VERSION "2021.24.4"

NS_ :

BS_:

BU_: VEH CH Receiver X

BO_ 964 PCS_info: 8 VEH
 SG_ PCS_infoIndex M: 0|8@1+ (1,0) [0|0] "" X
 SG_ PCS_buildType m10: 8|8@1+ (1,0) [0|0] "" X
 SG_ PCS_buildConfigId m10: 16|16@1+ (1,0) [0|0] "" X
 SG_ PCS_hardwareId m10: 32|16@1+ (1,0) [0|0] "" X
 SG_ PCS_componentId m10: 48|16@1+ (1,0) [0|0] "" X
 SG_ PCS_pcbaId m11: 16|8@1+ (1,0) [0|0] "" X
 SG_ PCS_assemblyId m11: 24|8@1+ (1,0) [0|0] "" X
 SG_ PCS_usageId m11: 32|16@1+ (1,0) [0|0] "" X
 SG_ PCS_subUsageId m11: 48|16@1+ (1,0) [0|0] "" X
 SG_ PCS_platformType m13: 8|8@1+ (1,0) [0|0] "" X
 SG_ PCS_appCrc m13: 32|32@1+ (1,0) [0|0] "" X
 SG_ PCS_cpu2AppCrc m16: 32|32@1+ (1,0) [0|0] "" X
 SG_ PCS_appGitHash m17: 10|54@1+ (4,0) [0|0] "" X
 SG_ PCS_bootGitHash m18: 10|54@1+ (4,0) [0|0] "" X
 SG_ PCS_bootUdsProtoVersion m20: 8|8@1+ (1,0) [0|0] "" X
 SG_ PCS_bootCrc m20: 32|32@1+ (1,0) [0|0] "" X
 SG_ PCS_partNumChar01 m25: 8|8@1+ (1,0) [0|0] "" X
 SG_ PCS_partNumChar02 m25: 16|8@1+ (1,0) [0|0] "" X
 SG_ PCS_partNumChar03 m25: 24|8@1+ (1,0) [0|0] "" X
 SG_ PCS_partNumChar04 m25: 32|8@1+ (1,0) [0|0] "" X
 SG_ PCS_partNumChar05 m25: 40|8@1+ (1,0) [0|0] "" X
 SG_ PCS_partNumChar06 m25: 48|8@1+ (1,0) [0|0] "" X
 SG_ PCS_partNumChar07 m25: 56|8@1+ (1,0) [0|0] "" X
 SG_ PCS_partNumChar08 m26: 8|8@1+ (1,0) [0|0] "" X
 SG_ PCS_partNumChar09 m26: 16|8@1+ (1,0) [0|0] "" X
 SG_ PCS_partNumChar10 m26: 24|8@1+ (1,0) [0|0] "" X
 SG_ PCS_partNumChar11 m26: 32|8@1+ (1,0) [0|0] "" X
 SG_ PCS_partNumChar12 m26: 40|8@1+ (1,0) [0|0] "" X
 SG_ PCS_partNumChar13 m26: 48|8@1+ (1,0) [0|0] "" X
 SG_ PCS_partNumChar14 m26: 56|8@1+ (1,0) [0|0] "" X
 SG_ PCS_partNumChar15 m27: 8|8@1+ (1,0) [0|0] "" X
 SG_ PCS_partNumChar16 m27: 16|8@1+ (1,0) [0|0] "" X
 SG_ PCS_partNumChar17 m27: 24|8@1+ (1,0) [0|0] "" X
 SG_ PCS_partNumChar18 m27: 32|8@1+ (1,0) [0|0] "" X
 SG_ PCS_partNumChar19 m27: 40|8@1+ (1,0) [0|0] "" X
 SG_ PCS_partNumChar20 m27: 48|8@1+ (1,0) [0|0] "" X
 SG_ PCS_serialNumChar01 m29: 8|8@1+ (1,0) [0|0] "" X
 SG_ PCS_serialNumChar02 m29: 16|8@1+ (1,0) [0|0] "" X
 SG_ PCS_serialNumChar03 m29: 24|8@1+ (1,0) [0|0] "" X
 SG_ PCS_serialNumChar04 m29: 32|8@1+ (1,0) [0|0] "" X
 SG_ PCS_serialNumChar05 m29: 40|8@1+ (1,0) [0|0] "" X
 SG_ PCS_serialNumChar06 m29: 48|8@1+ (1,0) [0|0] "" X
 SG_ PCS_serialNumChar07 m29: 56|8@1+ (1,0) [0|0] "" X
 SG_ PCS_serialNumChar08 m30: 8|8@1+ (1,0) [0|0] "" X
 SG_ PCS_serialNumChar09 m30: 16|8@1+ (1,0) [0|0] "" X
 SG_ PCS_serialNumChar10 m30: 24|8@1+ (1,0) [0|0] "" X
 SG_ PCS_serialNumChar11 m30: 32|8@1+ (1,0) [0|0] "" X
 SG_ PCS_serialNumChar12 m30: 40|8@1+ (1,0) [0|0] "" X
 SG_ PCS_serialNumChar13 m30: 48|8@1+ (1,0) [0|0] "" X
 SG_ PCS_serialNumChar14 m30: 56|8@1+ (1,0) [0|0] "" X

BO_ 708 PCS_logging: 8 VEH
 SG_ PCS_logMessageSelect M: 0|5@1+ (1,0) [0|0] "" X
 SG_ PCS_chgPhAInputIrms m0: 5|9@1+ (0.1,0) [0|0] "A" X
 SG_ PCS_chgPhAIntBusV m0: 14|9@1+ (1,0) [0|0] "V" X
 SG_ PCS_chgPhAIntBusVTarget m0: 23|9@1+ (1,0) [0|0] "V" X
 SG_ PCS_chgPhAOutputI m0: 32|8@1+ (0.1,0) [0|0] "A" X
 SG_ PCS_chgPhBInputIrms m1: 5|9@1+ (0.1,0) [0|0] "A" X
 SG_ PCS_chgPhBIntBusV m1: 14|9@1+ (1,0) [0|0] "V" X
 SG_ PCS_chgPhBIntBusVTarget m1: 23|9@1+ (1,0) [0|0] "V" X
 SG_ PCS_chgPhBOutputI m1: 32|8@1+ (0.1,0) [0|0] "A" X
 SG_ PCS_chgPhCInputIrms m2: 5|9@1+ (0.1,0) [0|0] "A" X
 SG_ PCS_chgPhCIntBusV m2: 14|9@1+ (1,0) [0|0] "V" X
 SG_ PCS_chgPhCIntBusVTarget m2: 23|9@1+ (1,0) [0|0] "V" X
 SG_ PCS_chgPhCOutputI m2: 32|8@1+ (0.1,0) [0|0] "A" X
 SG_ PCS_chgInputL1NVrms m3: 5|12@1+ (0.2,0) [0|0] "V" X
 SG_ PCS_chgInputL2NVrms m3: 17|12@1+ (0.2,0) [0|0] "V" X
 SG_ PCS_chgInputL3NVrms m3: 29|12@1+ (0.2,0) [0|0] "V" X
 SG_ PCS_chgInputL1L2Vrms m3: 41|12@1+ (0.2,0) [0|0] "V" X
 SG_ PCS_chgInputNGVrms m3: 53|9@1+ (1,0) [0|0] "V" X
 SG_ PCS_chgInputFrequencyL1N m4: 8|12@1+ (0.01,40) [0|0] "Hz" X
 SG_ PCS_chgInputFrequencyL2N m4: 20|12@1+ (0.01,40) [0|0] "Hz" X
 SG_ PCS_chgInputFrequencyL3N m4: 32|12@1+ (0.01,40) [0|0] "Hz" X
 SG_ PCS_chgInternalPhaseConfig m4: 44|3@1+ (1,0) [0|0] "" X
 SG_ PCS_chgOutputV m4: 48|12@1+ (0.146484,0) [0|0] "V" X
 SG_ PCS_chgPhAState m5: 5|4@1+ (1,0) [0|0] "" X
 SG_ PCS_chgPhBState m5: 9|4@1+ (1,0) [0|0] "" X
 SG_ PCS_chgPhCState m5: 13|4@1+ (1,0) [0|0] "" X
 SG_ PCS_chgPhALastShutdownReason m5: 17|5@1+ (1,0) [0|0] "" X
 SG_ PCS_chgPhBLastShutdownReason m5: 22|5@1+ (1,0) [0|0] "" X
 SG_ PCS_chgPhCLastShutdownReason m5: 27|5@1+ (1,0) [0|0] "" X
 SG_ PCS_chgPhARetryCount m5: 32|3@1+ (1,0) [0|0] "" X
 SG_ PCS_chgPhBRetryCount m5: 35|3@1+ (1,0) [0|0] "" X
 SG_ PCS_chgPhCRetryCount m5: 38|3@1+ (1,0) [0|0] "" X
 SG_ PCS_chgRetryCount m5: 41|3@1+ (1,0) [0|0] "" X
 SG_ PCS_chgPhManCurrentToDist m5: 44|10@1+ (0.1,0) [0|0] "A" X
 SG_ PCS_chgL1NPllLocked m5: 54|1@1+ (1,0) [0|0] "" X
 SG_ PCS_chgL2NPllLocked m5: 55|1@1+ (1,0) [0|0] "" X
 SG_ PCS_chgL3NPllLocked m5: 56|1@1+ (1,0) [0|0] "" X
 SG_ PCS_chgL1L2PllLocked m5: 57|1@1+ (1,0) [0|0] "" X
 SG_ PCS_chgNgPllLocked m5: 58|1@1+ (1,0) [0|0] "" X
 SG_ PCS_chgPhManOptimalPhsToUse m5: 59|2@1+ (1,0) [0|0] "" X
 SG_ PCS_chg5VL1Enable m5: 61|1@1+ (1,0) [0|0] "" X
 SG_ PCS_dcdcMaxLvOutputCurrent m6: 28|12@1+ (0.1,0) [0|0] "A" X
 SG_ PCS_dcdcCurrentLimit m6: 40|12@1+ (0.1,0) [0|0] "A" X
 SG_ PCS_dcdcLvOutputCurrentTempLimit m6: 52|12@1+ (0.1,0) [0|0] "A" X
 SG_ PCS_dcdcUnifiedCommand m7: 5|10@1+ (0.001,0) [0|0] "1" X
 SG_ PCS_dcdcCLAControllerOutput m7: 16|10@1+ (0.001,0) [0|0] "1" X
 SG_ PCS_dcdcTankVoltage m7: 26|11@1- (1,0) [0|0] "V" X
 SG_ PCS_dcdcTankVoltageTarget m7: 37|10@1+ (1,0) [0|0] "V" X
 SG_ PCS_dcdcClaCurrentFreq m7: 48|12@1+ (0.0976563,0) [0|0] "kHz" X
 SG_ PCS_dcdcTCommMeasured m8: 8|16@1- (0.00195313,0) [0|0] "us" X
 SG_ PCS_dcdcShortTimeUs m8: 24|16@1+ (0.000488281,0) [0|0] "us" X
 SG_ PCS_dcdcHalfPeriodUs m8: 40|16@1+ (0.000488281,0) [0|0] "us" X
 SG_ PCS_cpu2BootState m9: 5|2@1+ (1,0) [0|0] "" X
 SG_ PCS_acChargeSelfTestState m9: 7|1@1+ (1,0) [0|0] "" X
 SG_ PCS_1V5Min10s m9: 8|11@1+ (0.001,0) [0|0] "V" X
 SG_ PCS_1V5Max10s m9: 19|11@1+ (0.001,0) [0|0] "V" X
 SG_ PCS_1V2Min10s m9: 32|11@1+ (0.001,0) [0|0] "V" X
 SG_ PCS_1V2Max10s m9: 43|11@1+ (0.001,0) [0|0] "V" X
 SG_ PCS_numAlertsSet m9: 56|7@1+ (1,0) [0|0] "" X
 SG_ PCS_chgPhAIntBusVMin10s m10: 5|9@1+ (1,0) [0|0] "V" X
 SG_ PCS_chgPhAIntBusVMax10s m10: 14|9@1+ (1,0) [0|0] "V" X
 SG_ PCS_chgPhAPchgVoltDeltaMax10s m10: 23|8@1+ (0.5,0) [0|0] "V" X
 SG_ PCS_chgPhALifetimekWh m10: 31|24@1+ (0.01,0) [0|0] "kWh" X
 SG_ PCS_chgPhATransientRetryCount m10: 55|9@1+ (0.1,0) [0|0] "-" X
 SG_ PCS_chgPhBIntBusVMin10s m11: 5|9@1+ (1,0) [0|0] "V" X
 SG_ PCS_chgPhBIntBusVMax10s m11: 14|9@1+ (1,0) [0|0] "V" X
 SG_ PCS_chgPhBPchgVoltDeltaMax10s m11: 23|8@1+ (0.5,0) [0|0] "V" X
 SG_ PCS_chgPhBLifetimekWh m11: 31|24@1+ (0.01,0) [0|0] "kWh" X
 SG_ PCS_chgPhBTransientRetryCount m11: 55|9@1+ (0.1,0) [0|0] "-" X
 SG_ PCS_chgPhCIntBusVMin10s m12: 5|9@1+ (1,0) [0|0] "V" X
 SG_ PCS_chgPhCIntBusVMax10s m12: 14|9@1+ (1,0) [0|0] "V" X
 SG_ PCS_chgPhCPchgVoltDeltaMax10s m12: 23|8@1+ (0.5,0) [0|0] "V" X
 SG_ PCS_chgPhCLifetimekWh m12: 31|24@1+ (0.01,0) [0|0] "kWh" X
 SG_ PCS_chgPhCTransientRetryCount m12: 55|9@1+ (0.1,0) [0|0] "-" X
 SG_ PCS_chgInputL1NVPeak10s m13: 5|9@1+ (1,0) [0|0] "V" X
 SG_ PCS_chgInputL2NVPeak10s m13: 14|9@1+ (1,0) [0|0] "V" X
 SG_ PCS_chgInputL3NVPeak10s m13: 23|9@1+ (1,0) [0|0] "V" X
 SG_ PCS_chgInputFreqWobblePHAPeak m13: 32|8@1+ (0.01,0) [0|0] "Hz" X
 SG_ PCS_chgInputFreqWobblePHBPeak m13: 40|8@1+ (0.01,0) [0|0] "Hz" X
 SG_ PCS_chgInputFreqWobblePHCPeak m13: 48|8@1+ (0.01,0) [0|0] "Hz" X
 SG_ PCS_dLogPhAChannel1Content m14: 5|2@1+ (1,0) [0|0] "" X
 SG_ PCS_dLogPhBChannel1Content m14: 8|2@1+ (1,0) [0|0] "" X
 SG_ PCS_dLogPhCChannel1Content m14: 10|2@1+ (1,0) [0|0] "" X
 SG_ PCS_dLogPhAChannel1Data m14: 16|16@1- (0.02,0) [0|0] "-" X
 SG_ PCS_dLogPhBChannel1Data m14: 32|16@1- (0.02,0) [0|0] "-" X
 SG_ PCS_dLogPhCChannel1Data m14: 48|16@1- (0.02,0) [0|0] "-" X
 SG_ PCS_dLogPhAChannel2Content m15: 5|2@1+ (1,0) [0|0] "" X
 SG_ PCS_dLogPhBChannel2Content m15: 8|2@1+ (1,0) [0|0] "" X
 SG_ PCS_dLogPhCChannel2Content m15: 10|2@1+ (1,0) [0|0] "" X
 SG_ PCS_dLogPhAChannel2Data m15: 16|16@1- (0.02,0) [0|0] "-" X
 SG_ PCS_dLogPhBChannel2Data m15: 32|16@1- (0.02,0) [0|0] "-" X
 SG_ PCS_dLogPhCChannel2Data m15: 48|16@1- (0.02,0) [0|0] "-" X
 SG_ PCS_dLogPhAChannel3Content m16: 5|2@1+ (1,0) [0|0] "" X
 SG_ PCS_dLogPhBChannel3Content m16: 8|2@1+ (1,0) [0|0] "" X
 SG_ PCS_dLogPhCChannel3Content m16: 10|2@1+ (1,0) [0|0] "" X
 SG_ PCS_dLogPhAChannel3Data m16: 16|16@1- (0.02,0) [0|0] "-" X
 SG_ PCS_dLogPhBChannel3Data m16: 32|16@1- (0.02,0) [0|0] "-" X
 SG_ PCS_dLogPhCChannel3Data m16: 48|16@1- (0.02,0) [0|0] "-" X
 SG_ PCS_dLogPhAChannel4Content m17: 5|2@1+ (1,0) [0|0] "" X
 SG_ PCS_dLogPhBChannel4Content m17: 8|2@1+ (1,0) [0|0] "" X
 SG_ PCS_dLogPhCChannel4Content m17: 10|2@1+ (1,0) [0|0] "" X
 SG_ PCS_dLogPhAChannel4Data m17: 16|16@1- (0.02,0) [0|0] "-" X
 SG_ PCS_dLogPhBChannel4Data m17: 32|16@1- (0.02,0) [0|0] "-" X
 SG_ PCS_dLogPhCChannel4Data m17: 48|16@1- (0.02,0) [0|0] "-" X
 SG_ PCS_dcdcIntervalMaxFrequency m18: 8|12@1+ (1,0) [0|0] "kHz" X
 SG_ PCS_dcdcIntervalMaxHvBusVolt m18: 24|13@1+ (0.1,0) [0|0] "V" X
 SG_ PCS_dcdcIntervalMaxLvBusVolt m18: 37|9@1+ (0.1,0) [0|0] "V" X
 SG_ PCS_dcdcIntervalMaxLvOutputCurr m18: 48|12@1+ (1,0) [0|0] "A" X
 SG_ PCS_dcdcIntervalMinFrequency m19: 8|12@1+ (1,0) [0|0] "kHz" X
 SG_ PCS_dcdcIntervalMinHvBusVolt m19: 24|13@1+ (0.1,0) [0|0] "V" X
 SG_ PCS_dcdcIntervalMinLvBusVolt m19: 37|9@1+ (0.1,0) [0|0] "V" X
 SG_ PCS_dcdcIntervalMinLvOutputCurr m19: 48|12@1+ (1,0) [0|0] "A" X
 SG_ PCS_chgPhANoFlowBucket m20: 5|9@1+ (0.01,0) [0|0] "-" X
 SG_ PCS_chgPhBNoFlowBucket m20: 14|9@1+ (0.01,0) [0|0] "-" X
 SG_ PCS_chgPhCNoFlowBucket m20: 23|9@1+ (0.01,0) [0|0] "-" X
 SG_ PCS_chgInputL1NVdc m21: 5|10@1- (1,0) [0|0] "V" X
 SG_ PCS_chgInputL2NVdc m21: 16|10@1- (1,0) [0|0] "V" X
 SG_ PCS_chgInputL3NVdc m21: 26|10@1- (1,0) [0|0] "V" X
 SG_ PCS_chgInputL1L2Vdc m21: 36|10@1- (1,0) [0|0] "V" X
 SG_ PCS_chgInputNGVdc m21: 46|10@1- (1,0) [0|0] "V" X
 SG_ PCS_dcdc12vSupportLifetimekWh m22: 8|24@1+ (0.01,0) [0|0] "kWh" X

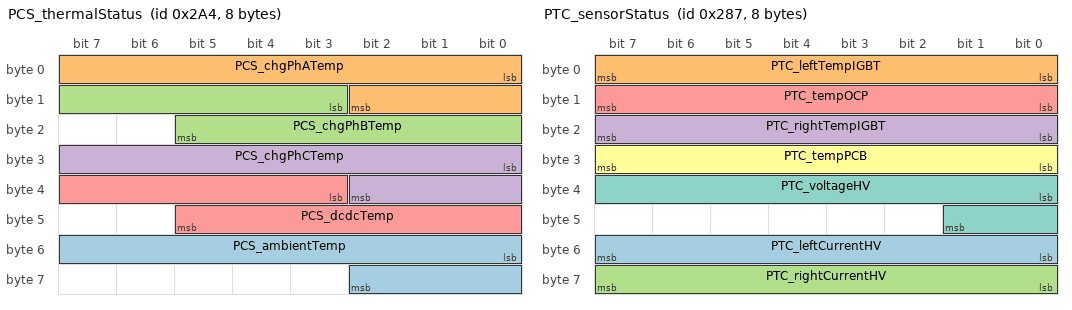
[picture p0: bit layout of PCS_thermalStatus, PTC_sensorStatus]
BO_ 676 PCS_thermalStatus: 8 VEH
 SG_ PCS_ambientTemp: 48|11@1- (0.1,40) [0|0] "C" X
 SG_ PCS_chgPhATemp: 0|11@1- (0.1,40) [0|0] "C" X
 SG_ PCS_chgPhBTemp: 11|11@1- (0.1,40) [0|0] "C" X
 SG_ PCS_chgPhCTemp: 24|11@1- (0.1,40) [0|0] "C" X
 SG_ PCS_dcdcTemp: 35|11@1- (0.1,40) [0|0] "C" X

BO_ 900 PMS_alertMatrix1: 8 VEH
 SG_ PMS_w001_absoluteTorque: 0|1@1+ (1,0) [0|0] "" X
 SG_ PMS_w002_accumulatedTorque: 1|1@1+ (1,0) [0|0] "" X
 SG_ PMS_w003_torqueReversal: 2|1@1+ (1,0) [0|0] "" X
 SG_ PMS_w004_regenTorque: 3|1@1+ (1,0) [0|0] "" X
 SG_ PMS_w005_torqueInNeutral: 4|1@1+ (1,0) [0|0] "" X
 SG_ PMS_w006_inconsistentDIGear: 5|1@1+ (1,0) [0|0] "" X
 SG_ PMS_w007_watchdogReset: 6|1@1+ (1,0) [0|0] "" X
 SG_ PMS_w008_memoryError: 7|1@1+ (1,0) [0|0] "" X
 SG_ PMS_w009_espMIA: 8|1@1+ (1,0) [0|0] "" X
 SG_ PMS_w010_diMIA: 9|1@1+ (1,0) [0|0] "" X
 SG_ PMS_w011_phaseCurrentIrrational: 10|1@1+ (1,0) [0|0] "" X
 SG_ PMS_w012_canDataBusA: 11|1@1+ (1,0) [0|0] "" X
 SG_ PMS_w013_canHardwareBusA: 12|1@1+ (1,0) [0|0] "" X
 SG_ PMS_w018_encoderIrrational: 17|1@1+ (1,0) [0|0] "" X
 SG_ PMS_w019_statorTempIrrational: 18|1@1+ (1,0) [0|0] "" X
 SG_ PMS_w026_diHeartBeatMIA: 25|1@1+ (1,0) [0|0] "" X
 SG_ PMS_w027_torqueOutOfMap: 26|1@1+ (1,0) [0|0] "" X
 SG_ PMS_w028_torqueCmdError: 27|1@1+ (1,0) [0|0] "" X
 SG_ PMS_w031_highStackUsage: 30|1@1+ (1,0) [0|0] "" X
 SG_ PMS_w032_registerConfigError: 31|1@1+ (1,0) [0|0] "" X
 SG_ PMS_w033_selfTest: 32|1@1+ (1,0) [0|0] "" X
 SG_ PMS_w034_trqCrossCheck: 33|1@1+ (1,0) [0|0] "" X
 SG_ PMS_w038_inconsistentTorqueSign: 37|1@1+ (1,0) [0|0] "" X
 SG_ PMS_w039_disMIA: 38|1@1+ (1,0) [0|0] "" X
 SG_ PMS_w040_pmMIA: 39|1@1+ (1,0) [0|0] "" X
 SG_ PMS_w042_gtwMIA: 41|1@1+ (1,0) [0|0] "" X
 SG_ PMS_w043_inconsistentConfig: 42|1@1+ (1,0) [0|0] "" X
 SG_ PMS_w045_motorMovementDetected: 44|1@1+ (1,0) [0|0] "" X
 SG_ PMS_w053_vcfrontMIA: 52|1@1+ (1,0) [0|0] "" X
 SG_ PMS_w054_uiMIA: 53|1@1+ (1,0) [0|0] "" X
 SG_ PMS_w055_resolver: 54|1@1+ (1,0) [0|0] "" X
 SG_ PMS_w056_canHardwareBusB: 55|1@1+ (1,0) [0|0] "" X
 SG_ PMS_w057_canDataBusB: 56|1@1+ (1,0) [0|0] "" X
 SG_ PMS_w061_DIPMVersionMismatch: 60|1@1+ (1,0) [0|0] "" X
 SG_ PMS_w063_debugAlert: 62|1@1+ (1,0) [0|0] "" X
 SG_ PMS_w064_torqueIntervention: 63|1@1+ (1,0) [0|0] "" X

BO_ 1748 PMS_info: 8 VEH
 SG_ PMS_infoIndex M: 0|8@1+ (1,0) [0|0] "" X
 SG_ PMS_buildType m10: 8|8@1+ (1,0) [0|0] "" X
 SG_ PMS_buildConfigurationId m10: 16|16@1+ (1,0) [0|0] "" X
 SG_ PMS_hardwareId m10: 32|8@1+ (1,0) [0|0] "" X
 SG_ PMS_componentId m10: 48|16@1+ (1,0) [0|0] "" X
 SG_ PMS_pcbaId m11: 16|8@1+ (1,0) [0|0] "" X
 SG_ PMS_assemblyId m11: 24|8@1+ (1,0) [0|0] "" X
 SG_ PMS_usageId m11: 32|16@1+ (1,0) [0|0] "" X
 SG_ PMS_subUsageId m11: 48|16@1+ (1,0) [0|0] "" X
 SG_ PMS_applicationCrc m13: 32|32@1+ (1,0) [0|0] "" X
 SG_ PMS_bootloaderSvnRevision m14: 8|24@1+ (1,0) [0|0] "" X
 SG_ PMS_bootloaderSvnUrlHash m14: 32|32@1+ (1,0) [0|0] "" X
 SG_ PMS_appGitHash m17: 10|54@1+ (4,0) [0|0] "" X
 SG_ PMS_bootGitHash m18: 10|54@1+ (4,0) [0|0] "" X
 SG_ PMS_platformTyp m19: 8|8@1+ (1,0) [0|0] "" X
 SG_ PMS_udsProtocolVersion m20: 8|8@1+ (1,0) [0|0] "" X
 SG_ PMS_bootloaderCrc m20: 32|32@1+ (1,0) [0|0] "" X

BO_ 772 PM_alertMatrix1: 8 VEH
 SG_ PM_a001_absoluteTorque: 0|1@1+ (1,0) [0|0] "" X
 SG_ PM_a002_accumulatedTorque: 1|1@1+ (1,0) [0|0] "" X
 SG_ PM_a003_torqueReversal: 2|1@1+ (1,0) [0|0] "" X
 SG_ PM_a004_regenTorque: 3|1@1+ (1,0) [0|0] "" X
 SG_ PM_a005_torqueInNeutral: 4|1@1+ (1,0) [0|0] "" X
 SG_ PM_a006_inconsistentDIGear: 5|1@1+ (1,0) [0|0] "" X
 SG_ PM_a007_watchdogReset: 6|1@1+ (1,0) [0|0] "" X
 SG_ PM_a008_memoryError: 7|1@1+ (1,0) [0|0] "" X
 SG_ PM_a009_espMIA: 8|1@1+ (1,0) [0|0] "" X
 SG_ PM_a010_diMIA: 9|1@1+ (1,0) [0|0] "" X
 SG_ PM_a011_phaseCurrentIrrational: 10|1@1+ (1,0) [0|0] "" X
 SG_ PM_a012_canDataBusA: 11|1@1+ (1,0) [0|0] "" X
 SG_ PM_a013_canHardwareBusA: 12|1@1+ (1,0) [0|0] "" X
 SG_ PM_a014_accelPedalError: 13|1@1+ (1,0) [0|0] "" X
 SG_ PM_a015_shifterMIA: 14|1@1+ (1,0) [0|0] "" X
 SG_ PM_a016_cruiseMIA: 15|1@1+ (1,0) [0|0] "" X
 SG_ PM_a017_brakeMIA: 16|1@1+ (1,0) [0|0] "" X
 SG_ PM_a018_encoderIrrational: 17|1@1+ (1,0) [0|0] "" X
 SG_ PM_a019_statorTempIrrational: 18|1@1+ (1,0) [0|0] "" X
 SG_ PM_a023_crsCmdOffStateOn: 22|1@1+ (1,0) [0|0] "" X
 SG_ PM_a024_brakeIrrational: 23|1@1+ (1,0) [0|0] "" X
 SG_ PM_a026_diHeartBeatMIA: 25|1@1+ (1,0) [0|0] "" X
 SG_ PM_a027_torqueOutOfMap: 26|1@1+ (1,0) [0|0] "" X
 SG_ PM_a028_torqueCmdError: 27|1@1+ (1,0) [0|0] "" X
 SG_ PM_a030_inconsistentAebState: 29|1@1+ (1,0) [0|0] "" X
 SG_ PM_a031_highStackUsage: 30|1@1+ (1,0) [0|0] "" X
 SG_ PM_a032_registerConfigError: 31|1@1+ (1,0) [0|0] "" X
 SG_ PM_a033_selfTest: 32|1@1+ (1,0) [0|0] "" X
 SG_ PM_a034_trqCrossCheck: 33|1@1+ (1,0) [0|0] "" X
 SG_ PM_a038_inconsistentTorqueSign: 37|1@1+ (1,0) [0|0] "" X
 SG_ PM_a039_disMIA: 38|1@1+ (1,0) [0|0] "" X
 SG_ PM_a040_pmMIA: 39|1@1+ (1,0) [0|0] "" X
 SG_ PM_a041_dasMIA: 40|1@1+ (1,0) [0|0] "" X
 SG_ PM_a042_gtwMIA: 41|1@1+ (1,0) [0|0] "" X
 SG_ PM_a043_inconsistentConfig: 42|1@1+ (1,0) [0|0] "" X
 SG_ PM_a044_ebrIntervention: 43|1@1+ (1,0) [0|0] "" X
 SG_ PM_a045_motorMovementDetected: 44|1@1+ (1,0) [0|0] "" X
 SG_ PM_a046_inconsVehicleHoldState: 45|1@1+ (1,0) [0|0] "" X
 SG_ PM_a047_inconsAutoparkState: 46|1@1+ (1,0) [0|0] "" X
 SG_ PM_a048_stabilityControlInhibit: 47|1@1+ (1,0) [0|0] "" X
 SG_ PM_a049_stbCtrlInWrongDir: 48|1@1+ (1,0) [0|0] "" X
 SG_ PM_a050_excessiveStbCtrlTrq: 49|1@1+ (1,0) [0|0] "" X
 SG_ PM_a051_unintDecelStbCtrl: 50|1@1+ (1,0) [0|0] "" X
 SG_ PM_a052_stbCtrlDrvrDecelCflct: 51|1@1+ (1,0) [0|0] "" X
 SG_ PM_a053_vcfrontMIA: 52|1@1+ (1,0) [0|0] "" X
 SG_ PM_a054_uiMIA: 53|1@1+ (1,0) [0|0] "" X
 SG_ PM_a055_resolver: 54|1@1+ (1,0) [0|0] "" X
 SG_ PM_a056_canHardwareBusB: 55|1@1+ (1,0) [0|0] "" X
 SG_ PM_a057_canDataBusB: 56|1@1+ (1,0) [0|0] "" X
 SG_ PM_a058_cmpMIA: 57|1@1+ (1,0) [0|0] "" X
 SG_ PM_a059_ptcMIA: 58|1@1+ (1,0) [0|0] "" X
 SG_ PM_a061_DIPMVersionMismatch: 60|1@1+ (1,0) [0|0] "" X
 SG_ PM_a063_debugAlert: 62|1@1+ (1,0) [0|0] "" X
 SG_ PM_a064_torqueIntervention: 63|1@1+ (1,0) [0|0] "" X

BO_ 790 PM_info: 8 VEH
 SG_ PM_infoIndex M: 0|8@1+ (1,0) [0|0] "" X
 SG_ PM_buildType m10: 8|8@1+ (1,0) [0|0] "" X
 SG_ PM_buildConfigurationId m10: 16|16@1+ (1,0) [0|0] "" X
 SG_ PM_hardwareId m10: 32|8@1+ (1,0) [0|0] "" X
 SG_ PM_componentId m10: 48|16@1+ (1,0) [0|0] "" X
 SG_ PM_pcbaId m11: 16|8@1+ (1,0) [0|0] "" X
 SG_ PM_assemblyId m11: 24|8@1+ (1,0) [0|0] "" X
 SG_ PM_usageId m11: 32|16@1+ (1,0) [0|0] "" X
 SG_ PM_subUsageId m11: 48|16@1+ (1,0) [0|0] "" X
 SG_ PM_applicationCrc m13: 32|32@1+ (1,0) [0|0] "" X
 SG_ PM_bootloaderSvnRevision m14: 8|24@1+ (1,0) [0|0] "" X
 SG_ PM_bootloaderSvnUrlHash m14: 32|32@1+ (1,0) [0|0] "" X
 SG_ PM_appGitHash m17: 10|54@1+ (4,0) [0|0] "" X
 SG_ PM_bootGitHash m18: 10|54@1+ (4,0) [0|0] "" X
 SG_ PM_platformTyp m19: 8|8@1+ (1,0) [0|0] "" X
 SG_ PM_udsProtocolVersion m20: 8|8@1+ (1,0) [0|0] "" X
 SG_ PM_bootloaderCrc m20: 32|32@1+ (1,0) [0|0] "" X

BO_ 837 PTC_info: 8 VEH
 SG_ PTC_infoIndex M: 0|8@1+ (1,0) [0|0] "" X
 SG_ PTC_infoBuildType m10: 8|3@1+ (1,0) [0|0] "" X
 SG_ PTC_infoBuildConfigId m10: 16|16@1+ (1,0) [0|0] "" X
 SG_ PTC_infoHardwareId m10: 32|16@1+ (1,0) [0|0] "" X
 SG_ PTC_infoComponentId m10: 48|16@1+ (1,0) [0|0] "" X
 SG_ PTC_infoPcbaId m11: 16|8@1+ (1,0) [0|0] "" X
 SG_ PTC_infoAssemblyId m11: 24|8@1+ (1,0) [0|0] "" X
 SG_ PTC_infoUsageId m11: 32|16@1+ (1,0) [0|0] "" X
 SG_ PTC_infoSubUsageId m11: 48|16@1+ (1,0) [0|0] "" X
 SG_ PTC_infoBootUdsProtoVersion m20: 8|8@1+ (1,0) [0|0] "" X
 SG_ PTC_infoBootCrc m20: 32|32@1+ (1,0) [0|0] "" X
 SG_ PTC_infoPlatformType m13: 8|8@1+ (1,0) [0|0] "" X
 SG_ PTC_infoAppCrc m13: 32|32@1+ (1,0) [0|0] "" X

BO_ 647 PTC_sensorStatus: 8 VEH
 SG_ PTC_leftCurrentHV: 48|8@1+ (0.2,0) [0|0] "A" X
 SG_ PTC_leftTempIGBT: 0|8@1+ (1,-40) [0|0] "degC" X
 SG_ PTC_rightCurrentHV: 56|8@1+ (0.2,0) [0|0] "A" X
 SG_ PTC_rightTempIGBT: 16|8@1+ (1,-40) [0|0] "degC" X
 SG_ PTC_tempOCP: 8|8@1+ (1,-40) [0|0] "degC" X
 SG_ PTC_tempPCB: 24|8@1+ (1,-40) [0|0] "degC" X
 SG_ PTC_voltageHV: 32|10@1+ (0.5,0) [0|0] "V" X

BO_ 1282 RADC_alertMatrix0: 8 CH
 SG_ RADC_a001_can1BusOff: 1|1@1+ (1,0) [0|0] "" X
 SG_ RADC_a002_ecuAdcError: 2|1@1+ (1,0) [0|0] "" X
 SG_ RADC_a003_ecuBistDisabled: 3|1@1+ (1,0) [0|0] "" X
 SG_ RADC_a004_ecuCrcHwError: 4|1@1+ (1,0) [0|0] "" X
 SG_ RADC_a005_ecuEcuMError: 5|1@1+ (1,0) [0|0] "" X
 SG_ RADC_a006_ecuFimError: 6|1@1+ (1,0) [0|0] "" X
 SG_ RADC_a007_ecuGptCheckError: 7|1@1+ (1,0) [0|0] "" X
 SG_ RADC_a008_ecuHwSwInterlock: 8|1@1+ (1,0) [0|0] "" X
 SG_ RADC_a009_plantModeActive: 9|1@1+ (1,0) [0|0] "" X
 SG_ RADC_a010_ecuIoHwAbError: 10|1@1+ (1,0) [0|0] "" X
 SG_ RADC_a011_ecuMcemError: 11|1@1+ (1,0) [0|0] "" X
 SG_ RADC_a012_ecuSpiError: 12|1@1+ (1,0) [0|0] "" X
 SG_ RADC_a013_ecuWdgError: 13|1@1+ (1,0) [0|0] "" X
 SG_ RADC_a014_fctSelfTestNotDone: 14|1@1+ (1,0) [0|0] "" X
 SG_ RADC_a015_fctSenInterference: 15|1@1+ (1,0) [0|0] "" X
 SG_ RADC_a016_adcOverVolt: 16|1@1+ (1,0) [0|0] "" X
 SG_ RADC_a017_adcUnderVolt: 17|1@1+ (1,0) [0|0] "" X
 SG_ RADC_a018_internalHardwareFault: 18|1@1+ (1,0) [0|0] "" X
 SG_ RADC_a019_internalSoftwareFault: 19|1@1+ (1,0) [0|0] "" X
 SG_ RADC_a020_overTemp: 20|1@1+ (1,0) [0|0] "" X
 SG_ RADC_a021_overTempCrit: 21|1@1+ (1,0) [0|0] "" X
 SG_ RADC_a022_tempImplausible: 22|1@1+ (1,0) [0|0] "" X
 SG_ RADC_a023_underTemp: 23|1@1+ (1,0) [0|0] "" X
 SG_ RADC_a024_underTempCrit: 24|1@1+ (1,0) [0|0] "" X
 SG_ RADC_a025_overVoltage: 25|1@1+ (1,0) [0|0] "" X
 SG_ RADC_a026_underVoltage: 26|1@1+ (1,0) [0|0] "" X
 SG_ RADC_a027_nvmFailure: 27|1@1+ (1,0) [0|0] "" X
 SG_ RADC_a028_rfChipError: 28|1@1+ (1,0) [0|0] "" X
 SG_ RADC_a029_rhcError: 29|1@1+ (1,0) [0|0] "" X
 SG_ RADC_a030_rspError: 30|1@1+ (1,0) [0|0] "" X
 SG_ RADC_a031_sensorMisaligned: 31|1@1+ (1,0) [0|0] "" X
 SG_ RADC_a032_sensorBlocked: 32|1@1+ (1,0) [0|0] "" X
 SG_ RADC_a033_sensorNeverAligned: 33|1@1+ (1,0) [0|0] "" X
 SG_ RADC_a034_vehDynamicsError: 34|1@1+ (1,0) [0|0] "" X
 SG_ RADC_a035_vinMIA: 35|1@1+ (1,0) [0|0] "" X
 SG_ RADC_a036_carConfigMIA: 36|1@1+ (1,0) [0|0] "" X
 SG_ RADC_a037_inertialSignalsMIA: 37|1@1+ (1,0) [0|0] "" X
 SG_ RADC_a038_steeringWheelAngleMIA: 38|1@1+ (1,0) [0|0] "" X
 SG_ RADC_a039_vehicleStateMIA: 39|1@1+ (1,0) [0|0] "" X
 SG_ RADC_a040_wheelSpeedsMIA: 40|1@1+ (1,0) [0|0] "" X
 SG_ RADC_a041_vinErr: 41|1@1+ (1,0) [0|0] "" X
 SG_ RADC_a042_carConfigErr: 42|1@1+ (1,0) [0|0] "" X
 SG_ RADC_a043_inertialSignalsErr: 43|1@1+ (1,0) [0|0] "" X
 SG_ RADC_a044_steeringWheelAngleErr: 44|1@1+ (1,0) [0|0] "" X
 SG_ RADC_a045_vehicleStateErr: 45|1@1+ (1,0) [0|0] "" X
 SG_ RADC_a046_wheelSpeedsErr: 46|1@1+ (1,0) [0|0] "" X
 SG_ RADC_a047_mismatchChassisType: 47|1@1+ (1,0) [0|0] "" X
 SG_ RADC_a048_mismatchAirSuspension: 48|1@1+ (1,0) [0|0] "" X
 SG_ RADC_a049_mismatchFourWheelDrive: 49|1@1+ (1,0) [0|0] "" X
 SG_ RADC_a050_mismatchCountry: 50|1@1+ (1,0) [0|0] "" X
 SG_ RADC_a051_mismatchEPASType: 51|1@1+ (1,0) [0|0] "" X
 SG_ RADC_a052_mismatcRadPos: 52|1@1+ (1,0) [0|0] "" X
 SG_ RADC_a053_emError: 53|1@1+ (1,0) [0|0] "" X
 SG_ RADC_a054_blockageInfo_Frame_1: 54|1@1+ (1,0) [0|0] "" X
 SG_ RADC_a055_blockageInfo_Frame_2: 55|1@1+ (1,0) [0|0] "" X

BO_ 1329 RADC_info: 8 CH
 SG_ RADC_infoIndex M: 0|8@1+ (1,0) [0|0] "" X
 SG_ RADC_infoPlatformType m19: 8|8@1+ (1,0) [0|0] "" X
 SG_ RADC_infoMajorVersion m19: 16|8@1+ (1,0) [0|0] "" X
 SG_ RADC_infoBranchOrigin m19: 24|8@1+ (1,0) [0|0] "" X
 SG_ RADC_infoMaturity m19: 32|8@1+ (1,0) [0|0] "" X
 SG_ RADC_infoHardwareRevision m19: 40|8@1+ (1,0) [0|0] "" X
 SG_ RADC_infoBuildType m10: 8|8@1+ (1,0) [0|0] "" X
 SG_ RADC_infoBuildConfigID m10: 16|16@1+ (1,0) [0|0] "" X
 SG_ RADC_infoHardwareID m10: 32|16@1+ (1,0) [0|0] "" X
 SG_ RADC_infoComponentID m10: 48|16@1+ (1,0) [0|0] "" X
 SG_ RADC_infoPcbaID m11: 16|8@1+ (1,0) [0|0] "" X
 SG_ RADC_infoAssemblyID m11: 24|8@1+ (1,0) [0|0] "" X
 SG_ RADC_infoUsageID m11: 32|16@1+ (1,0) [0|0] "" X
 SG_ RADC_infoSubUsageID m11: 48|16@1+ (1,0) [0|0] "" X
 SG_ RADC_infoBootUdsProtoVersion m20: 8|8@1+ (1,0) [0|0] "" X
 SG_ RADC_infoBootloaderCRC m20: 32|32@1+ (1,0) [0|0] "" X
 SG_ RADC_infoApplicationCRC m13: 32|32@1+ (1,0) [0|0] "" X

BO_ 881 RCM_alertMatrix: 8 VEH
 SG_ RCM_matrixIndex M: 0|4@1+ (1,0) [0|0] "" X
 SG_ RCM_a000_crashDetected m0: 4|1@1+ (1,0) [0|0] "" X
 SG_ RCM_a001_nearDeploy m0: 5|1@1+ (1,0) [0|0] "" X
 SG_ RCM_a002_airbagsNotArmed m0: 6|1@1+ (1,0) [0|0] "" X
 SG_ RCM_a003_warningIndicator m0: 7|1@1+ (1,0) [0|0] "" X
 SG_ RCM_a004_internalFault m0: 8|1@1+ (1,0) [0|0] "" X
 SG_ RCM_a005_crcError m0: 9|1@1+ (1,0) [0|0] "" X
 SG_ RCM_a006_batteryVoltageRange m0: 10|1@1+ (1,0) [0|0] "" X
 SG_ RCM_a007_powerSupplyExternal m0: 11|1@1+ (1,0) [0|0] "" X
 SG_ RCM_a008_powerSupplyInternal m0: 12|1@1+ (1,0) [0|0] "" X
 SG_ RCM_a009_reprogramLimit m0: 13|1@1+ (1,0) [0|0] "" X
 SG_ RCM_a010_scmDisabled m0: 14|1@1+ (1,0) [0|0] "" X
 SG_ RCM_a011_eepromDataLocked m0: 15|1@1+ (1,0) [0|0] "" X
 SG_ RCM_a012_vinStorage m0: 16|1@1+ (1,0) [0|0] "" X
 SG_ RCM_a013_driverOrientation m0: 17|1@1+ (1,0) [0|0] "" X
 SG_ RCM_a014_driverABStage1 m0: 18|1@1+ (1,0) [0|0] "" X
 SG_ RCM_a015_driverABStage2 m0: 19|1@1+ (1,0) [0|0] "" X
 SG_ RCM_a016_passABStage1 m0: 20|1@1+ (1,0) [0|0] "" X
 SG_ RCM_a017_passABStage2 m0: 21|1@1+ (1,0) [0|0] "" X
 SG_ RCM_a018_passengerActiveVent m0: 22|1@1+ (1,0) [0|0] "" X
 SG_ RCM_a019_pretenShldrFrontLeft m0: 23|1@1+ (1,0) [0|0] "" X
 SG_ RCM_a020_pretenShldFrontRight m0: 24|1@1+ (1,0) [0|0] "" X
 SG_ RCM_a021_pretenLapFrontLeft m0: 25|1@1+ (1,0) [0|0] "" X
 SG_ RCM_a022_pretenLapFrontRight m0: 26|1@1+ (1,0) [0|0] "" X
 SG_ RCM_a023_loadLimiterLeftSide m0: 27|1@1+ (1,0) [0|0] "" X
 SG_ RCM_a024_loadLimiterRightSide m0: 28|1@1+ (1,0) [0|0] "" X
 SG_ RCM_a025_kneeABDriver m0: 29|1@1+ (1,0) [0|0] "" X
 SG_ RCM_a026_kneeABFrontPassenger m0: 30|1@1+ (1,0) [0|0] "" X
 SG_ RCM_a027_sideAB1stRowLeft m0: 31|1@1+ (1,0) [0|0] "" X
 SG_ RCM_a028_sideAB1stRowRight m0: 32|1@1+ (1,0) [0|0] "" X
 SG_ RCM_a029_driverABActiveVent m0: 33|1@1+ (1,0) [0|0] "" X
 SG_ RCM_a030_farSideInboardAirbag m0: 34|1@1+ (1,0) [0|0] "" X
 SG_ RCM_a031_frontCenterAirbag m0: 35|1@1+ (1,0) [0|0] "" X
 SG_ RCM_a032_curtainABLeft m0: 36|1@1+ (1,0) [0|0] "" X
 SG_ RCM_a033_curtainABRight m0: 37|1@1+ (1,0) [0|0] "" X
 SG_ RCM_a034_preten2ndRowLeft m0: 38|1@1+ (1,0) [0|0] "" X
 SG_ RCM_a035_preten2ndRowRight m0: 39|1@1+ (1,0) [0|0] "" X
 SG_ RCM_a036_curAB2ndRowLeft m0: 40|1@1+ (1,0) [0|0] "" X
 SG_ RCM_a037_curAB2ndRowRight m0: 41|1@1+ (1,0) [0|0] "" X
 SG_ RCM_a038_unusedA m0: 42|1@1+ (1,0) [0|0] "" X
 SG_ RCM_a039_unusedB m0: 43|1@1+ (1,0) [0|0] "" X
 SG_ RCM_a040_hoodActuatorRight m0: 44|1@1+ (1,0) [0|0] "" X
 SG_ RCM_a041_hoodActuatorLeft m0: 45|1@1+ (1,0) [0|0] "" X
 SG_ RCM_a042_ens1Line m0: 46|1@1+ (1,0) [0|0] "" X
 SG_ RCM_a043_ens2Line m0: 47|1@1+ (1,0) [0|0] "" X
 SG_ RCM_a044_upFrontSensorLeft m0: 48|1@1+ (1,0) [0|0] "" X
 SG_ RCM_a045_upFrontSensorRight m0: 49|1@1+ (1,0) [0|0] "" X
 SG_ RCM_a046_sideAccelBPillarLeft m0: 50|1@1+ (1,0) [0|0] "" X
 SG_ RCM_a047_sideAccelBPillarRight m0: 51|1@1+ (1,0) [0|0] "" X
 SG_ RCM_a048_sideAccelCPillarLeft m0: 52|1@1+ (1,0) [0|0] "" X
 SG_ RCM_a049_sideAccelCPillarRight m0: 53|1@1+ (1,0) [0|0] "" X
 SG_ RCM_a050_upFrontSensorCenter m0: 54|1@1+ (1,0) [0|0] "" X
 SG_ RCM_a051_pressureFrontLftDoor m0: 55|1@1+ (1,0) [0|0] "" X
 SG_ RCM_a052_pressureFrontRtDoor m0: 56|1@1+ (1,0) [0|0] "" X
 SG_ RCM_a053_pressurePedProLeft m0: 57|1@1+ (1,0) [0|0] "" X
 SG_ RCM_a054_pressurePedProRight m0: 58|1@1+ (1,0) [0|0] "" X
 SG_ RCM_a055_inertialMeasurement m0: 59|1@1+ (1,0) [0|0] "" X
 SG_ RCM_a056_passengerFrontOCS m0: 60|1@1+ (1,0) [0|0] "" X
 SG_ RCM_a057_driverOCS m0: 61|1@1+ (1,0) [0|0] "" X
 SG_ RCM_a058_buckle1stRowLeft m0: 62|1@1+ (1,0) [0|0] "" X
 SG_ RCM_a059_buckle1stRowRight m0: 63|1@1+ (1,0) [0|0] "" X
 SG_ RCM_a060_stpsLeft m1: 4|1@1+ (1,0) [0|0] "" X
 SG_ RCM_a061_stpsRight m1: 5|1@1+ (1,0) [0|0] "" X
 SG_ RCM_a062_alrSwitch m1: 6|1@1+ (1,0) [0|0] "" X
 SG_ RCM_a063_sbsw2ndRowRight m1: 7|1@1+ (1,0) [0|0] "" X
 SG_ RCM_a064_hardwareCodingPin1 m1: 8|1@1+ (1,0) [0|0] "" X
 SG_ RCM_a065_driverOrientConfigPin m1: 9|1@1+ (1,0) [0|0] "" X
 SG_ RCM_a066_seatBackSw2ndRowLeft m1: 10|1@1+ (1,0) [0|0] "" X
 SG_ RCM_a067_comCANInitFailure m1: 11|1@1+ (1,0) [0|0] "" X
 SG_ RCM_a068_comCHOff m1: 12|1@1+ (1,0) [0|0] "" X
 SG_ RCM_a069_comCHCANPH7 m1: 13|1@1+ (1,0) [0|0] "" X
 SG_ RCM_a070_comCHCANPH8 m1: 14|1@1+ (1,0) [0|0] "" X
 SG_ RCM_a071_comCHCANPH9 m1: 15|1@1+ (1,0) [0|0] "" X
 SG_ RCM_a072_comUnused m1: 16|1@1+ (1,0) [0|0] "" X
 SG_ RCM_a073_comCHCANPH4 m1: 17|1@1+ (1,0) [0|0] "" X
 SG_ RCM_a074_comCHCANPH5 m1: 18|1@1+ (1,0) [0|0] "" X
 SG_ RCM_a075_comCHCANPH6 m1: 19|1@1+ (1,0) [0|0] "" X
 SG_ RCM_a076_comEPBLStatus m1: 20|1@1+ (1,0) [0|0] "" X
 SG_ RCM_a077_comEPBRStatus m1: 21|1@1+ (1,0) [0|0] "" X
 SG_ RCM_a078_comOCS1PStatus m1: 22|1@1+ (1,0) [0|0] "" X
 SG_ RCM_a079_comOCS1DStatus m1: 23|1@1+ (1,0) [0|0] "" X
 SG_ RCM_a080_comGTWACS m1: 24|1@1+ (1,0) [0|0] "" X
 SG_ RCM_a081_comVCFRONTLVPwr m1: 25|1@1+ (1,0) [0|0] "" X
 SG_ RCM_a082_comUIodo m1: 26|1@1+ (1,0) [0|0] "" X
 SG_ RCM_a083_comGTWCarState m1: 27|1@1+ (1,0) [0|0] "" X
 SG_ RCM_a084_comTPMSStatus m1: 28|1@1+ (1,0) [0|0] "" X
 SG_ RCM_a085_comGTWCarConfig m1: 29|1@1+ (1,0) [0|0] "" X
 SG_ RCM_a086_comVINMIA m1: 30|1@1+ (1,0) [0|0] "" X
 SG_ RCM_a087_comCANSilent m1: 31|1@1+ (1,0) [0|0] "" X
 SG_ RCM_a088_comCHCANPH2 m1: 32|1@1+ (1,0) [0|0] "" X
 SG_ RCM_a089_comCHCANPH3 m1: 33|1@1+ (1,0) [0|0] "" X
 SG_ RCM_a090_comPartyBusOff m1: 34|1@1+ (1,0) [0|0] "" X
 SG_ RCM_a091_comEPAS3PsysStatus m1: 35|1@1+ (1,0) [0|0] "" X
 SG_ RCM_a092_comDASISF m1: 36|1@1+ (1,0) [0|0] "" X
 SG_ RCM_a093_comVCLEFTStatus m1: 37|1@1+ (1,0) [0|0] "" X
 SG_ RCM_a094_comVCRIGHTStatus m1: 38|1@1+ (1,0) [0|0] "" X
 SG_ RCM_a095_comESPstatus m1: 39|1@1+ (1,0) [0|0] "" X
 SG_ RCM_a096_comESPwheelSpeeds m1: 40|1@1+ (1,0) [0|0] "" X
 SG_ RCM_a097_comDIspeed m1: 41|1@1+ (1,0) [0|0] "" X
 SG_ RCM_a098_comDIchassisControl m1: 42|1@1+ (1,0) [0|0] "" X
 SG_ RCM_a099_comDItorque m1: 43|1@1+ (1,0) [0|0] "" X
 SG_ RCM_a100_comDIsystemStatus m1: 44|1@1+ (1,0) [0|0] "" X
 SG_ RCM_a101_idfSystem m1: 45|1@1+ (1,0) [0|0] "" X
 SG_ RCM_a102_imuYawR8OffstCompLim m1: 46|1@1+ (1,0) [0|0] "" X
 SG_ RCM_a103_imuPtchR8OffstCompLim m1: 47|1@1+ (1,0) [0|0] "" X
 SG_ RCM_a104_imuRollR8OffstCompLim m1: 48|1@1+ (1,0) [0|0] "" X
 SG_ RCM_a105_imuLongAccOffstCompLim m1: 49|1@1+ (1,0) [0|0] "" X
 SG_ RCM_a106_imuLatAccOffstCompLim m1: 50|1@1+ (1,0) [0|0] "" X
 SG_ RCM_a107_imuVertAccOffstCompLim m1: 51|1@1+ (1,0) [0|0] "" X
 SG_ RCM_a108_crashAlgoWakeup m1: 52|1@1+ (1,0) [0|0] "" X
 SG_ RCM_a109_abuseImmunity m1: 53|1@1+ (1,0) [0|0] "" X
 SG_ RCM_a110_factoryMode m1: 54|1@1+ (1,0) [0|0] "" X
 SG_ RCM_a111_diagnosticsEnabled m1: 55|1@1+ (1,0) [0|0] "" X
 SG_ RCM_a112_imuYawRate m1: 56|1@1+ (1,0) [0|0] "" X
 SG_ RCM_a113_imuPitchRate m1: 57|1@1+ (1,0) [0|0] "" X
 SG_ RCM_a114_imuRollRate m1: 58|1@1+ (1,0) [0|0] "" X
 SG_ RCM_a115_imuLinearAcceleration m1: 59|1@1+ (1,0) [0|0] "" X
 SG_ RCM_a116_imuLateralAcceleration m1: 60|1@1+ (1,0) [0|0] "" X
 SG_ RCM_a117_imuVerticalAcceleration m1: 61|1@1+ (1,0) [0|0] "" X
 SG_ RCM_a118_imuInPlaneAcceleration m1: 62|1@1+ (1,0) [0|0] "" X

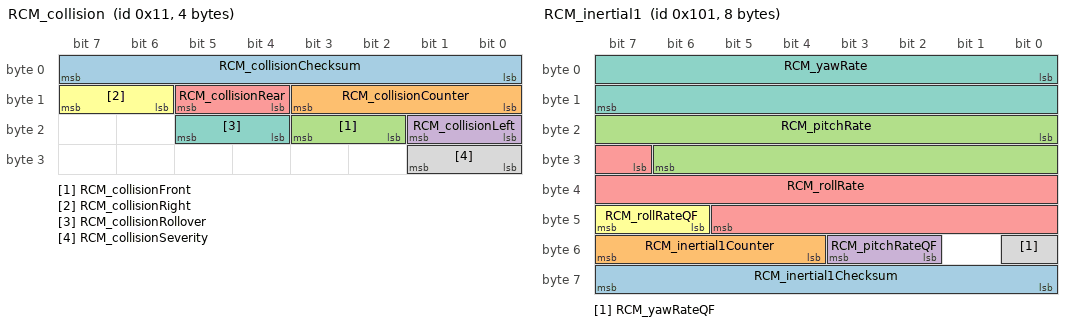
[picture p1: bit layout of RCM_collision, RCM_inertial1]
BO_ 17 RCM_collision: 4 VEH
 SG_ RCM_collisionChecksum: 0|8@1+ (1,0) [0|0] "" X
 SG_ RCM_collisionCounter: 8|4@1+ (1,0) [0|0] "" X
 SG_ RCM_collisionFront: 18|2@1+ (1,0) [0|0] "" X
 SG_ RCM_collisionLeft: 16|2@1+ (1,0) [0|0] "" X
 SG_ RCM_collisionRear: 12|2@1+ (1,0) [0|0] "" X
 SG_ RCM_collisionRight: 14|2@1+ (1,0) [0|0] "" X
 SG_ RCM_collisionRollover: 20|2@1+ (1,0) [0|0] "" X
 SG_ RCM_collisionSeverity: 24|2@1+ (1,0) [0|0] "" X

BO_ 257 RCM_inertial1: 8 CH
 SG_ RCM_inertial1Checksum: 56|8@1+ (1,0) [0|0] "" X
 SG_ RCM_inertial1Counter: 52|4@1+ (1,0) [0|0] "" X
 SG_ RCM_pitchRate: 16|15@1- (0.00025,0) [0|0] "rad/s" X
 SG_ RCM_pitchRateQF: 50|2@1+ (1,0) [0|0] "" X
 SG_ RCM_rollRate: 31|15@1- (0.00025,0) [0|0] "rad/s" X
 SG_ RCM_rollRateQF: 46|2@1+ (1,0) [0|0] "" X
 SG_ RCM_yawRate: 0|16@1- (0.0001,0) [0|0] "rad/s" X
 SG_ RCM_yawRateQF: 48|1@1+ (1,0) [0|0] "" X

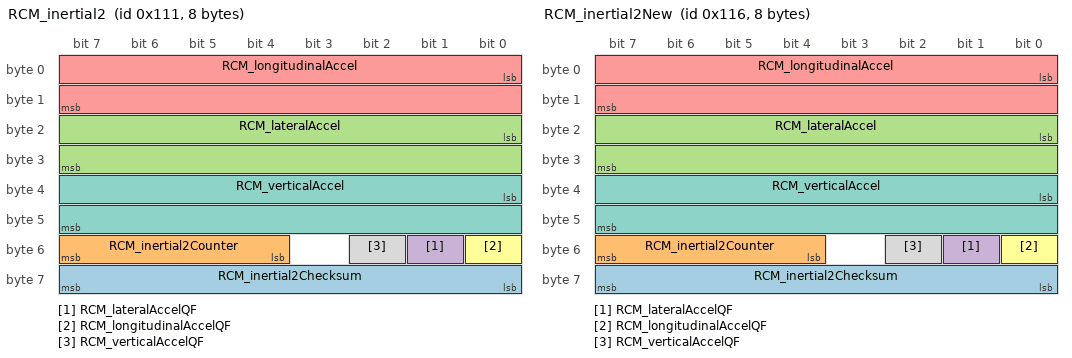
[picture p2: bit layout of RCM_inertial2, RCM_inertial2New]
BO_ 273 RCM_inertial2: 8 CH
 SG_ RCM_inertial2Checksum : 56|8@1+ (1,0) [0|255] "" X
 SG_ RCM_inertial2Counter : 52|4@1+ (1,0) [0|15] "" X
 SG_ RCM_lateralAccel : 16|16@1- (0.00125,0) [-40.9575|40.9575] "m/s^2" X
 SG_ RCM_lateralAccelQF : 49|1@1+ (1,0) [0|1] ""  X
 SG_ RCM_longitudinalAccel : 0|16@1- (0.00125,0) [-40.9575|40.9575] "m/s^2" X
 SG_ RCM_longitudinalAccelQF : 48|1@1+ (1,0) [0|1] "" X
 SG_ RCM_verticalAccel : 32|16@1- (0.00125,0) [-40.9575|40.9575] "m/s^2" X
 SG_ RCM_verticalAccelQF : 50|1@1+ (1,0) [0|1] ""  X

BO_ 278 RCM_inertial2New: 8 CH
 SG_ RCM_inertial2Checksum : 56|8@1+ (1,0) [0|255] ""  Receiver
 SG_ RCM_inertial2Counter : 52|4@1+ (1,0) [0|15] ""  Receiver
 SG_ RCM_lateralAccel : 16|16@1- (0.00125,0) [-40.9575|40.9575] "m/s^2"  Receiver
 SG_ RCM_lateralAccelQF : 49|1@1+ (1,0) [0|1] ""  Receiver
 SG_ RCM_longitudinalAccel : 0|16@1- (0.00125,0) [-40.9575|40.9575] "m/s^2"  Receiver
 SG_ RCM_longitudinalAccelQF : 48|1@1+ (1,0) [0|1] ""  Receiver
 SG_ RCM_verticalAccel : 32|16@1- (0.00125,0) [-40.9575|40.9575] "m/s^2"  Receiver
 SG_ RCM_verticalAccelQF : 50|1@1+ (1,0) [0|1] ""  Receiver

BO_ 849 RCM_info: 8 CH
 SG_ RCM_infoIndex M: 0|8@1+ (1,0) [0|0] "" X
 SG_ RCM_infoBuildType m10: 8|8@1+ (1,0) [0|0] "" X
 SG_ RCM_infoComponentID m10: 48|16@1+ (1,0) [0|0] "" X
 SG_ RCM_infoPcbaID m11: 16|8@1+ (1,0) [0|0] "" X
 SG_ RCM_infoAssemblyID m11: 24|8@1+ (1,0) [0|0] "" X
 SG_ RCM_infoUsageID m11: 32|16@1+ (1,0) [0|0] "" X
 SG_ RCM_infoBootUdsProtoVersion m20: 8|8@1+ (1,0) [0|0] "" X
 SG_ RCM_infoBootloaderCRC m20: 32|32@1+ (1,0) [0|0] "" X
 SG_ RCM_infoApplicationCRC m13: 32|32@1+ (1,0) [0|0] "" X
 SG_ RCM_infoVariantCRC m22: 32|32@1+ (1,0) [0|0] "" X

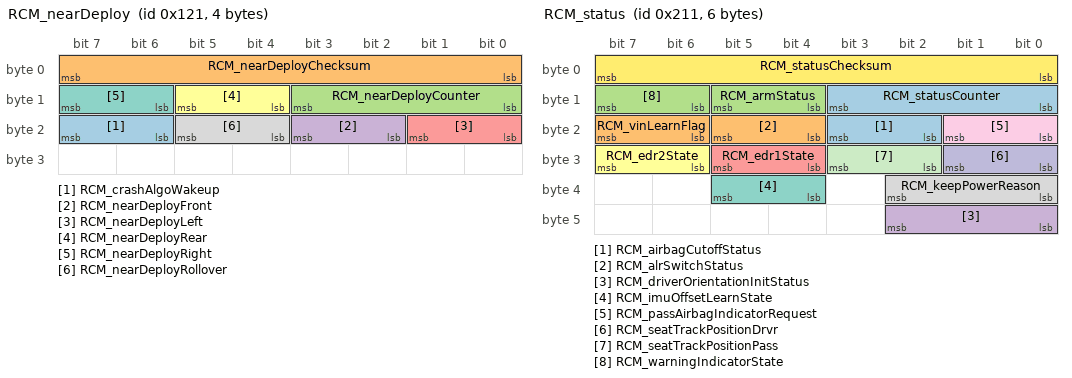
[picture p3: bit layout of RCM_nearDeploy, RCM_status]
BO_ 289 RCM_nearDeploy: 4 VEH
 SG_ RCM_crashAlgoWakeup: 22|2@1+ (1,0) [0|0] "" X
 SG_ RCM_nearDeployChecksum: 0|8@1+ (1,0) [0|0] "" X
 SG_ RCM_nearDeployCounter: 8|4@1+ (1,0) [0|0] "" X
 SG_ RCM_nearDeployFront: 18|2@1+ (1,0) [0|0] "" X
 SG_ RCM_nearDeployLeft: 16|2@1+ (1,0) [0|0] "" X
 SG_ RCM_nearDeployRear: 12|2@1+ (1,0) [0|0] "" X
 SG_ RCM_nearDeployRight: 14|2@1+ (1,0) [0|0] "" X
 SG_ RCM_nearDeployRollover: 20|2@1+ (1,0) [0|0] "" X

BO_ 529 RCM_status: 6 VEH
 SG_ RCM_airbagCutoffStatus: 18|2@1+ (1,0) [0|0] "" X
 SG_ RCM_alrSwitchStatus: 20|2@1+ (1,0) [0|0] "" X
 SG_ RCM_armStatus: 12|2@1+ (1,0) [0|0] "" X
 SG_ RCM_driverOrientationInitStatus: 40|3@1+ (1,0) [0|0] "" X
 SG_ RCM_edr1State: 28|2@1+ (1,0) [0|0] "" X
 SG_ RCM_edr2State: 30|2@1+ (1,0) [0|0] "" X
 SG_ RCM_imuOffsetLearnState: 36|2@1+ (1,0) [0|0] "" X
 SG_ RCM_keepPowerReason: 32|3@1+ (1,0) [0|0] "" X
 SG_ RCM_passAirbagIndicatorRequest: 16|2@1+ (1,0) [0|0] "" X
 SG_ RCM_seatTrackPositionDrvr: 24|2@1+ (1,0) [0|0] "" X
 SG_ RCM_seatTrackPositionPass: 26|2@1+ (1,0) [0|0] "" X
 SG_ RCM_statusChecksum: 0|8@1+ (1,0) [0|0] "" X
 SG_ RCM_statusCounter: 8|4@1+ (1,0) [0|0] "" X
 SG_ RCM_vinLearnFlag: 22|2@1+ (1,0) [0|0] "" X
 SG_ RCM_warningIndicatorState: 14|2@1+ (1,0) [0|0] "" X

BO_ 1359 SCCM_alertMatrix: 8 VEH
 SG_ SCCM_matrixIndex M: 0|4@1+ (1,0) [0|0] "" X
 SG_ SCCM_a001_CANBusOff m0: 4|1@1+ (1,0) [0|0] "" X
 SG_ SCCM_a002_CANTOut m0: 5|1@1+ (1,0) [0|0] "" X
 SG_ SCCM_a003_highBeamOpen m0: 6|1@1+ (1,0) [0|0] "" X
 SG_ SCCM_a004_highBeamShortToGND m0: 7|1@1+ (1,0) [0|0] "" X
 SG_ SCCM_a005_tipWipeOpen m0: 8|1@1+ (1,0) [0|0] "" X
 SG_ SCCM_a006_tipWipeShortToGND m0: 9|1@1+ (1,0) [0|0] "" X
 SG_ SCCM_a007_turnIndComInfo m0: 10|1@1+ (1,0) [0|0] "" X
 SG_ SCCM_a008_turnIndInvalidTrans m0: 11|1@1+ (1,0) [0|0] "" X
 SG_ SCCM_a009_turnIndOpen m0: 12|1@1+ (1,0) [0|0] "" X
 SG_ SCCM_a010_turnIndShortToGnd m0: 13|1@1+ (1,0) [0|0] "" X
 SG_ SCCM_a011_turnIndHWErr m0: 14|1@1+ (1,0) [0|0] "" X
 SG_ SCCM_a012_turnGenErr m0: 15|1@1+ (1,0) [0|0] "" X
 SG_ SCCM_a013_voltageHigh m0: 16|1@1+ (1,0) [0|0] "" X
 SG_ SCCM_a014_voltageLow m0: 17|1@1+ (1,0) [0|0] "" X
 SG_ SCCM_a015_softwareError m0: 18|1@1+ (1,0) [0|0] "" X
 SG_ SCCM_a016_hardwareError m0: 19|1@1+ (1,0) [0|0] "" X
 SG_ SCCM_a017_memoryError m0: 20|1@1+ (1,0) [0|0] "" X
 SG_ SCCM_a018_angleSpeedOutOfRange m0: 21|1@1+ (1,0) [0|0] "" X
 SG_ SCCM_a019_angleSpeedAboveLimit m0: 22|1@1+ (1,0) [0|0] "" X
 SG_ SCCM_a020_angleInternalError m0: 23|1@1+ (1,0) [0|0] "" X
 SG_ SCCM_a021_gearStalkSignalInvalid m0: 24|1@1+ (1,0) [0|0] "" X
 SG_ SCCM_a022_gearStalkOpenCircuit m0: 25|1@1+ (1,0) [0|0] "" X
 SG_ SCCM_a023_gearStalkShortCircuit m0: 26|1@1+ (1,0) [0|0] "" X
 SG_ SCCM_a024_gearStalkGenErr m0: 27|1@1+ (1,0) [0|0] "" X
 SG_ SCCM_a025_runTimeError m0: 28|1@1+ (1,0) [0|0] "" X
 SG_ SCCM_a026_parkButtonInvalidSignal m0: 29|1@1+ (1,0) [0|0] "" X
 SG_ SCCM_a027_parkButtonOpenCircuit m0: 30|1@1+ (1,0) [0|0] "" X
 SG_ SCCM_a028_parkButtonShortToGround m0: 31|1@1+ (1,0) [0|0] "" X
 SG_ SCCM_a029_parkButtonMalfunction m0: 32|1@1+ (1,0) [0|0] "" X

BO_ 816 SCCM_info: 8 VEH
 SG_ SCCM_infoIndex M: 0|8@1+ (1,0) [0|0] "" X
 SG_ SCCM_infoBuildType m10: 8|8@1+ (1,0) [0|0] "" X
 SG_ SCCM_infoBuildConfigId m10: 16|16@1+ (1,0) [0|0] "" X
 SG_ SCCM_infoHardwareId m10: 32|16@1+ (1,0) [0|0] "" X
 SG_ SCCM_infoComponentId m10: 48|16@1+ (1,0) [0|0] "" X
 SG_ SCCM_infoPcbaId m11: 16|8@1+ (1,0) [0|0] "" X
 SG_ SCCM_infoAssemblyId m11: 24|8@1+ (1,0) [0|0] "" X
 SG_ SCCM_infoUsageId m11: 32|16@1+ (1,0) [0|0] "" X
 SG_ SCCM_infoSubUsageId m11: 48|16@1+ (1,0) [0|0] "" X
 SG_ SCCM_infoPlatformType m13: 8|8@1+ (1,0) [0|0] "" X
 SG_ SCCM_infoAppCrc m13: 32|32@0+ (1,0) [0|0] "" X
 SG_ SCCM_infoBootSvnRev m14: 8|24@1+ (1,0) [0|0] "" X
 SG_ SCCM_infoBootSvnUrlHash m14: 32|32@1+ (1,0) [0|0] "" X
 SG_ SCCM_infoSubcomponent1Version m16: 16|32@1+ (1,0) [0|0] "" X
 SG_ SCCM_infoAppSvnHash m17: 10|54@1+ (4,0) [0|0] "" X
 SG_ SCCM_infoBootSvnHash m18: 10|54@1+ (4,0) [0|0] "" X
 SG_ SCCM_infoUdsProtoVersion m20: 8|8@1+ (1,0) [0|0] "" X
 SG_ SCCM_infoBootCrc m20: 32|32@1+ (1,0) [0|0] "" X

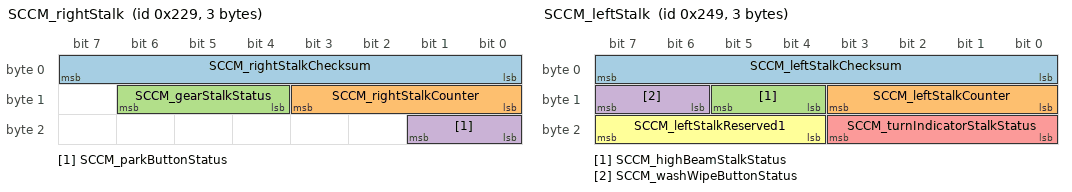
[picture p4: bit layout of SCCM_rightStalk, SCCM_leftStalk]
BO_ 553 SCCM_rightStalk: 3 VEH
 SG_ SCCM_rightStalkChecksum: 0|8@1+ (1,0) [0|0] "" X
 SG_ SCCM_rightStalkCounter: 8|4@1+ (1,0) [0|0] "" X
 SG_ SCCM_gearStalkStatus: 12|3@1+ (1,0) [0|7] "" X
 SG_ SCCM_parkButtonStatus: 16|2@1+ (1,0) [0|3] "" X

BO_ 585 SCCM_leftStalk: 3 VEH
 SG_ SCCM_leftStalkChecksum: 0|8@1+ (1,0) [0|0] "" X
 SG_ SCCM_leftStalkCounter: 8|4@1+ (1,0) [0|0] "" X
 SG_ SCCM_highBeamStalkStatus: 12|2@1+ (1,0) [0|0] "" X
 SG_ SCCM_washWipeButtonStatus: 14|2@1+ (1,0) [0|0] "" X
 SG_ SCCM_turnIndicatorStalkStatus: 16|4@1+ (1,0) [0|0] "" X
 SG_ SCCM_leftStalkReserved1: 20|4@1+ (1,0) [0|0] "" X

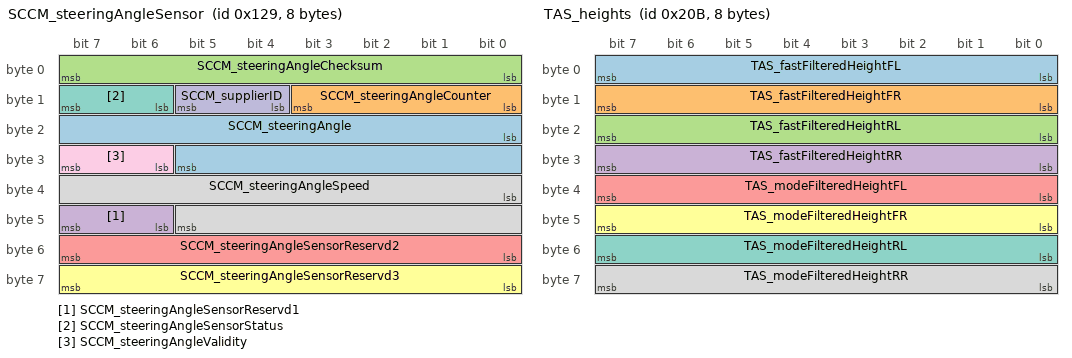
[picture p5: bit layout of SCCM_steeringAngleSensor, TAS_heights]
BO_ 297 SCCM_steeringAngleSensor: 8 VEH
 SG_ SCCM_steeringAngle: 16|14@1+ (0.1,-819.2) [0|0] "deg" X
 SG_ SCCM_steeringAngleCounter: 8|4@1+ (1,0) [0|0] "" X
 SG_ SCCM_steeringAngleChecksum: 0|8@1+ (1,0) [0|0] "" X
 SG_ SCCM_steeringAngleSensorReservd1: 46|2@1+ (1,0) [0|0] "" X
 SG_ SCCM_steeringAngleSensorReservd2: 48|8@1+ (1,0) [0|0] "" X
 SG_ SCCM_steeringAngleSensorReservd3: 56|8@1+ (1,0) [0|0] "" X
 SG_ SCCM_steeringAngleSensorStatus: 14|2@1+ (1,0) [0|0] "" X
 SG_ SCCM_steeringAngleSpeed: 32|14@1+ (0.5,-4096) [0|0] "deg/s" X
 SG_ SCCM_steeringAngleValidity: 30|2@1+ (1,0) [0|0] "" X
 SG_ SCCM_supplierID: 12|2@1+ (1,0) [0|0] "" X

BO_ 815 SCM_alertMatrix1: 8 CH
 SG_ SCM_a001_hwDSPfault: 0|1@1+ (1,0) [0|0] "" X
 SG_ SCM_a002_hwIbatOC: 1|1@1+ (1,0) [0|0] "" X
 SG_ SCM_a003_hwCordOT: 2|1@1+ (1,0) [0|0] "" X
 SG_ SCM_a004_hwVbusOV: 3|1@1+ (1,0) [0|0] "" X
 SG_ SCM_a005_hwHVIL: 4|1@1+ (1,0) [0|0] "" X
 SG_ SCM_a006_hwWeld_V1: 5|1@1+ (1,0) [0|0] "" X
 SG_ SCM_a007_hwWeld_V2: 6|1@1+ (1,0) [0|0] "" X
 SG_ SCM_a008_hwOpen_V1: 7|1@1+ (1,0) [0|0] "" X
 SG_ SCM_a009_hwOpen_V2: 8|1@1+ (1,0) [0|0] "" X
 SG_ SCM_a010_hwIllegalCntrCmdV1: 9|1@1+ (1,0) [0|0] "" X
 SG_ SCM_a011_hwIllegalCntrCmdInt: 10|1@1+ (1,0) [0|0] "" X
 SG_ SCM_a012_hwIllegalCntrCmdV2: 11|1@1+ (1,0) [0|0] "" X
 SG_ SCM_a013_cordTempHiFoldBk: 12|1@1+ (1,0) [0|0] "" X
 SG_ SCM_a014_coolantTempHiFoldBk: 13|1@1+ (1,0) [0|0] "" X
 SG_ SCM_a015_unusedHW15: 14|1@1+ (1,0) [0|0] "" X
 SG_ SCM_a016_unusedHW16: 15|1@1+ (1,0) [0|0] "" X
 SG_ SCM_a017_unusedHW17: 16|1@1+ (1,0) [0|0] "" X
 SG_ SCM_a018_unusedHW18: 17|1@1+ (1,0) [0|0] "" X
 SG_ SCM_a019_unusedHW19: 18|1@1+ (1,0) [0|0] "" X
 SG_ SCM_a020_unusedHW20: 19|1@1+ (1,0) [0|0] "" X
 SG_ SCM_a021_unusedHW21: 20|1@1+ (1,0) [0|0] "" X
 SG_ SCM_a022_fastChargeLimitActiveV1: 21|1@1+ (1,0) [0|0] "" X
 SG_ SCM_a023_fastChargeLimitActiveV2: 22|1@1+ (1,0) [0|0] "" X
 SG_ SCM_a024_emergencyShutdown: 23|1@1+ (1,0) [0|0] "" X
 SG_ SCM_a025_internalIsolationFault: 24|1@1+ (1,0) [0|0] "" X
 SG_ SCM_a026_internalIsolationLow: 25|1@1+ (1,0) [0|0] "" X
 SG_ SCM_a027_externalIsolationLow: 26|1@1+ (1,0) [0|0] "" X
 SG_ SCM_a028_isolationRationality: 27|1@1+ (1,0) [0|0] "" X
 SG_ SCM_a029_VbatOV: 28|1@1+ (1,0) [0|0] "" X
 SG_ SCM_a030_VbusOV: 29|1@1+ (1,0) [0|0] "" X
 SG_ SCM_a031_IbatOC: 30|1@1+ (1,0) [0|0] "" X
 SG_ SCM_a032_VBatRationality: 31|1@1+ (1,0) [0|0] "" X
 SG_ SCM_a033_VBusRationality: 32|1@1+ (1,0) [0|0] "" X
 SG_ SCM_a034_IBatRationality: 33|1@1+ (1,0) [0|0] "" X
 SG_ SCM_a035_unexpectedVbusBehavior: 34|1@1+ (1,0) [0|0] "" X
 SG_ SCM_a036_internalContactorWelded: 35|1@1+ (1,0) [0|0] "" X
 SG_ SCM_a037_outputContactorWelded: 36|1@1+ (1,0) [0|0] "" X
 SG_ SCM_a038_contactorFailedOpen: 37|1@1+ (1,0) [0|0] "" X
 SG_ SCM_a039_ibatRegulation: 38|1@1+ (1,0) [0|0] "" X
 SG_ SCM_a040_plus12VOutOfRange: 39|1@1+ (1,0) [0|0] "" X
 SG_ SCM_a041_minus12VOutOfRange: 40|1@1+ (1,0) [0|0] "" X
 SG_ SCM_a042_pilotOutOfRange: 41|1@1+ (1,0) [0|0] "" X
 SG_ SCM_a043_pilotRationality: 42|1@1+ (1,0) [0|0] "" X
 SG_ SCM_a044_proximityRationality: 43|1@1+ (1,0) [0|0] "" X
 SG_ SCM_a045_pcbaOT: 44|1@1+ (1,0) [0|0] "" X
 SG_ SCM_a046_coolantOT: 45|1@1+ (1,0) [0|0] "" X
 SG_ SCM_a047_cordOT: 46|1@1+ (1,0) [0|0] "" X
 SG_ SCM_a048_ambientOT: 47|1@1+ (1,0) [0|0] "" X
 SG_ SCM_a049_pcbaTempRationality: 48|1@1+ (1,0) [0|0] "" X
 SG_ SCM_a050_coolantTempRationality: 49|1@1+ (1,0) [0|0] "" X
 SG_ SCM_a051_cordTempRationality: 50|1@1+ (1,0) [0|0] "" X
 SG_ SCM_a052_ambientTempRationality: 51|1@1+ (1,0) [0|0] "" X
 SG_ SCM_a053_unexpectedThermalBehavi: 52|1@1+ (1,0) [0|0] "" X
 SG_ SCM_a054_pumpRegulation: 53|1@1+ (1,0) [0|0] "" X
 SG_ SCM_a055_coolantLevelLow: 54|1@1+ (1,0) [0|0] "" X
 SG_ SCM_a056_stateTransitionDenied: 55|1@1+ (1,0) [0|0] "" X
 SG_ SCM_a057_watchdogReset: 56|1@1+ (1,0) [0|0] "" X
 SG_ SCM_a058_adcRef: 57|1@1+ (1,0) [0|0] "" X
 SG_ SCM_a059_memoryError: 58|1@1+ (1,0) [0|0] "" X
 SG_ SCM_a060_swHVIL: 59|1@1+ (1,0) [0|0] "" X
 SG_ SCM_a061_postOutOfService: 60|1@1+ (1,0) [0|0] "" X
 SG_ SCM_a062_unused: 61|1@1+ (1,0) [0|0] "" X
 SG_ SCM_a063_canRationality: 62|1@1+ (1,0) [0|0] "" X
 SG_ SCM_a064_vehicleCommandTimeout: 63|1@1+ (1,0) [0|0] "" X

BO_ 1355 SCM_alertMatrix2: 8 VEH
 SG_ SCM_a065_vBatRationalityStage1: 0|1@1+ (1,0) [0|0] "" X
 SG_ SCM_a066_vBatRationalityStage2: 1|1@1+ (1,0) [0|0] "" X
 SG_ SCM_a067_vBatRationalityStage3: 2|1@1+ (1,0) [0|0] "" X
 SG_ SCM_a068_vBatRationalityStage4: 3|1@1+ (1,0) [0|0] "" X
 SG_ SCM_a069_vStageRationalityV1: 4|1@1+ (1,0) [0|0] "" X
 SG_ SCM_a070_vStageRationalityV2: 5|1@1+ (1,0) [0|0] "" X
 SG_ SCM_a071_chargerMIA: 6|1@1+ (1,0) [0|0] "" X
 SG_ SCM_a072_gtwMIA: 7|1@1+ (1,0) [0|0] "" X
 SG_ SCM_a073_lccMIA: 8|1@1+ (1,0) [0|0] "" X
 SG_ SCM_a074_isoVDiffHi: 9|1@1+ (1,0) [0|0] "" X
 SG_ SCM_a075_leakageTestAbsDecayLow: 10|1@1+ (1,0) [0|0] "" X
 SG_ SCM_a076_bmsMIA: 11|1@1+ (1,0) [0|0] "" X
 SG_ SCM_a077_unexpectedVbatBehavior: 12|1@1+ (1,0) [0|0] "" X
 SG_ SCM_a078_voltageMatchTimeout: 13|1@1+ (1,0) [0|0] "" X
 SG_ SCM_a079_unexpectedVbat: 14|1@1+ (1,0) [0|0] "" X
 SG_ SCM_a080_lccFaulted: 15|1@1+ (1,0) [0|0] "" X
 SG_ SCM_a081_rmsInputVoltageHigh: 16|1@1+ (1,0) [0|0] "" X
 SG_ SCM_a082_VbatUV: 17|1@1+ (1,0) [0|0] "" X
 SG_ SCM_a083_chargeCurrentLimited: 18|1@1+ (1,0) [0|0] "" X
 SG_ SCM_a084_unused84: 19|1@1+ (1,0) [0|0] "" X
 SG_ SCM_a085_unused85: 20|1@1+ (1,0) [0|0] "" X
 SG_ SCM_a086_lccResetDetected: 21|1@1+ (1,0) [0|0] "" X
 SG_ SCM_a087_posCordTempRationality: 22|1@1+ (1,0) [0|0] "" X
 SG_ SCM_a088_negCordTempRationality: 23|1@1+ (1,0) [0|0] "" X
 SG_ SCM_a089_posCordOT: 24|1@1+ (1,0) [0|0] "" X
 SG_ SCM_a090_negCordOT: 25|1@1+ (1,0) [0|0] "" X
 SG_ SCM_a091_voltageRiseDetection: 26|1@1+ (1,0) [0|0] "" X
 SG_ SCM_a092_cabEnableDeasserted: 27|1@1+ (1,0) [0|0] "" X
 SG_ SCM_a093_unused93: 28|1@1+ (1,0) [0|0] "" X
 SG_ SCM_a094_unused94: 29|1@1+ (1,0) [0|0] "" X
 SG_ SCM_a095_unused95: 30|1@1+ (1,0) [0|0] "" X
 SG_ SCM_a096_unused96: 31|1@1+ (1,0) [0|0] "" X
 SG_ SCM_a097_unused97: 32|1@1+ (1,0) [0|0] "" X
 SG_ SCM_a098_unused98: 33|1@1+ (1,0) [0|0] "" X
 SG_ SCM_a099_unused99: 34|1@1+ (1,0) [0|0] "" X
 SG_ SCM_a100_unused100: 35|1@1+ (1,0) [0|0] "" X
 SG_ SCM_a101_unused101: 36|1@1+ (1,0) [0|0] "" X
 SG_ SCM_a102_unused102: 37|1@1+ (1,0) [0|0] "" X
 SG_ SCM_a103_unused103: 38|1@1+ (1,0) [0|0] "" X
 SG_ SCM_a104_unused104: 39|1@1+ (1,0) [0|0] "" X
 SG_ SCM_a105_unused105: 40|1@1+ (1,0) [0|0] "" X
 SG_ SCM_a106_unused106: 41|1@1+ (1,0) [0|0] "" X
 SG_ SCM_a107_unused107: 42|1@1+ (1,0) [0|0] "" X
 SG_ SCM_a108_unused108: 43|1@1+ (1,0) [0|0] "" X
 SG_ SCM_a109_unused109: 44|1@1+ (1,0) [0|0] "" X
 SG_ SCM_a110_unused110: 45|1@1+ (1,0) [0|0] "" X
 SG_ SCM_a111_unused111: 46|1@1+ (1,0) [0|0] "" X
 SG_ SCM_a112_unused112: 47|1@1+ (1,0) [0|0] "" X
 SG_ SCM_a113_unused113: 48|1@1+ (1,0) [0|0] "" X
 SG_ SCM_a114_unused114: 49|1@1+ (1,0) [0|0] "" X
 SG_ SCM_a115_unused115: 50|1@1+ (1,0) [0|0] "" X
 SG_ SCM_a116_unused116: 51|1@1+ (1,0) [0|0] "" X
 SG_ SCM_a117_unused117: 52|1@1+ (1,0) [0|0] "" X
 SG_ SCM_a118_unused118: 53|1@1+ (1,0) [0|0] "" X
 SG_ SCM_a119_unused119: 54|1@1+ (1,0) [0|0] "" X
 SG_ SCM_a120_unused120: 55|1@1+ (1,0) [0|0] "" X
 SG_ SCM_a121_unused121: 56|1@1+ (1,0) [0|0] "" X
 SG_ SCM_a122_unused122: 57|1@1+ (1,0) [0|0] "" X
 SG_ SCM_a123_unused123: 58|1@1+ (1,0) [0|0] "" X
 SG_ SCM_a124_unused124: 59|1@1+ (1,0) [0|0] "" X
 SG_ SCM_a125_unused125: 60|1@1+ (1,0) [0|0] "" X
 SG_ SCM_a126_unused126: 61|1@1+ (1,0) [0|0] "" X
 SG_ SCM_a127_unused127: 62|1@1+ (1,0) [0|0] "" X
 SG_ SCM_a128_unused128: 63|1@1+ (1,0) [0|0] "" X

BO_ 869 SCS_alertMatrix1: 8 VEH
 SG_ SCS_a001_hwDSPfault: 0|1@1+ (1,0) [0|0] "" X
 SG_ SCS_a002_hwIbatOC: 1|1@1+ (1,0) [0|0] "" X
 SG_ SCS_a003_hwCordOT: 2|1@1+ (1,0) [0|0] "" X
 SG_ SCS_a004_hwVbusOV: 3|1@1+ (1,0) [0|0] "" X
 SG_ SCS_a005_hwHVIL: 4|1@1+ (1,0) [0|0] "" X
 SG_ SCS_a006_hwWeld_V1: 5|1@1+ (1,0) [0|0] "" X
 SG_ SCS_a007_hwWeld_V2: 6|1@1+ (1,0) [0|0] "" X
 SG_ SCS_a008_hwOpen_V1: 7|1@1+ (1,0) [0|0] "" X
 SG_ SCS_a009_hwOpen_V2: 8|1@1+ (1,0) [0|0] "" X
 SG_ SCS_a010_hwIllegalCntrCmdV1: 9|1@1+ (1,0) [0|0] "" X
 SG_ SCS_a011_hwIllegalCntrCmdInt: 10|1@1+ (1,0) [0|0] "" X
 SG_ SCS_a012_hwIllegalCntrCmdV2: 11|1@1+ (1,0) [0|0] "" X
 SG_ SCS_a013_cordTempHiFoldBk: 12|1@1+ (1,0) [0|0] "" X
 SG_ SCS_a014_coolantTempHiFoldBk: 13|1@1+ (1,0) [0|0] "" X
 SG_ SCS_a015_unusedHW15: 14|1@1+ (1,0) [0|0] "" X
 SG_ SCS_a016_unusedHW16: 15|1@1+ (1,0) [0|0] "" X
 SG_ SCS_a017_unusedHW17: 16|1@1+ (1,0) [0|0] "" X
 SG_ SCS_a018_unusedHW18: 17|1@1+ (1,0) [0|0] "" X
 SG_ SCS_a019_unusedHW19: 18|1@1+ (1,0) [0|0] "" X
 SG_ SCS_a020_unusedHW20: 19|1@1+ (1,0) [0|0] "" X
 SG_ SCS_a021_unusedHW21: 20|1@1+ (1,0) [0|0] "" X
 SG_ SCS_a022_fastChargeLimitActiveV1: 21|1@1+ (1,0) [0|0] "" X
 SG_ SCS_a023_fastChargeLimitActiveV2: 22|1@1+ (1,0) [0|0] "" X
 SG_ SCS_a024_emergencyShutdown: 23|1@1+ (1,0) [0|0] "" X
 SG_ SCS_a025_internalIsolationFault: 24|1@1+ (1,0) [0|0] "" X
 SG_ SCS_a026_internalIsolationLow: 25|1@1+ (1,0) [0|0] "" X
 SG_ SCS_a027_externalIsolationLow: 26|1@1+ (1,0) [0|0] "" X
 SG_ SCS_a028_isolationRationality: 27|1@1+ (1,0) [0|0] "" X
 SG_ SCS_a029_VbatOV: 28|1@1+ (1,0) [0|0] "" X
 SG_ SCS_a030_VbusOV: 29|1@1+ (1,0) [0|0] "" X
 SG_ SCS_a031_IbatOC: 30|1@1+ (1,0) [0|0] "" X
 SG_ SCS_a032_VBatRationality: 31|1@1+ (1,0) [0|0] "" X
 SG_ SCS_a033_VBusRationality: 32|1@1+ (1,0) [0|0] "" X
 SG_ SCS_a034_IBatRationality: 33|1@1+ (1,0) [0|0] "" X
 SG_ SCS_a035_unexpectedVbusBehavior: 34|1@1+ (1,0) [0|0] "" X
 SG_ SCS_a036_internalContactorWelded: 35|1@1+ (1,0) [0|0] "" X
 SG_ SCS_a037_outputContactorWelded: 36|1@1+ (1,0) [0|0] "" X
 SG_ SCS_a038_contactorFailedOpen: 37|1@1+ (1,0) [0|0] "" X
 SG_ SCS_a039_ibatRegulation: 38|1@1+ (1,0) [0|0] "" X
 SG_ SCS_a040_plus12VOutOfRange: 39|1@1+ (1,0) [0|0] "" X
 SG_ SCS_a041_minus12VOutOfRange: 40|1@1+ (1,0) [0|0] "" X
 SG_ SCS_a042_pilotOutOfRange: 41|1@1+ (1,0) [0|0] "" X
 SG_ SCS_a043_pilotRationality: 42|1@1+ (1,0) [0|0] "" X
 SG_ SCS_a044_proximityRationality: 43|1@1+ (1,0) [0|0] "" X
 SG_ SCS_a045_pcbaOT: 44|1@1+ (1,0) [0|0] "" X
 SG_ SCS_a046_coolantOT: 45|1@1+ (1,0) [0|0] "" X
 SG_ SCS_a047_cordOT: 46|1@1+ (1,0) [0|0] "" X
 SG_ SCS_a048_ambientOT: 47|1@1+ (1,0) [0|0] "" X
 SG_ SCS_a049_pcbaTempRationality: 48|1@1+ (1,0) [0|0] "" X
 SG_ SCS_a050_coolantTempRationality: 49|1@1+ (1,0) [0|0] "" X
 SG_ SCS_a051_cordTempRationality: 50|1@1+ (1,0) [0|0] "" X
 SG_ SCS_a052_ambientTempRationality: 51|1@1+ (1,0) [0|0] "" X
 SG_ SCS_a053_unexpectedThermalBehavi: 52|1@1+ (1,0) [0|0] "" X
 SG_ SCS_a054_pumpRegulation: 53|1@1+ (1,0) [0|0] "" X
 SG_ SCS_a055_coolantLevelLow: 54|1@1+ (1,0) [0|0] "" X
 SG_ SCS_a056_stateTransitionDenied: 55|1@1+ (1,0) [0|0] "" X
 SG_ SCS_a057_watchdogReset: 56|1@1+ (1,0) [0|0] "" X
 SG_ SCS_a058_adcRef: 57|1@1+ (1,0) [0|0] "" X
 SG_ SCS_a059_memoryError: 58|1@1+ (1,0) [0|0] "" X
 SG_ SCS_a060_swHVIL: 59|1@1+ (1,0) [0|0] "" X
 SG_ SCS_a061_postOutOfService: 60|1@1+ (1,0) [0|0] "" X
 SG_ SCS_a062_unused: 61|1@1+ (1,0) [0|0] "" X
 SG_ SCS_a063_canRationality: 62|1@1+ (1,0) [0|0] "" X
 SG_ SCS_a064_vehicleCommandTimeout: 63|1@1+ (1,0) [0|0] "" X

BO_ 880 SCS_alertMatrix2: 8 CH
 SG_ SCS_a065_vBatRationalityStage1: 0|1@1+ (1,0) [0|0] "" X
 SG_ SCS_a066_vBatRationalityStage2: 1|1@1+ (1,0) [0|0] "" X
 SG_ SCS_a067_vBatRationalityStage3: 2|1@1+ (1,0) [0|0] "" X
 SG_ SCS_a068_vBatRationalityStage4: 3|1@1+ (1,0) [0|0] "" X
 SG_ SCS_a069_vStageRationalityV1: 4|1@1+ (1,0) [0|0] "" X
 SG_ SCS_a070_vStageRationalityV2: 5|1@1+ (1,0) [0|0] "" X
 SG_ SCS_a071_chargerMIA: 6|1@1+ (1,0) [0|0] "" X
 SG_ SCS_a072_gtwMIA: 7|1@1+ (1,0) [0|0] "" X
 SG_ SCS_a073_lccMIA: 8|1@1+ (1,0) [0|0] "" X
 SG_ SCS_a074_isoVDiffHi: 9|1@1+ (1,0) [0|0] "" X
 SG_ SCS_a075_leakageTestAbsDecayLow: 10|1@1+ (1,0) [0|0] "" X
 SG_ SCS_a076_bmsMIA: 11|1@1+ (1,0) [0|0] "" X
 SG_ SCS_a077_unexpectedVbatBehavior: 12|1@1+ (1,0) [0|0] "" X
 SG_ SCS_a078_voltageMatchTimeout: 13|1@1+ (1,0) [0|0] "" X
 SG_ SCS_a079_unexpectedVbat: 14|1@1+ (1,0) [0|0] "" X
 SG_ SCS_a080_lccFaulted: 15|1@1+ (1,0) [0|0] "" X
 SG_ SCS_a081_rmsInputVoltageHigh: 16|1@1+ (1,0) [0|0] "" X
 SG_ SCS_a082_VbatUV: 17|1@1+ (1,0) [0|0] "" X
 SG_ SCS_a083_chargeCurrentLimited: 18|1@1+ (1,0) [0|0] "" X
 SG_ SCS_a084_unused84: 19|1@1+ (1,0) [0|0] "" X
 SG_ SCS_a085_unused85: 20|1@1+ (1,0) [0|0] "" X
 SG_ SCS_a086_lccResetDetected: 21|1@1+ (1,0) [0|0] "" X
 SG_ SCS_a087_posCordTempRationality: 22|1@1+ (1,0) [0|0] "" X
 SG_ SCS_a088_negCordTempRationality: 23|1@1+ (1,0) [0|0] "" X
 SG_ SCS_a089_posCordOT: 24|1@1+ (1,0) [0|0] "" X
 SG_ SCS_a090_negCordOT: 25|1@1+ (1,0) [0|0] "" X
 SG_ SCS_a091_voltageRiseDetection: 26|1@1+ (1,0) [0|0] "" X
 SG_ SCS_a092_cabEnableDeasserted: 27|1@1+ (1,0) [0|0] "" X
 SG_ SCS_a093_unused93: 28|1@1+ (1,0) [0|0] "" X
 SG_ SCS_a094_unused94: 29|1@1+ (1,0) [0|0] "" X
 SG_ SCS_a095_unused95: 30|1@1+ (1,0) [0|0] "" X
 SG_ SCS_a096_unused96: 31|1@1+ (1,0) [0|0] "" X
 SG_ SCS_a097_unused97: 32|1@1+ (1,0) [0|0] "" X
 SG_ SCS_a098_unused98: 33|1@1+ (1,0) [0|0] "" X
 SG_ SCS_a099_unused99: 34|1@1+ (1,0) [0|0] "" X
 SG_ SCS_a100_unused100: 35|1@1+ (1,0) [0|0] "" X
 SG_ SCS_a101_unused101: 36|1@1+ (1,0) [0|0] "" X
 SG_ SCS_a102_unused102: 37|1@1+ (1,0) [0|0] "" X
 SG_ SCS_a103_unused103: 38|1@1+ (1,0) [0|0] "" X
 SG_ SCS_a104_unused104: 39|1@1+ (1,0) [0|0] "" X
 SG_ SCS_a105_unused105: 40|1@1+ (1,0) [0|0] "" X
 SG_ SCS_a106_unused106: 41|1@1+ (1,0) [0|0] "" X
 SG_ SCS_a107_unused107: 42|1@1+ (1,0) [0|0] "" X
 SG_ SCS_a108_unused108: 43|1@1+ (1,0) [0|0] "" X
 SG_ SCS_a109_unused109: 44|1@1+ (1,0) [0|0] "" X
 SG_ SCS_a110_unused110: 45|1@1+ (1,0) [0|0] "" X
 SG_ SCS_a111_unused111: 46|1@1+ (1,0) [0|0] "" X
 SG_ SCS_a112_unused112: 47|1@1+ (1,0) [0|0] "" X
 SG_ SCS_a113_unused113: 48|1@1+ (1,0) [0|0] "" X
 SG_ SCS_a114_unused114: 49|1@1+ (1,0) [0|0] "" X
 SG_ SCS_a115_unused115: 50|1@1+ (1,0) [0|0] "" X
 SG_ SCS_a116_unused116: 51|1@1+ (1,0) [0|0] "" X
 SG_ SCS_a117_unused117: 52|1@1+ (1,0) [0|0] "" X
 SG_ SCS_a118_unused118: 53|1@1+ (1,0) [0|0] "" X
 SG_ SCS_a119_unused119: 54|1@1+ (1,0) [0|0] "" X
 SG_ SCS_a120_unused120: 55|1@1+ (1,0) [0|0] "" X
 SG_ SCS_a121_unused121: 56|1@1+ (1,0) [0|0] "" X
 SG_ SCS_a122_unused122: 57|1@1+ (1,0) [0|0] "" X
 SG_ SCS_a123_unused123: 58|1@1+ (1,0) [0|0] "" X
 SG_ SCS_a124_unused124: 59|1@1+ (1,0) [0|0] "" X
 SG_ SCS_a125_unused125: 60|1@1+ (1,0) [0|0] "" X
 SG_ SCS_a126_unused126: 61|1@1+ (1,0) [0|0] "" X
 SG_ SCS_a127_unused127: 62|1@1+ (1,0) [0|0] "" X
 SG_ SCS_a128_unused128: 63|1@1+ (1,0) [0|0] "" X

BO_ 523 TAS_heights: 8 VEH
 SG_ TAS_fastFilteredHeightFL: 0|8@1+ (1,-128) [0|0] "mm" X
 SG_ TAS_fastFilteredHeightFR: 8|8@1+ (1,-128) [0|0] "mm" X
 SG_ TAS_fastFilteredHeightRL: 16|8@1+ (1,-128) [0|0] "mm" X
 SG_ TAS_fastFilteredHeightRR: 24|8@1+ (1,-128) [0|0] "mm" X
 SG_ TAS_modeFilteredHeightFL: 32|8@1+ (1,-128) [0|0] "mm" X
 SG_ TAS_modeFilteredHeightFR: 40|8@1+ (1,-128) [0|0] "mm" X
 SG_ TAS_modeFilteredHeightRL: 48|8@1+ (1,-128) [0|0] "mm" X
 SG_ TAS_modeFilteredHeightRR: 56|8@1+ (1,-128) [0|0] "mm" X

BO_ 1357 TAS_info: 8 VEH
 SG_ TAS_infoIndex M: 0|8@1+ (1,0) [0|0] "" X
 SG_ TAS_infoBuildType m10: 8|3@1+ (1,0) [0|0] "" X
 SG_ TAS_infoBuildConfigId m10: 16|16@1+ (1,0) [0|0] "" X
 SG_ TAS_infoHardwareId m10: 32|1@1+ (1,0) [0|0] "" X
 SG_ TAS_infoComponentId m10: 48|16@1+ (1,0) [0|0] "" X
 SG_ TAS_infoPcbaId m11: 16|8@1+ (1,0) [0|0] "" X
 SG_ TAS_infoAssemblyId m11: 24|8@1+ (1,0) [0|0] "" X
 SG_ TAS_infoUsageId m11: 32|16@1+ (1,0) [0|0] "" X
 SG_ TAS_infoSubUsageId m11: 48|16@1+ (1,0) [0|0] "" X
 SG_ TAS_infoAppCrc m13: 32|32@1+ (1,0) [0|0] "" X
 SG_ TAS_infoBootloaderSvnRevision m14: 8|24@1+ (1,0) [0|0] "" X
 SG_ TAS_infoAppGitHash m17: 10|54@1+ (4,0) [0|0] "" X
 SG_ TAS_infoBootGitHash m18: 10|54@1+ (4,0) [0|0] "" X
 SG_ TAS_infoPlatformType m19: 8|8@1+ (1,0) [0|0] "" X
 SG_ TAS_infoMajorVersion m19: 16|8@1+ (1,0) [0|0] "" X
 SG_ TAS_infoBranchOrigin m19: 24|8@1+ (1,0) [0|0] "" X
 SG_ TAS_infoMaturity m19: 32|8@1+ (1,0) [0|0] "" X
 SG_ TAS_infoHardwareRevision m19: 40|8@1+ (1,0) [0|0] "" X
 SG_ TAS_infoBootUdsProtoVersion m20: 8|8@1+ (1,0) [0|0] "" X
 SG_ TAS_infoBootCrc m20: 32|32@1+ (1,0) [0|0] "" X

BO_ 525 TAS_states: 8 VEH
 SG_ TAS_compressorRun: 30|1@1+ (1,0) [0|0] "" X
 SG_ TAS_currentLevel: 42|3@1+ (1,0) [0|0] "" X
 SG_ TAS_filterMode: 27|3@1+ (1,0) [0|0] "" X
 SG_ TAS_highAllowed: 36|1@1+ (1,0) [0|0] "" X
 SG_ TAS_jackMode: 38|1@1+ (1,0) [0|0] "" X
 SG_ TAS_leanDetected: 32|1@1+ (1,0) [0|0] "" X
 SG_ TAS_levelingState: 0|4@1+ (1,0) [0|0] "" X
 SG_ TAS_levelingType: 4|4@1+ (1,0) [0|0] "" X
 SG_ TAS_limpHomeMode: 48|3@1+ (1,0) [0|0] "" X
 SG_ TAS_lowAllowed: 34|1@1+ (1,0) [0|0] "" X
 SG_ TAS_pressureGallery: 8|8@1+ (0.1,0) [0|0] "bar" X
 SG_ TAS_pressureReservoir: 16|8@1+ (0.1,0) [0|0] "bar" X
 SG_ TAS_redWarningLamp: 40|1@1+ (1,0) [0|0] "" X
 SG_ TAS_runMode: 24|3@1+ (1,0) [0|0] "" X
 SG_ TAS_spinnerUI: 41|1@1+ (1,0) [0|0] "" X
 SG_ TAS_standardAllowed: 35|1@1+ (1,0) [0|0] "" X
 SG_ TAS_statesChecksum: 56|8@1+ (1,0) [0|0] "" X
 SG_ TAS_statesCounter: 52|4@1+ (1,0) [0|0] "" X
 SG_ TAS_targetLevel: 45|3@1+ (1,0) [0|0] "" X
 SG_ TAS_twistDetected: 31|1@1+ (1,0) [0|0] "" X
 SG_ TAS_veryHighAllowed: 37|1@1+ (1,0) [0|0] "" X
 SG_ TAS_veryLowAllowed: 33|1@1+ (1,0) [0|0] "" X
 SG_ TAS_yellowWarningLamp: 39|1@1+ (1,0) [0|0] "" X

BO_ 845 TAS_warningMatrix1: 8 VEH
 SG_ TAS_w001_WatchdogReset: 0|1@1+ (1,0) [0|0] "" X
 SG_ TAS_w002_PowerLossReset: 1|1@1+ (1,0) [0|0] "" X
 SG_ TAS_w003_SWAssertion: 2|1@1+ (1,0) [0|0] "" X
 SG_ TAS_w004_CANMIA: 3|1@1+ (1,0) [0|0] "" X
 SG_ TAS_w005_CANHighError: 4|1@1+ (1,0) [0|0] "" X
 SG_ TAS_w006_CANLowError: 5|1@1+ (1,0) [0|0] "" X
 SG_ TAS_w007_LINTimeout: 6|1@1+ (1,0) [0|0] "" X
 SG_ TAS_w008_LIN2Error: 7|1@1+ (1,0) [0|0] "" X
 SG_ TAS_w009_LIN3Error: 8|1@1+ (1,0) [0|0] "" X
 SG_ TAS_w010_ExtSupplyVoltError: 9|1@1+ (1,0) [0|0] "" X
 SG_ TAS_w011_ECUSupplyVoltError: 10|1@1+ (1,0) [0|0] "" X
 SG_ TAS_w012_CPUReset: 11|1@1+ (1,0) [0|0] "" X
 SG_ TAS_w013_Shared13: 12|1@1+ (1,0) [0|0] "" X
 SG_ TAS_w014_BridgeFault: 13|1@1+ (1,0) [0|0] "" X
 SG_ TAS_w015_NVMMAlert: 14|1@1+ (1,0) [0|0] "" X
 SG_ TAS_w016_MessageTimingError: 15|1@1+ (1,0) [0|0] "" X
 SG_ TAS_w017_AwakeForTooLong: 16|1@1+ (1,0) [0|0] "" X
 SG_ TAS_w018_ADCError: 17|1@1+ (1,0) [0|0] "" X
 SG_ TAS_w019_I2CError: 18|1@1+ (1,0) [0|0] "" X
 SG_ TAS_w020_PWMError: 19|1@1+ (1,0) [0|0] "" X
 SG_ TAS_w021_TaskSchedulerError: 20|1@1+ (1,0) [0|0] "" X
 SG_ TAS_w022_TaskInitError: 21|1@1+ (1,0) [0|0] "" X
 SG_ TAS_w023_SleepError: 22|1@1+ (1,0) [0|0] "" X
 SG_ TAS_w024_WakeError: 23|1@1+ (1,0) [0|0] "" X
 SG_ TAS_w025_CrashEvent: 24|1@1+ (1,0) [0|0] "" X
 SG_ TAS_w026_FlashMemoryError: 25|1@1+ (1,0) [0|0] "" X
 SG_ TAS_w027_NVRAMCorruption: 26|1@1+ (1,0) [0|0] "" X
 SG_ TAS_w028_NVRAMNotResponding: 27|1@1+ (1,0) [0|0] "" X
 SG_ TAS_w029_NVRAMUninitialized: 28|1@1+ (1,0) [0|0] "" X
 SG_ TAS_w030_PWMerrorFL: 29|1@1+ (1,0) [0|0] "" X
 SG_ TAS_w031_PWMerrorFR: 30|1@1+ (1,0) [0|0] "" X
 SG_ TAS_w032_PWMerrorRL: 31|1@1+ (1,0) [0|0] "" X
 SG_ TAS_w033_PWMerrorRR: 32|1@1+ (1,0) [0|0] "" X
 SG_ TAS_w034_PWMshortFL: 33|1@1+ (1,0) [0|0] "" X
 SG_ TAS_w035_PWMshortFR: 34|1@1+ (1,0) [0|0] "" X
 SG_ TAS_w036_PWMshortRL: 35|1@1+ (1,0) [0|0] "" X
 SG_ TAS_w037_PWMshortRR: 36|1@1+ (1,0) [0|0] "" X
 SG_ TAS_w038_PWMopenFL: 37|1@1+ (1,0) [0|0] "" X
 SG_ TAS_w039_PWMopenFR: 38|1@1+ (1,0) [0|0] "" X
 SG_ TAS_w040_PWMopenRL: 39|1@1+ (1,0) [0|0] "" X
 SG_ TAS_w041_PWMopenRR: 40|1@1+ (1,0) [0|0] "" X

BO_ 877 TAS_warningMatrix2: 8 VEH
 SG_ TAS_w070_lowVoltage12V: 5|1@1+ (1,0) [0|0] "" X
 SG_ TAS_w071_highVoltage12V: 6|1@1+ (1,0) [0|0] "" X
 SG_ TAS_w072_shortCircuit5VS0: 7|1@1+ (1,0) [0|0] "" X
 SG_ TAS_w073_lowVoltage5VS0: 8|1@1+ (1,0) [0|0] "" X
 SG_ TAS_w074_shortCircuit5VS1: 9|1@1+ (1,0) [0|0] "" X
 SG_ TAS_w075_lowVoltage5VS1: 10|1@1+ (1,0) [0|0] "" X
 SG_ TAS_w076_highVoltage5VS1: 11|1@1+ (1,0) [0|0] "" X
 SG_ TAS_w077_pressureSigVTooLow: 12|1@1+ (1,0) [0|0] "" X
 SG_ TAS_w078_pressureSigVTooHigh: 13|1@1+ (1,0) [0|0] "" X
 SG_ TAS_w079_DvrSideCfgMismatch: 14|1@1+ (1,0) [0|0] "" X
 SG_ TAS_w080_pressureRefVTooLow: 15|1@1+ (1,0) [0|0] "" X
 SG_ TAS_w093_OTPError: 28|1@1+ (1,0) [0|0] "" X
 SG_ TAS_w098_VCFRONT_MIA: 33|1@1+ (1,0) [0|0] "" X
 SG_ TAS_w099_UI_MIA: 34|1@1+ (1,0) [0|0] "" X
 SG_ TAS_w100_RCM_MIA: 35|1@1+ (1,0) [0|0] "" X
 SG_ TAS_w101_ESP_MIA: 36|1@1+ (1,0) [0|0] "" X
 SG_ TAS_w102_DI_MIA: 37|1@1+ (1,0) [0|0] "" X
 SG_ TAS_w103_GTW_MIA: 38|1@1+ (1,0) [0|0] "" X
 SG_ TAS_w105_ECUDebugMode: 40|1@1+ (1,0) [0|0] "" X
 SG_ TAS_w106_HighCPULoad: 41|1@1+ (1,0) [0|0] "" X
 SG_ TAS_w107_HighStackUsage: 42|1@1+ (1,0) [0|0] "" X
 SG_ TAS_w121_maxDutyFL: 56|1@1+ (1,0) [0|0] "" X
 SG_ TAS_w122_maxDutyFR: 57|1@1+ (1,0) [0|0] "" X
 SG_ TAS_w123_maxDutyRL: 58|1@1+ (1,0) [0|0] "" X
 SG_ TAS_w124_maxDutyRR: 59|1@1+ (1,0) [0|0] "" X
 SG_ TAS_w125_maxDutyReservoir: 60|1@1+ (1,0) [0|0] "" X
 SG_ TAS_w126_maxDutyExhaust: 61|1@1+ (1,0) [0|0] "" X
 SG_ TAS_w127_maxDutyBoost: 62|1@1+ (1,0) [0|0] "" X
 SG_ TAS_w128_maxDutyCompressor: 63|1@1+ (1,0) [0|0] "" X

BO_ 909 TAS_warningMatrix3: 8 VEH
 SG_ TAS_w129_openCircuitFL: 0|1@1+ (1,0) [0|0] "" X
 SG_ TAS_w130_openCircuitFR: 1|1@1+ (1,0) [0|0] "" X
 SG_ TAS_w131_openCircuitRL: 2|1@1+ (1,0) [0|0] "" X
 SG_ TAS_w132_openCircuitRR: 3|1@1+ (1,0) [0|0] "" X
 SG_ TAS_w133_openCircuitReservoir: 4|1@1+ (1,0) [0|0] "" X
 SG_ TAS_w134_openCircuitExhaust: 5|1@1+ (1,0) [0|0] "" X
 SG_ TAS_w135_openCircuitBoost: 6|1@1+ (1,0) [0|0] "" X
 SG_ TAS_w136_openCircuitCompressor: 7|1@1+ (1,0) [0|0] "" X
 SG_ TAS_w137_shortCircuitFL: 8|1@1+ (1,0) [0|0] "" X
 SG_ TAS_w138_shortCircuitFR: 9|1@1+ (1,0) [0|0] "" X
 SG_ TAS_w139_shortCircuitRL: 10|1@1+ (1,0) [0|0] "" X
 SG_ TAS_w140_shortCircuitRR: 11|1@1+ (1,0) [0|0] "" X
 SG_ TAS_w141_shortCircuitReservoir: 12|1@1+ (1,0) [0|0] "" X
 SG_ TAS_w142_shortCircuitExhaust: 13|1@1+ (1,0) [0|0] "" X
 SG_ TAS_w143_shortCircuitBoost: 14|1@1+ (1,0) [0|0] "" X
 SG_ TAS_w144_shortCircuitCompressor: 15|1@1+ (1,0) [0|0] "" X
 SG_ TAS_w145_boardFaultFL: 16|1@1+ (1,0) [0|0] "" X
 SG_ TAS_w146_boardFaultFR: 17|1@1+ (1,0) [0|0] "" X
 SG_ TAS_w147_boardFaultRL: 18|1@1+ (1,0) [0|0] "" X
 SG_ TAS_w148_boardFaultRR: 19|1@1+ (1,0) [0|0] "" X
 SG_ TAS_w149_boardFaultReservoir: 20|1@1+ (1,0) [0|0] "" X
 SG_ TAS_w150_boardFaultExhaust: 21|1@1+ (1,0) [0|0] "" X
 SG_ TAS_w151_boardFaultBoost: 22|1@1+ (1,0) [0|0] "" X
 SG_ TAS_w152_boardFaultCompressor: 23|1@1+ (1,0) [0|0] "" X
 SG_ TAS_w153_otherCircuitFL: 24|1@1+ (1,0) [0|0] "" X
 SG_ TAS_w154_otherCircuitFR: 25|1@1+ (1,0) [0|0] "" X
 SG_ TAS_w155_otherCircuitRL: 26|1@1+ (1,0) [0|0] "" X
 SG_ TAS_w156_otherCircuitRR: 27|1@1+ (1,0) [0|0] "" X
 SG_ TAS_w157_otherCircuitReservoir: 28|1@1+ (1,0) [0|0] "" X
 SG_ TAS_w158_otherCircuitExhaust: 29|1@1+ (1,0) [0|0] "" X
 SG_ TAS_w159_otherCircuitBoost: 30|1@1+ (1,0) [0|0] "" X
 SG_ TAS_w160_otherCircuitCompressor: 31|1@1+ (1,0) [0|0] "" X
 SG_ TAS_w161_valveBlockOpenGND: 32|1@1+ (1,0) [0|0] "" X
 SG_ TAS_w162_compressorValveOpenGND: 33|1@1+ (1,0) [0|0] "" X
 SG_ TAS_w163_reservoirFillDisabled: 34|1@1+ (1,0) [0|0] "" X
 SG_ TAS_w164_calibrationVersion: 35|1@1+ (1,0) [0|0] "" X

BO_ 941 TAS_warningMatrix4: 8 VEH
 SG_ TAS_w200_jackModeActive: 7|1@1+ (1,0) [0|0] "" X
 SG_ TAS_w201_lowHVBattery: 8|1@1+ (1,0) [0|0] "" X
 SG_ TAS_w210_outOfRangeCalibration: 17|1@1+ (1,0) [0|0] "" X
 SG_ TAS_w211_noRideHeightCalib: 18|1@1+ (1,0) [0|0] "" X
 SG_ TAS_w212_noCurrentSenseCalib: 19|1@1+ (1,0) [0|0] "" X
 SG_ TAS_w213_yellowWarningLamp: 20|1@1+ (1,0) [0|0] "" X
 SG_ TAS_w214_redWarningLamp: 21|1@1+ (1,0) [0|0] "" X
 SG_ TAS_w215_limpHomeMode10: 22|1@1+ (1,0) [0|0] "" X
 SG_ TAS_w216_limpHomeMode20: 23|1@1+ (1,0) [0|0] "" X
 SG_ TAS_w217_limpHomeMode30: 24|1@1+ (1,0) [0|0] "" X
 SG_ TAS_w218_limpHomeMode40: 25|1@1+ (1,0) [0|0] "" X
 SG_ TAS_w220_exhaustGalleryFault: 27|1@1+ (1,0) [0|0] "" X
 SG_ TAS_w221_valveLeakDetected: 28|1@1+ (1,0) [0|0] "" X
 SG_ TAS_w222_compressorPrefillFault: 29|1@1+ (1,0) [0|0] "" X
 SG_ TAS_w223_blockedAirline: 30|1@1+ (1,0) [0|0] "" X
 SG_ TAS_w224_openAirline: 31|1@1+ (1,0) [0|0] "" X
 SG_ TAS_w225_galleryPressureTooHigh: 32|1@1+ (1,0) [0|0] "" X
 SG_ TAS_w226_PWMfastDetectFL: 33|1@1+ (1,0) [0|0] "" X
 SG_ TAS_w227_PWMfastDetectFR: 34|1@1+ (1,0) [0|0] "" X
 SG_ TAS_w228_PWMfastDetectRL: 35|1@1+ (1,0) [0|0] "" X
 SG_ TAS_w229_PWMfastDetectRR: 36|1@1+ (1,0) [0|0] "" X

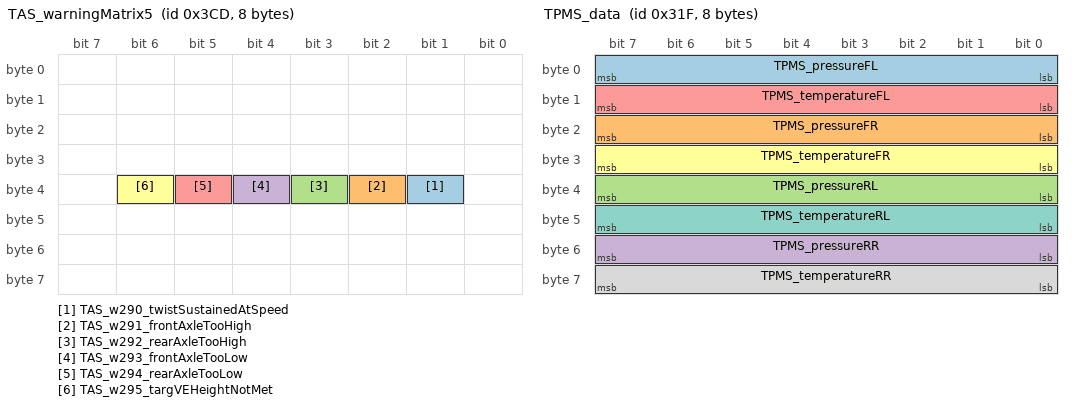
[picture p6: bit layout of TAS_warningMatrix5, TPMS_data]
BO_ 973 TAS_warningMatrix5: 8 VEH
 SG_ TAS_w290_twistSustainedAtSpeed: 33|1@1+ (1,0) [0|0] "" X
 SG_ TAS_w291_frontAxleTooHigh: 34|1@1+ (1,0) [0|0] "" X
 SG_ TAS_w292_rearAxleTooHigh: 35|1@1+ (1,0) [0|0] "" X
 SG_ TAS_w293_frontAxleTooLow: 36|1@1+ (1,0) [0|0] "" X
 SG_ TAS_w294_rearAxleTooLow: 37|1@1+ (1,0) [0|0] "" X
 SG_ TAS_w295_targVEHeightNotMet: 38|1@1+ (1,0) [0|0] "" X

BO_ 879 TPMS_StatusC: 8 CH
 SG_ TPMS_WA_version: 3|1@1+ (1,0) [0|0] "" X
 SG_ TPMS_c_globalHardWarning: 0|1@1+ (1,0) [0|0] "" X
 SG_ TPMS_c_globalSoftWarning: 1|1@1+ (1,0) [0|0] "" X
 SG_ TPMS_deltaPressWarningFL: 20|1@1+ (1,0) [0|0] "" X
 SG_ TPMS_deltaPressWarningFR: 21|1@1+ (1,0) [0|0] "" X
 SG_ TPMS_deltaPressWarningRL: 22|1@1+ (1,0) [0|0] "" X
 SG_ TPMS_deltaPressWarningRR: 23|1@1+ (1,0) [0|0] "" X
 SG_ TPMS_ecuOverVoltage: 41|1@1+ (1,0) [0|0] "" X
 SG_ TPMS_ecuRamRomNvMFail: 42|1@1+ (1,0) [0|0] "" X
 SG_ TPMS_ecuUnderVoltage: 40|1@1+ (1,0) [0|0] "" X
 SG_ TPMS_eolNotCompleted: 47|1@1+ (1,0) [0|0] "" X
 SG_ TPMS_externalTemperatureFail: 46|1@1+ (1,0) [0|0] "" X
 SG_ TPMS_globalDeltaPressure: 4|1@1+ (1,0) [0|0] "" X
 SG_ TPMS_hardWarningFL: 15|1@1+ (1,0) [0|0] "" X
 SG_ TPMS_hardWarningFR: 13|1@1+ (1,0) [0|0] "" X
 SG_ TPMS_hardWarningRL: 11|1@1+ (1,0) [0|0] "" X
 SG_ TPMS_hardWarningRR: 9|1@1+ (1,0) [0|0] "" X
 SG_ TPMS_learningStatus: 16|2@1+ (1,0) [0|0] "" X
 SG_ TPMS_localisationStatus: 18|2@1+ (1,0) [0|0] "" X
 SG_ TPMS_newSensorLearnt: 5|3@1+ (1,0) [0|0] "" X
 SG_ TPMS_rcpFront: 48|8@1+ (0.025,0) [0|0] "bar" X
 SG_ TPMS_rcpRear: 56|8@1+ (0.025,0) [0|0] "bar" X
 SG_ TPMS_rfReceiverFail: 43|1@1+ (1,0) [0|0] "" X
 SG_ TPMS_sensorBatteryLowFL: 32|1@1+ (1,0) [0|0] "" X
 SG_ TPMS_sensorBatteryLowFR: 33|1@1+ (1,0) [0|0] "" X
 SG_ TPMS_sensorBatteryLowRL: 34|1@1+ (1,0) [0|0] "" X
 SG_ TPMS_sensorBatteryLowRR: 35|1@1+ (1,0) [0|0] "" X
 SG_ TPMS_sensorDefectiveFL: 36|1@1+ (1,0) [0|0] "" X
 SG_ TPMS_sensorDefectiveFR: 37|1@1+ (1,0) [0|0] "" X
 SG_ TPMS_sensorDefectiveRL: 38|1@1+ (1,0) [0|0] "" X
 SG_ TPMS_sensorDefectiveRR: 39|1@1+ (1,0) [0|0] "" X
 SG_ TPMS_sensorNoResponseFL: 24|1@1+ (1,0) [0|0] "" X
 SG_ TPMS_sensorNoResponseFR: 25|1@1+ (1,0) [0|0] "" X
 SG_ TPMS_sensorNoResponseRL: 26|1@1+ (1,0) [0|0] "" X
 SG_ TPMS_sensorNoResponseRR: 27|1@1+ (1,0) [0|0] "" X
 SG_ TPMS_sensorThermShutdownFL: 28|1@1+ (1,0) [0|0] "" X
 SG_ TPMS_sensorThermShutdownFR: 29|1@1+ (1,0) [0|0] "" X
 SG_ TPMS_sensorThermShutdownRL: 30|1@1+ (1,0) [0|0] "" X
 SG_ TPMS_sensorThermShutdownRR: 31|1@1+ (1,0) [0|0] "" X
 SG_ TPMS_softWarningFL: 14|1@1+ (1,0) [0|0] "" X
 SG_ TPMS_softWarningFR: 12|1@1+ (1,0) [0|0] "" X
 SG_ TPMS_softWarningRL: 10|1@1+ (1,0) [0|0] "" X
 SG_ TPMS_softWarningRR: 8|1@1+ (1,0) [0|0] "" X
 SG_ TPMS_systemMalfunction: 2|1@1+ (1,0) [0|0] "" X
 SG_ TPMS_vehicleSpeedFail: 45|1@1+ (1,0) [0|0] "" X
 SG_ TPMS_wheelPulseMissing: 44|1@1+ (1,0) [0|0] "" X

BO_ 799 TPMS_data: 8 CH
 SG_ TPMS_pressureFL: 0|8@1+ (0.025,0) [0|0] "bar" X
 SG_ TPMS_pressureFR: 16|8@1+ (0.025,0) [0|0] "bar" X
 SG_ TPMS_pressureRL: 32|8@1+ (0.025,0) [0|0] "bar" X
 SG_ TPMS_pressureRR: 48|8@1+ (0.025,0) [0|0] "bar" X
 SG_ TPMS_temperatureFL: 8|8@1+ (1,-40) [0|0] "degC" X
 SG_ TPMS_temperatureFR: 24|8@1+ (1,-40) [0|0] "degC" X
 SG_ TPMS_temperatureRL: 40|8@1+ (1,-40) [0|0] "degC" X
 SG_ TPMS_temperatureRR: 56|8@1+ (1,-40) [0|0] "degC" X

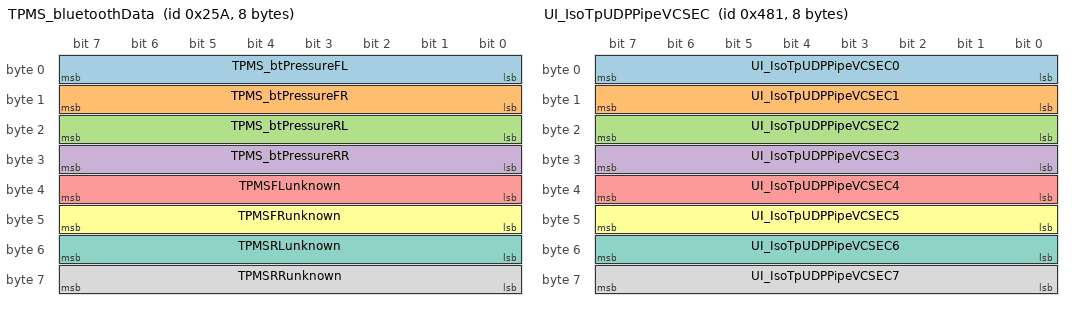
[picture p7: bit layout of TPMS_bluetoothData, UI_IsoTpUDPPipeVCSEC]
BO_ 602 TPMS_bluetoothData: 8 CH
SG_ TPMS_btPressureFL : 0|8@1+ (0.025,0) [0|6.375] "bar" X
SG_ TPMS_btPressureFR : 8|8@1+ (0.025,0) [0|6.375] "bar" X
SG_ TPMS_btPressureRL : 16|8@1+ (0.025,0) [0|6.375] "bar" X
SG_ TPMS_btPressureRR : 24|8@1+ (0.025,0) [0|6.375] "bar" X
SG_ TPMSFLunknown : 32|8@1+ (1,0) [0|0] "" X
SG_ TPMSFRunknown : 40|8@1+ (1,0) [0|0] "" X
SG_ TPMSRLunknown : 48|8@1+ (1,0) [0|0] "" X
SG_ TPMSRRunknown : 56|8@1+ (1,0) [0|0] "" X

BO_ 1519 TPMS_info: 8 CH
 SG_ TPMS_infoIndex M: 0|8@1+ (1,0) [0|0] "" X
 SG_ TPMS_infoComponentID m10: 48|16@1+ (1,0) [0|0] "" X
 SG_ TPMS_infoPcbaID m11: 16|8@1+ (1,0) [0|0] "" X
 SG_ TPMS_infoAssemblyID m11: 24|8@1+ (1,0) [0|0] "" X
 SG_ TPMS_infoUsageID m11: 32|16@1+ (1,0) [0|0] "" X
 SG_ TPMS_infoBootUdsProtoVersion m20: 8|8@1+ (1,0) [0|0] "" X
 SG_ TPMS_infoBootloaderCRC m20: 32|32@1+ (1,0) [0|0] "" X
 SG_ TPMS_infoApplicationCRC m13: 32|32@1+ (1,0) [0|0] "" X

BO_ 1153 UI_IsoTpUDPPipeVCSEC: 8 VEH
 SG_ UI_IsoTpUDPPipeVCSEC0: 0|8@1+ (1,0) [0|0] "" X
 SG_ UI_IsoTpUDPPipeVCSEC1: 8|8@1+ (1,0) [0|0] "" X
 SG_ UI_IsoTpUDPPipeVCSEC2: 16|8@1+ (1,0) [0|0] "" X
 SG_ UI_IsoTpUDPPipeVCSEC3: 24|8@1+ (1,0) [0|0] "" X
 SG_ UI_IsoTpUDPPipeVCSEC4: 32|8@1+ (1,0) [0|0] "" X
 SG_ UI_IsoTpUDPPipeVCSEC5: 40|8@1+ (1,0) [0|0] "" X
 SG_ UI_IsoTpUDPPipeVCSEC6: 48|8@1+ (1,0) [0|0] "" X
 SG_ UI_IsoTpUDPPipeVCSEC7: 56|8@1+ (1,0) [0|0] "" X

BO_ 979 UI_airbagCutoffStatus: 1 VEH
 SG_ UI_airbagCutoffSwState: 0|2@1+ (1,0) [0|0] "" X
 SG_ UI_warningIndicatorStatus: 2|2@1+ (1,0) [0|0] "" X

BO_ 1523 UI_alertLog: 8 VEH
 SG_ UI_alertID M: 0|6@1+ (1,0) [0|0] "" X
 SG_ UI_alertState: 15|1@1+ (1,0) [0|0] "" X
 SG_ UI_a034_BackupCamera m34: 16|1@1+ (1,0) [0|0] "" X
 SG_ UI_a034_Tuner m34: 17|1@1+ (1,0) [0|0] "" X
 SG_ UI_a034_Bluetooth m34: 18|1@1+ (1,0) [0|0] "" X
 SG_ UI_a034_WiFi m34: 19|1@1+ (1,0) [0|0] "" X
 SG_ UI_a034_Cellular m34: 20|1@1+ (1,0) [0|0] "" X
 SG_ UI_a034_TouchScreen m34: 21|1@1+ (1,0) [0|0] "" X
 SG_ UI_a034_Display m34: 22|1@1+ (1,0) [0|0] "" X
 SG_ UI_a034_Audio m34: 23|1@1+ (1,0) [0|0] "" X
 SG_ UI_a034_FatalWakeup m34: 24|1@1+ (1,0) [0|0] "" X
 SG_ UI_a034_UnknownWakeupError m34: 25|1@1+ (1,0) [0|0] "" X
 SG_ UI_a006_remoteServiceAlertCode m6: 16|32@1+ (1,0) [0|0] "" X

BO_ 291 UI_alertMatrix1: 8 VEH
 SG_ UI_a001_DriverDoorOpen: 0|1@1+ (1,0) [0|0] "" X
 SG_ UI_a002_DoorOpen: 1|1@1+ (1,0) [0|0] "" X
 SG_ UI_a003_TrunkOpen: 2|1@1+ (1,0) [0|0] "" X
 SG_ UI_a004_FrunkOpen: 3|1@1+ (1,0) [0|0] "" X
 SG_ UI_a005_HeadlightsOnDoorOpen: 4|1@1+ (1,0) [0|0] "" X
 SG_ UI_a006_RemoteServiceAlert: 5|1@1+ (1,0) [0|0] "" X
 SG_ UI_a007_SoftPackConfigMismatch: 6|1@1+ (1,0) [0|0] "" X
 SG_ UI_a008_TouchScreenError: 7|1@1+ (1,0) [0|0] "" X
 SG_ UI_a009_SquashfsError: 8|1@1+ (1,0) [0|0] "" X
 SG_ UI_a010_MapsMissing: 9|1@1+ (1,0) [0|0] "" X
 SG_ UI_a011_IncorrectMap: 10|1@1+ (1,0) [0|0] "" X
 SG_ UI_a012_NotOnPrivateProperty: 11|1@1+ (1,0) [0|0] "" X
 SG_ UI_a013_TPMSHardWarning: 12|1@1+ (1,0) [0|0] "" X
 SG_ UI_a014_TPMSSoftWarning: 13|1@1+ (1,0) [0|0] "" X
 SG_ UI_a015_TPMSOverPressureWarning: 14|1@1+ (1,0) [0|0] "" X
 SG_ UI_a016_TPMSTemperatureWarning: 15|1@1+ (1,0) [0|0] "" X
 SG_ UI_a017_TPMSSystemFault: 16|1@1+ (1,0) [0|0] "" X
 SG_ UI_a018_SlipStartOn: 17|1@1+ (1,0) [0|0] "" X
 SG_ UI_a019_ParkBrakeFault: 18|1@1+ (1,0) [0|0] "" X
 SG_ UI_a020_SteeringReduced: 19|1@1+ (1,0) [0|0] "" X
 SG_ UI_a021_RearSeatbeltUnbuckled: 20|1@1+ (1,0) [0|0] "" X
 SG_ UI_a022_ApeFusesEtc: 21|1@1+ (1,0) [0|0] "" X
 SG_ UI_a023_CellInternetCheckFailed: 22|1@1+ (1,0) [0|0] "" X
 SG_ UI_a024_WifiInternetCheckFailed: 23|1@1+ (1,0) [0|0] "" X
 SG_ UI_a025_WifiOnlineCheckFailed: 24|1@1+ (1,0) [0|0] "" X
 SG_ UI_a026_ModemResetLoopDetected: 25|1@1+ (1,0) [0|0] "" X
 SG_ UI_a027_AutoSteerMIA: 26|1@1+ (1,0) [0|0] "" X
 SG_ UI_a028_FrontTrunkPopupClosed: 27|1@1+ (1,0) [0|0] "" X
 SG_ UI_a029_ModemMIA: 28|1@1+ (1,0) [0|0] "" X
 SG_ UI_a030_ModemVMCrash: 29|1@1+ (1,0) [0|0] "" X
 SG_ UI_a031_BrakeFluidLow: 30|1@1+ (1,0) [0|0] "" X
 SG_ UI_a032_CellModemRecoveryResets: 31|1@1+ (1,0) [0|0] "" X
 SG_ UI_a033_ApTrialExpired: 32|1@1+ (1,0) [0|0] "" X
 SG_ UI_a034_WakeupProblem: 33|1@1+ (1,0) [0|0] "" X
 SG_ UI_a035_AudioWatchdogKernelError: 34|1@1+ (1,0) [0|0] "" X
 SG_ UI_a036_AudioWatchdogHfpError: 35|1@1+ (1,0) [0|0] "" X
 SG_ UI_a037_AudioWatchdogXrunStormError: 36|1@1+ (1,0) [0|0] "" X
 SG_ UI_a038_AudioWatchdogA2bI2cLockupError: 37|1@1+ (1,0) [0|0] "" X
 SG_ UI_a039_AudioA2bNeedRediscovery: 38|1@1+ (1,0) [0|0] "" X
 SG_ UI_a040_HomelinkTransmit: 39|1@1+ (1,0) [0|0] "" X
 SG_ UI_a041_AudioDmesgXrun: 40|1@1+ (1,0) [0|0] "" X
 SG_ UI_a042_AudioDmesgRtThrottling: 41|1@1+ (1,0) [0|0] "" X
 SG_ UI_a043_InvalidMapDataOverride: 42|1@1+ (1,0) [0|0] "" X
 SG_ UI_a044_AudioDmesgDspException: 43|1@1+ (1,0) [0|0] "" X

BO_ 1021 UI_autopilotControl: 8 CH
 SG_ UI_autopilotControlIndex M : 0|3@1+ (1,0) [0|7] "" X
 SG_ UI_apmv3Branch m1 : 40|3@1+ (1,0) [0|5] "" X
 SG_ UI_applyEceR79 m1 : 19|1@1+ (1,0) [0|1] "" X
 SG_ UI_blindspotDistance m0 : 15|3@1+ (1,0) [0|5] "" X
 SG_ UI_blindspotMinSpeed m0 : 11|4@1+ (1,0) [0|10] "" X
 SG_ UI_blindspotTTC m0 : 18|3@1+ (1,0) [0|7] "" X
 SG_ UI_disableBackup m1 : 30|1@1+ (1,0) [0|1] "" X
 SG_ UI_disableFisheye m1 : 25|1@1+ (1,0) [0|1] "" X
 SG_ UI_disableLeftPillar m1 : 26|1@1+ (1,0) [0|1] "" X
 SG_ UI_disableLeftRepeater m1 : 28|1@1+ (1,0) [0|1] "" X
 SG_ UI_disableMain m1 : 23|1@1+ (1,0) [0|1] "" X
 SG_ UI_disableNarrow m1 : 24|1@1+ (1,0) [0|1] "" X
 SG_ UI_disableRadar m1 : 31|1@1+ (1,0) [0|1] "" X
 SG_ UI_disableRightPillar m1 : 27|1@1+ (1,0) [0|1] "" X
 SG_ UI_disableRightRepeater m1 : 29|1@1+ (1,0) [0|1] "" X
 SG_ UI_donAlcProgGoreAbortThres m0 : 29|4@1+ (1,0) [0|9] "" X
 SG_ UI_donDisableAutoWiperDuration m0 : 4|3@1+ (1,0) [0|6] "" X
 SG_ UI_donDisableCutin m0 : 24|1@1+ (1,0) [0|1] "" X
 SG_ UI_donDisableOnAutoWiperSpeed m0 : 7|4@1+ (1,0) [0|15] "" X
 SG_ UI_donMinGoreWidthForAbortMap m0 : 25|4@1+ (1,0) [0|11] "" X
 SG_ UI_donMinGoreWidthForAbortNotMap m0 : 33|4@1+ (1,0) [0|11] "" X
 SG_ UI_donStopEndOfRampBuffer m0 : 21|3@1+ (1,0) [0|4] "" X
 SG_ UI_driverMonitorConfirmation m1 : 17|1@1+ (1,0) [0|1] "" X
 SG_ UI_enableAutopilotStopWarning m1 : 44|1@1+ (1,0) [0|1] "" X
 SG_ UI_enableCabinCamera m1 : 43|1@1+ (1,0) [0|1] "" X
 SG_ UI_enableCabinCameraTelemetry m1 : 48|1@1+ (1,0) [0|1] "" X
 SG_ UI_enableMapStops m1 : 20|1@1+ (1,0) [0|1] "" X
 SG_ UI_factorySummonEnable m1 : 39|1@1+ (1,0) [0|1] "" X
 SG_ UI_fsdStopsControlEnabled m0 : 38|1@1+ (1,0) [0|1] "" X
 SG_ UI_fsdVisualizationEnabled m0 : 37|1@1+ (1,0) [0|1] "" X
 SG_ UI_hardCoreSummon m1 : 47|1@1+ (1,0) [0|1] "" X
 SG_ UI_homelinkNearby m0 : 45|1@1+ (1,0) [0|1] "" X
 SG_ UI_hovEnabled m0 : 3|1@1+ (1,0) [0|1] "" X
 SG_ UI_noStalkConfirmAlertChime m1 : 37|1@1+ (1,0) [0|1] "" X
 SG_ UI_noStalkConfirmAlertHaptic m1 : 32|1@1+ (1,0) [0|1] "" X
 SG_ UI_showLaneGraph m1 : 45|1@1+ (1,0) [0|1] "" X
 SG_ UI_showTrackLabels m1 : 46|1@1+ (1,0) [0|1] "" X
 SG_ UI_ulcSnooze m1 : 36|1@1+ (1,0) [0|1] "" X

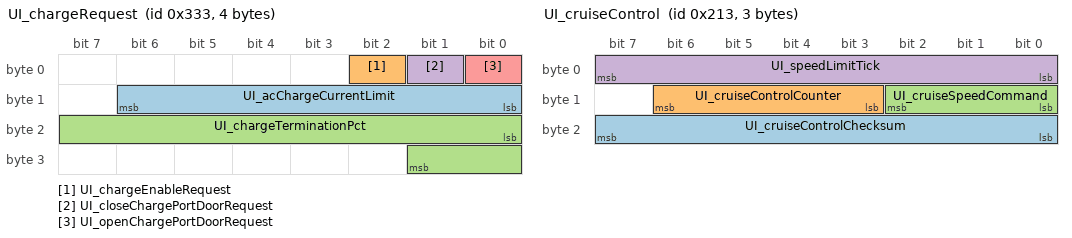
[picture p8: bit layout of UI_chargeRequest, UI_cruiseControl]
BO_ 819 UI_chargeRequest: 4 VEH
 SG_ UI_acChargeCurrentLimit: 8|7@1+ (1,0) [0|0] "A" X
 SG_ UI_chargeEnableRequest: 2|1@1+ (1,0) [0|0] "" X
 SG_ UI_chargeTerminationPct: 16|10@1+ (0.1,0) [0|0] "%" X
 SG_ UI_closeChargePortDoorRequest: 1|1@1+ (1,0) [0|0] "" X
 SG_ UI_openChargePortDoorRequest: 0|1@1+ (1,0) [0|0] "" X

BO_ 659 UI_chassisControl: 8 VEH
 SG_ UI_accOvertakeEnable: 18|2@1+ (1,0) [0|0] "" X
 SG_ UI_aebEnable: 20|2@1+ (1,0) [0|0] "" X
 SG_ UI_aesEnable: 22|2@1+ (1,0) [0|0] "" X
 SG_ UI_ahlbEnable: 24|2@1+ (1,0) [0|0] "" X
 SG_ UI_autoLaneChangeEnable: 32|2@1+ (1,0) [0|0] "" X
 SG_ UI_autoParkRequest: 28|4@1+ (1,0) [0|0] "" X
 SG_ UI_bsdEnable: 34|2@1+ (1,0) [0|0] "" X
 SG_ UI_chassisControlChecksum: 56|8@1+ (1,0) [0|0] "" X
 SG_ UI_chassisControlCounter: 52|4@1+ (1,0) [0|0] "" X
 SG_ UI_dasDebugEnable: 17|1@1+ (1,0) [0|0] "" X
 SG_ UI_distanceUnits: 16|1@1+ (1,0) [0|0] "" X
 SG_ UI_fcwEnable: 36|2@1+ (1,0) [0|0] "" X
 SG_ UI_fcwSensitivity: 38|2@1+ (1,0) [0|0] "" X
 SG_ UI_latControlEnable: 40|2@1+ (1,0) [0|0] "" X
 SG_ UI_ldwEnable: 42|2@1+ (1,0) [0|0] "" X
 SG_ UI_narrowGarages: 7|1@1+ (1,0) [0|0] "" X
 SG_ UI_parkBrakeRequest: 5|2@1+ (1,0) [0|0] "" X
 SG_ UI_pedalSafetyEnable: 44|2@1+ (1,0) [0|0] "" X
 SG_ UI_rebootAutopilot: 27|1@1+ (1,0) [0|0] "" X
 SG_ UI_redLightStopSignEnable: 46|2@1+ (1,0) [0|0] "" X
 SG_ UI_selfParkTune: 48|4@1+ (1,0) [0|0] "" X
 SG_ UI_steeringTuneRequest: 0|2@1+ (1,0) [0|0] "" X
 SG_ UI_suspensionLevelRequest: 13|3@1+ (1,0) [0|0] "" X
 SG_ UI_tractionControlMode: 2|3@1+ (1,0) [0|0] "" X
 SG_ UI_trailerMode: 12|1@1+ (1,0) [0|0] "" X
 SG_ UI_winchModeRequest: 8|2@1+ (1,0) [0|0] "" X
 SG_ UI_zeroSpeedConfirmed: 10|2@1+ (1,0) [0|0] "" X

BO_ 531 UI_cruiseControl: 3 VEH
 SG_ UI_cruiseControlChecksum: 16|8@1+ (1,0) [0|0] "" X
 SG_ UI_cruiseControlCounter: 11|4@1+ (1,0) [0|0] "" X
 SG_ UI_cruiseSpeedCommand: 8|3@1+ (1,0) [0|0] "" X
 SG_ UI_speedLimitTick: 0|8@1+ (1,0) [0|0] "speed" X

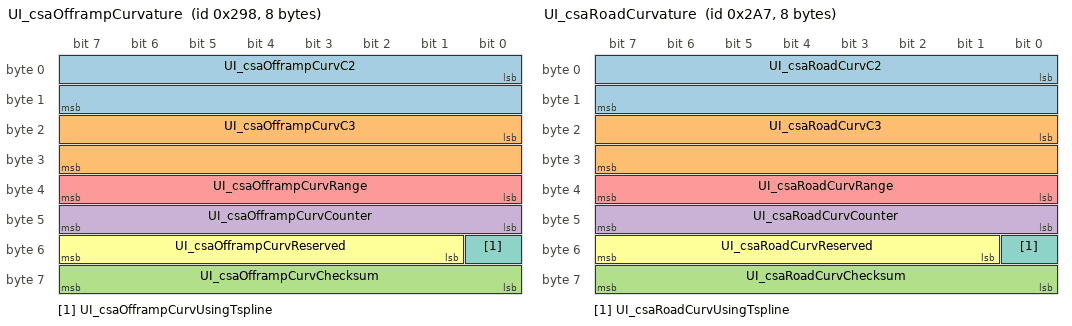
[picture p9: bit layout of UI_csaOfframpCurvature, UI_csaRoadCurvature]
BO_ 664 UI_csaOfframpCurvature: 8 VEH
 SG_ UI_csaOfframpCurvC2: 0|16@1- (1e-06,0) [0|0] "1/m" X
 SG_ UI_csaOfframpCurvC3: 16|16@1- (4e-09,0) [0|0] "1/m2" X
 SG_ UI_csaOfframpCurvChecksum: 56|8@1+ (1,0) [0|0] "" X
 SG_ UI_csaOfframpCurvCounter: 40|8@1+ (1,0) [0|0] "" X
 SG_ UI_csaOfframpCurvRange: 32|8@1+ (2,0) [0|0] "m" X
 SG_ UI_csaOfframpCurvReserved: 49|7@1+ (1,0) [0|0] "" X
 SG_ UI_csaOfframpCurvUsingTspline: 48|1@1+ (1,0) [0|0] "" X

BO_ 679 UI_csaRoadCurvature: 8 VEH
 SG_ UI_csaRoadCurvC2: 0|16@1- (1e-06,0) [0|0] "1/m" X
 SG_ UI_csaRoadCurvC3: 16|16@1- (4e-09,0) [0|0] "1/m2" X
 SG_ UI_csaRoadCurvChecksum: 56|8@1+ (1,0) [0|0] "" X
 SG_ UI_csaRoadCurvCounter: 40|8@1+ (1,0) [0|0] "" X
 SG_ UI_csaRoadCurvRange: 32|8@1+ (2,0) [0|0] "m" X
 SG_ UI_csaRoadCurvReserved: 49|7@1+ (1,0) [0|0] "" X
 SG_ UI_csaRoadCurvUsingTspline: 48|1@1+ (1,0) [0|0] "" X

BO_ 1280 UI_debugECU: 2 VEH
 SG_ UI_debugEcuTarget M: 0|3@1+ (1,0) [0|0] "" X
 SG_ UI_DI_debugEnable m1: 8|1@1+ (1,0) [0|0] "" X
 SG_ UI_DIS_debugEnable m2: 8|1@1+ (1,0) [0|0] "" X
 SG_ UI_PM_debugEnable m3: 8|1@1+ (1,0) [0|0] "" X
 SG_ UI_PM_debugAt100Hz m3: 9|1@1+ (1,0) [0|0] "" X
 SG_ UI_PMS_debugEnable m4: 8|1@1+ (1,0) [0|0] "" X
 SG_ UI_PMS_debugAt100Hz m4: 9|1@1+ (1,0) [0|0] "" X
 SG_ UI_BMS_debugAllEnable m5: 8|1@1+ (1,0) [0|0] "" X
 SG_ UI_BMS_debugDisable m5: 9|1@1+ (1,0) [0|0] "" X
 SG_ UI_VCRIGHT_debugEnable m6: 8|1@1+ (1,0) [0|0] "" X
 SG_ UI_VCFRONT_debugEnable m7: 3|1@1+ (1,0) [0|0] "" X

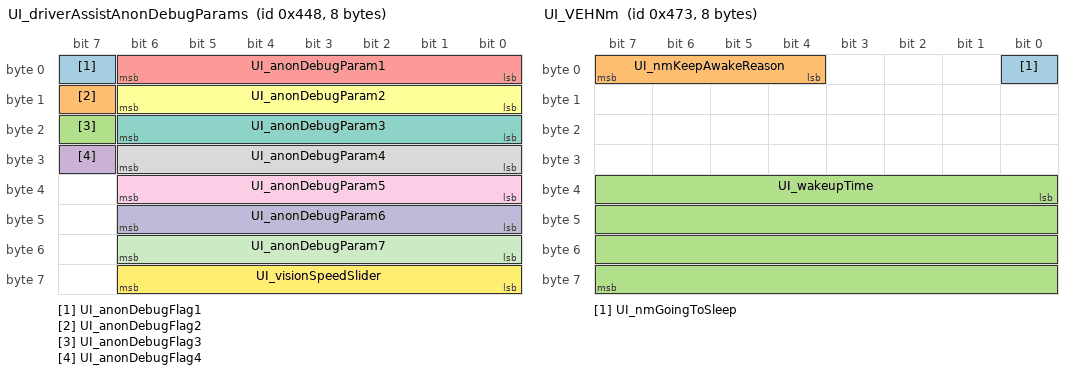
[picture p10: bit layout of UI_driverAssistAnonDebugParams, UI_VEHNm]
BO_ 1096 UI_driverAssistAnonDebugParams: 8 VEH
 SG_ UI_anonDebugFlag1: 7|1@1+ (1,0) [0|0] "" X
 SG_ UI_anonDebugFlag2: 15|1@1+ (1,0) [0|0] "" X
 SG_ UI_anonDebugFlag3: 23|1@1+ (1,0) [0|0] "" X
 SG_ UI_anonDebugFlag4: 31|1@1+ (1,0) [0|0] "" X
 SG_ UI_anonDebugParam1: 0|7@1+ (1,0) [0|0] "" X
 SG_ UI_anonDebugParam2: 8|7@1+ (1,0) [0|0] "" X
 SG_ UI_anonDebugParam3: 16|7@1+ (1,0) [0|0] "" X
 SG_ UI_anonDebugParam4: 24|7@1+ (1,0) [0|0] "" X
 SG_ UI_anonDebugParam5: 32|7@1+ (1,0) [0|0] "" X
 SG_ UI_anonDebugParam6: 40|7@1+ (1,0) [0|0] "" X
 SG_ UI_anonDebugParam7: 48|7@1+ (1,0) [0|0] "" X
 SG_ UI_visionSpeedSlider: 56|7@1+ (1,0) [0|0] "" X

BO_ 1016 UI_driverAssistControl: 8 CH
 SG_ UI_accFollowDistanceSetting: 45|3@1+ (1,0) [0|0] "" X
 SG_ UI_accFromZero: 55|1@1+ (1,0) [0|0] "" X
 SG_ UI_adaptiveSetSpeedEnable: 39|1@1+ (1,0) [0|0] "" X
 SG_ UI_alcOffHighwayEnable: 56|1@1+ (1,0) [0|0] "" X
 SG_ UI_autoSummonEnable: 10|1@1+ (1,0) [0|0] "" X
 SG_ UI_autopilotAlwaysOn: 54|1@1+ (1,0) [0|0] "" X
 SG_ UI_autopilotControlRequest: 0|1@1+ (1,0) [0|0] "" X
 SG_ UI_curvSpeedAdaptDisable: 4|1@1+ (1,0) [0|0] "" X
 SG_ UI_curvatureDatabaseOnly: 22|1@1+ (1,0) [0|0] "" X
 SG_ UI_dasDeveloper: 5|1@1+ (1,0) [0|0] "" X
 SG_ UI_driveOnMapsEnable: 13|1@1+ (1,0) [0|0] "" X
 SG_ UI_drivingSide: 40|2@1+ (1,0) [0|0] "" X
 SG_ UI_enableClipTelemetry: 42|1@1+ (1,0) [0|0] "" X
 SG_ UI_enableCutinExperiments: 59|1@1+ (1,0) [0|0] "" X
 SG_ UI_enableNavRouteCSA: 58|1@1+ (1,0) [0|0] "" X
 SG_ UI_enableNextGenACC: 19|1@1+ (1,0) [0|0] "" X
 SG_ UI_enableRoadSegmentTelemetry: 44|1@1+ (1,0) [0|0] "" X
 SG_ UI_enableTripTelemetry: 43|1@1+ (1,0) [0|0] "" X
 SG_ UI_enableVinAssociation: 6|1@1+ (1,0) [0|0] "" X
 SG_ UI_enableVisionOnlyStops: 60|1@1+ (1,0) [0|0] "" X
 SG_ UI_exceptionListEnable: 11|1@1+ (1,0) [0|0] "" X
 SG_ UI_followNavRouteEnable: 49|1@1+ (1,0) [0|0] "" X
 SG_ UI_forksEnable: 63|1@1+ (1,0) [0|0] "" X
 SG_ UI_fuseHPPDisable: 17|1@1+ (1,0) [0|0] "" X
 SG_ UI_fuseLanesDisable: 16|1@1+ (1,0) [0|0] "" X
 SG_ UI_fuseVehiclesDisable: 18|1@1+ (1,0) [0|0] "" X
 SG_ UI_handsOnRequirementDisable: 14|1@1+ (1,0) [0|0] "" X
 SG_ UI_lssElkEnabled: 23|1@1+ (1,0) [0|0] "" X
 SG_ UI_lssLdwEnabled: 8|1@1+ (1,0) [0|0] "" X
 SG_ UI_lssLkaEnabled: 7|1@1+ (1,0) [0|0] "" X
 SG_ UI_roadCheckDisable: 12|1@1+ (1,0) [0|0] "" X
 SG_ UI_selfParkRequest: 28|4@1+ (1,0) [0|0] "" X
 SG_ UI_source3D: 61|2@1+ (1,0) [0|0] "" X
 SG_ UI_summonEntryType: 26|2@1+ (1,0) [0|0] "" X
 SG_ UI_summonExitType: 24|2@1+ (1,0) [0|0] "" X
 SG_ UI_summonHeartbeat: 2|2@1+ (1,0) [0|0] "" X
 SG_ UI_summonReverseDist: 32|6@1+ (1,0) [0|0] "" X
 SG_ UI_ulcBlindSpotConfig: 52|2@1+ (1,0) [0|0] "" X
 SG_ UI_ulcOffHighway: 15|1@1+ (1,0) [0|0] "" X
 SG_ UI_ulcSpeedConfig: 50|2@1+ (1,0) [0|0] "" X
 SG_ UI_ulcStalkConfirm: 1|1@1+ (1,0) [0|0] "" X
 SG_ UI_undertakeAssistEnable: 38|1@1+ (1,0) [0|0] "" X
 SG_ UI_validationLoop: 57|1@1+ (1,0) [0|0] "" X
 SG_ UI_visionSpeedType: 20|2@1+ (1,0) [0|0] "" X

BO_ 568 UI_driverAssistMapData: 8 CH
 SG_ UI_acceptBottsDots: 48|1@1+ (1,0) [0|0] "" X
 SG_ UI_autosteerRestricted: 49|1@1+ (1,0) [0|0] "" X
 SG_ UI_controlledAccess: 37|1@1+ (1,0) [0|0] "" X
 SG_ UI_countryCode: 16|10@1+ (1,0) [0|0] "" X
 SG_ UI_gpsRoadMatch: 28|1@1+ (1,0) [0|0] "" X
 SG_ UI_inSuperchargerGeofence: 6|1@1+ (1,0) [0|0] "" X
 SG_ UI_mapDataChecksum: 56|8@1+ (1,0) [0|0] "" X
 SG_ UI_mapDataCounter: 52|4@1+ (1,0) [0|0] "" X
 SG_ UI_mapSpeedLimit: 8|5@1+ (1,0) [0|0] "" X
 SG_ UI_mapSpeedLimitDependency: 0|3@1+ (1,0) [0|0] "" X
 SG_ UI_mapSpeedLimitType: 13|3@1+ (1,0) [0|0] "" X
 SG_ UI_mapSpeedUnits: 7|1@1+ (1,0) [0|0] "" X
 SG_ UI_navRouteActive: 29|1@1+ (1,0) [0|0] "" X
 SG_ UI_nextBranchDist: 32|5@1+ (10,0) [0|0] "m" X
 SG_ UI_nextBranchLeftOffRamp: 38|1@1+ (1,0) [0|0] "" X
 SG_ UI_nextBranchRightOffRamp: 39|1@1+ (1,0) [0|0] "" X
 SG_ UI_parallelAutoparkEnabled: 30|1@1+ (1,0) [0|0] "" X
 SG_ UI_perpendicularAutoparkEnabled: 31|1@1+ (1,0) [0|0] "" X
 SG_ UI_pmmEnabled: 50|1@1+ (1,0) [0|0] "" X
 SG_ UI_rejectAutosteer: 46|1@1+ (1,0) [0|0] "" X
 SG_ UI_rejectHPP: 42|1@1+ (1,0) [0|0] "" X
 SG_ UI_rejectHandsOn: 47|1@1+ (1,0) [0|0] "" X
 SG_ UI_rejectLeftFreeSpace: 44|1@1+ (1,0) [0|0] "" X
 SG_ UI_rejectLeftLane: 40|1@1+ (1,0) [0|0] "" X
 SG_ UI_rejectNav: 43|1@1+ (1,0) [0|0] "" X
 SG_ UI_rejectRightFreeSpace: 45|1@1+ (1,0) [0|0] "" X
 SG_ UI_rejectRightLane: 41|1@1+ (1,0) [0|0] "" X
 SG_ UI_roadClass: 3|3@1+ (1,0) [0|0] "" X
 SG_ UI_scaEnabled: 51|1@1+ (1,0) [0|0] "" X
 SG_ UI_streetCount: 26|2@1+ (1,0) [0|0] "" X

BO_ 536 UI_driverAssistRoadSign: 8 VEH
 SG_ UI_roadSign M: 0|8@1+ (1,0) [0|0] "" X
 SG_ UI_roadSignChecksum: 56|8@1+ (1,0) [0|0] "" X
 SG_ UI_roadSignCounter: 52|4@1+ (1,0) [0|0] "" X
 SG_ UI_splineID: 48|4@1+ (1,0) [0|0] "" X
 SG_ UI_splineLocConfidence: 40|7@1+ (1,0) [0|0] "1" X
 SG_ UI_dummyData m0: 8|1@1+ (1,0) [0|0] "" X
 SG_ UI_stopSignStopLineDist m1: 8|10@1+ (0.25,-8) [0|0] "m" X
 SG_ UI_stopSignStopLineConf m1: 18|7@1+ (1,0) [0|0] "1" X
 SG_ UI_trafficLightStopLineDist m2: 8|10@1+ (0.25,-8) [0|0] "m" X
 SG_ UI_trafficLightStopLineConf m2: 18|7@1+ (1,0) [0|0] "1" X
 SG_ UI_baseMapSpeedLimitMPS m3: 8|8@1+ (0.25,0) [0|0] "m/s" X
 SG_ UI_bottomQrtlFleetSpeedMPS m3: 16|8@1+ (0.25,0) [0|0] "m/s" X
 SG_ UI_topQrtlFleetSpeedMPS m3: 24|8@1+ (0.25,0) [0|0] "m/s" X
 SG_ UI_meanFleetSplineSpeedMPS m4: 8|8@1+ (0.25,0) [0|0] "m/s" X
 SG_ UI_medianFleetSpeedMPS m4: 16|8@1+ (0.25,0) [0|0] "m/s" X
 SG_ UI_meanFleetSplineAccelMPS2 m4: 24|8@1+ (0.05,-6.35) [0|0] "m/s^2" X
 SG_ UI_rampType m4: 32|3@1+ (1,0) [0|0] "" X
 SG_ UI_currSplineIdFull m5: 8|32@1+ (1,0) [0|0] "1" X

BO_ 645 UI_driverProfileRecall: 8 VEH
 SG_ UI_driverProfileRecallIndex M: 0|3@1+ (1,0) [0|0] "" X
 SG_ UI_driverProfileRecallStop: 3|1@1+ (1,0) [0|0] "" X
 SG_ UI_frontSeatRecallActive m1: 4|1@1+ (1,0) [0|0] "" X
 SG_ UI_frontSeatTrackPos m1: 5|10@1- (4,0) [0|0] "mm" X
 SG_ UI_frontSeatBackPos m1: 16|12@1- (0.1,0) [0|0] "deg" X
 SG_ UI_frontSeatLiftPos m1: 32|10@1- (4,0) [0|0] "mm" X
 SG_ UI_frontSeatTiltPos m1: 48|12@1- (0.1,0) [0|0] "deg" X
 SG_ UI_columnAndLumbarRecallActive m2: 4|1@1+ (1,0) [0|0] "" X
 SG_ UI_steeringColumnUpDownPos m2: 8|8@1- (12,1284) [0|0] "ticks" X
 SG_ UI_lumbarAPressureHpa m2: 16|16@1+ (1,0) [0|0] "" X
 SG_ UI_lumbarBPressureHpa m2: 32|16@1+ (1,0) [0|0] "" X
 SG_ UI_steeringColumnInOutPos m2: 48|8@1- (12,1284) [0|0] "ticks" X
 SG_ UI_mirrorRecallActive m3: 4|1@1+ (1,0) [0|0] "" X
 SG_ UI_leftMirrorTiltXPosition m3: 8|8@1+ (0.02,0) [0|0] "V" X
 SG_ UI_leftMirrorTiltYPosition m3: 16|8@1+ (0.02,0) [0|0] "V" X
 SG_ UI_rightMirrorTiltXPosition m3: 24|8@1+ (0.02,0) [0|0] "V" X
 SG_ UI_rightMirrorTiltYPosition m3: 32|8@1+ (0.02,0) [0|0] "V" X
 SG_ UI_leftMirrorDipXPosition m4: 8|8@1+ (0.02,0) [0|0] "V" X
 SG_ UI_leftMirrorDipYPosition m4: 16|8@1+ (0.02,0) [0|0] "V" X
 SG_ UI_rightMirrorDipXPosition m4: 24|8@1+ (0.02,0) [0|0] "V" X
 SG_ UI_rightMirrorDipYPosition m4: 32|8@1+ (0.02,0) [0|0] "V" X
 SG_ UI_leftBackrestSwitchUp m5: 4|2@1+ (1,0) [0|0] "" X
 SG_ UI_leftBackrestSwitchDown m5: 6|2@1+ (1,0) [0|0] "" X
 SG_ UI_leftLiftSwitchUp m5: 8|2@1+ (1,0) [0|0] "" X
 SG_ UI_leftLiftSwitchDown m5: 10|2@1+ (1,0) [0|0] "" X
 SG_ UI_rightBackrestSwitchUp m5: 12|2@1+ (1,0) [0|0] "" X
 SG_ UI_rightBackrestSwitchDown m5: 14|2@1+ (1,0) [0|0] "" X
 SG_ UI_rightLiftSwitchUp m5: 16|2@1+ (1,0) [0|0] "" X
 SG_ UI_rightLiftSwitchDown m5: 18|2@1+ (1,0) [0|0] "" X

BO_ 984 UI_elevationStatus: 2 VEH
 SG_ UI_elevation: 0|14@1+ (1,0) [0|0] "m" X

BO_ 1139 UI_VEHNm: 8 VEH
 SG_ UI_nmGoingToSleep: 0|1@1+ (1,0) [0|0] "" X
 SG_ UI_nmKeepAwakeReason: 4|4@1+ (1,0) [0|0] "" X
 SG_ UI_wakeupTime: 32|32@1+ (1,0) [0|0] "" X

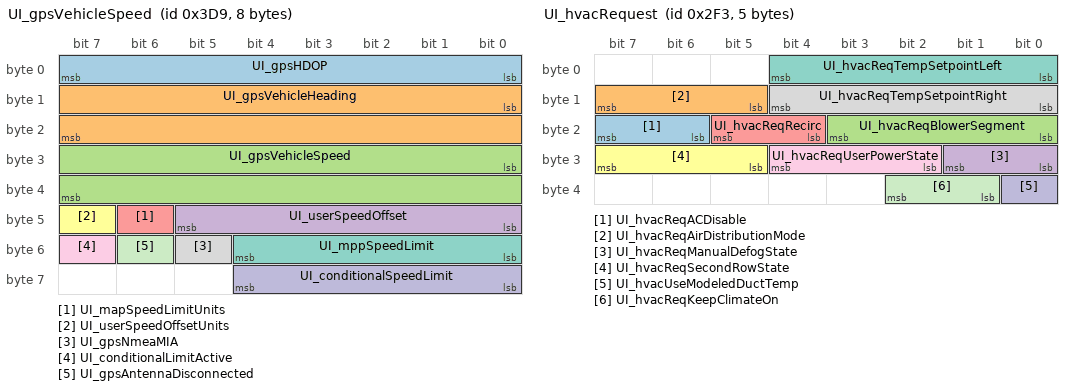
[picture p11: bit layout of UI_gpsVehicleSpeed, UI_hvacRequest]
BO_ 985 UI_gpsVehicleSpeed: 8 CH
 SG_ UI_gpsHDOP: 0|8@1+ (0.1,0) [0|0] "1" X
 SG_ UI_gpsVehicleHeading: 8|16@1+ (0.0078125,0) [0|0] "deg" X
 SG_ UI_gpsVehicleSpeed: 24|16@1+ (0.00390625,0) [0|0] "km/hr" X
 SG_ UI_userSpeedOffset: 40|6@1+ (1,-30) [0|0] "kph/mph" X
 SG_ UI_mapSpeedLimitUnits: 46|1@1+ (1,0) [0|0] "" X
 SG_ UI_userSpeedOffsetUnits: 47|1@1+ (1,0) [0|0] "" X
 SG_ UI_mppSpeedLimit: 48|5@1+ (5,0) [0|0] "kph/mph" X
 SG_ UI_gpsNmeaMIA: 53|1@1+ (1,0) [0|0] "" X
 SG_ UI_conditionalLimitActive : 55|1@1+ (1,0) [0|1] "" X
 SG_ UI_conditionalSpeedLimit : 56|5@1+ (5,0) [0|155] "kph/mph" X
 SG_ UI_gpsAntennaDisconnected : 54|1@1+ (1,0) [0|1] "" X

BO_ 755 UI_hvacRequest: 5 VEH
 SG_ UI_hvacReqACDisable: 22|2@1+ (1,0) [0|0] "" X
 SG_ UI_hvacReqAirDistributionMode: 13|3@1+ (1,0) [0|0] "" X
 SG_ UI_hvacReqBlowerSegment: 16|4@1+ (1,0) [0|0] "" X
 SG_ UI_hvacReqManualDefogState: 24|2@1+ (1,0) [0|0] "" X
 SG_ UI_hvacReqRecirc: 20|2@1+ (1,0) [0|0] "" X
 SG_ UI_hvacReqSecondRowState: 29|3@1+ (1,0) [0|0] "" X
 SG_ UI_hvacReqTempSetpointLeft: 0|5@1+ (0.5,15) [0|0] "degC" X
 SG_ UI_hvacReqTempSetpointRight: 8|5@1+ (0.5,15) [0|0] "degC" X
 SG_ UI_hvacReqUserPowerState: 26|3@1+ (1,0) [0|0] "" X
 SG_ UI_hvacUseModeledDuctTemp: 32|1@1+ (1,0) [0|0] "" X
 SG_ UI_hvacReqKeepClimateOn : 33|2@1+ (1,0) [0|3] "" X

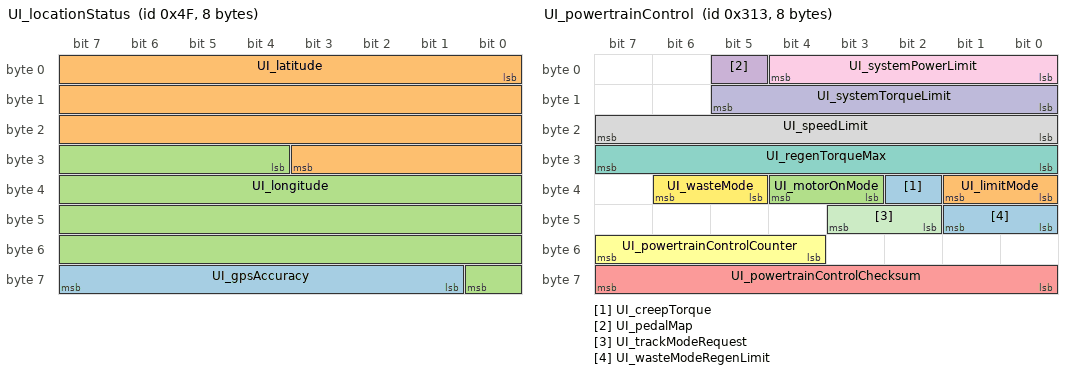
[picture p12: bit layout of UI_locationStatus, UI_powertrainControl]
BO_ 79 UI_locationStatus: 8 CH
 SG_ UI_gpsAccuracy: 57|7@1+ (0.2,0) [0|0] "m" X
 SG_ UI_latitude: 0|28@1- (1e-06,0) [0|0] "deg" X
 SG_ UI_longitude: 28|29@1- (1e-06,0) [0|0] "deg" X

BO_ 1011 UI_odo: 3 CH
 SG_ UI_odometer: 0|24@1+ (0.1,0) [0|0] "km" X

BO_ 787 UI_powertrainControl: 8 VEH
 SG_ UI_creepTorque: 34|1@1+ (1,0) [0|0] "" X
 SG_ UI_limitMode: 32|2@1+ (1,0) [0|0] "" X
 SG_ UI_motorOnMode: 35|2@1+ (1,0) [0|0] "" X
 SG_ UI_pedalMap: 5|1@1+ (1,0) [0|0] "" X
 SG_ UI_powertrainControlChecksum: 56|8@1+ (1,0) [0|0] "" X
 SG_ UI_powertrainControlCounter: 52|4@1+ (1,0) [0|0] "" X
 SG_ UI_regenTorqueMax: 24|8@1+ (0.5,0) [0|0] "%" X
 SG_ UI_speedLimit: 16|8@1+ (1,50) [0|0] "kph" X
 SG_ UI_systemPowerLimit: 0|5@1+ (20,20) [0|0] "kW" X
 SG_ UI_systemTorqueLimit: 8|6@1+ (100,4000) [0|0] "Nm" X
 SG_ UI_trackModeRequest: 42|2@1+ (1,0) [0|0] "" X
 SG_ UI_wasteMode: 37|2@1+ (1,0) [0|0] "" X
 SG_ UI_wasteModeRegenLimit: 40|2@1+ (1,0) [0|0] "" X

BO_ 499 UI_presentPhoneKey1Info: 8 VEH
 SG_ UI_presentPhoneKey1SHA1: 10|54@1+ (1024,0) [0|0] "" X

BO_ 435 UI_presentPhoneKey2Info: 8 VEH
 SG_ UI_presentPhoneKey2SHA1: 10|54@1+ (1024,0) [0|0] "" X

BO_ 371 UI_presentPhoneKey3Info: 8 VEH
 SG_ UI_presentPhoneKey3SHA1: 10|54@1+ (1024,0) [0|0] "" X

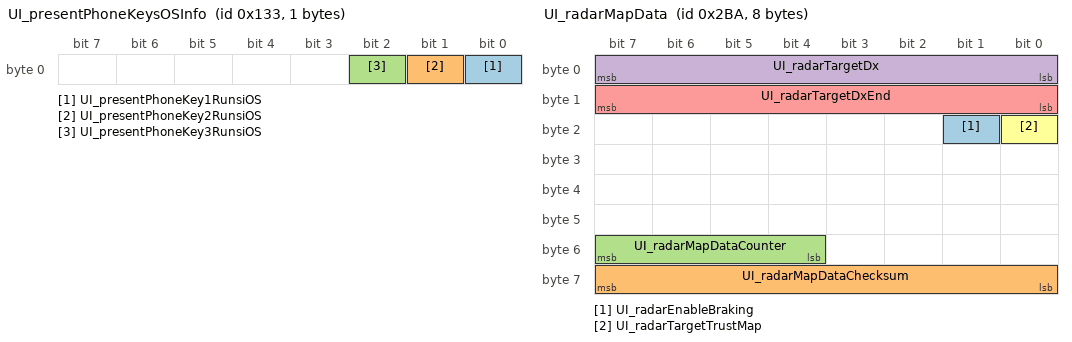
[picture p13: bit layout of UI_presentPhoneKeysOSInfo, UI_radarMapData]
BO_ 307 UI_presentPhoneKeysOSInfo: 1 VEH
 SG_ UI_presentPhoneKey1RunsiOS: 0|1@1+ (1,0) [0|0] "" X
 SG_ UI_presentPhoneKey2RunsiOS: 1|1@1+ (1,0) [0|0] "" X
 SG_ UI_presentPhoneKey3RunsiOS: 2|1@1+ (1,0) [0|0] "" X

BO_ 698 UI_radarMapData: 8 VEH
 SG_ UI_radarEnableBraking: 17|1@1+ (1,0) [0|0] "" X
 SG_ UI_radarMapDataChecksum: 56|8@1+ (1,0) [0|0] "" X
 SG_ UI_radarMapDataCounter: 52|4@1+ (1,0) [0|0] "" X
 SG_ UI_radarTargetDx: 0|8@1+ (1,-95) [0|0] "m" X
 SG_ UI_radarTargetDxEnd: 8|8@1+ (1,0) [0|0] "m" X
 SG_ UI_radarTargetTrustMap: 16|1@1+ (1,0) [0|0] "" X

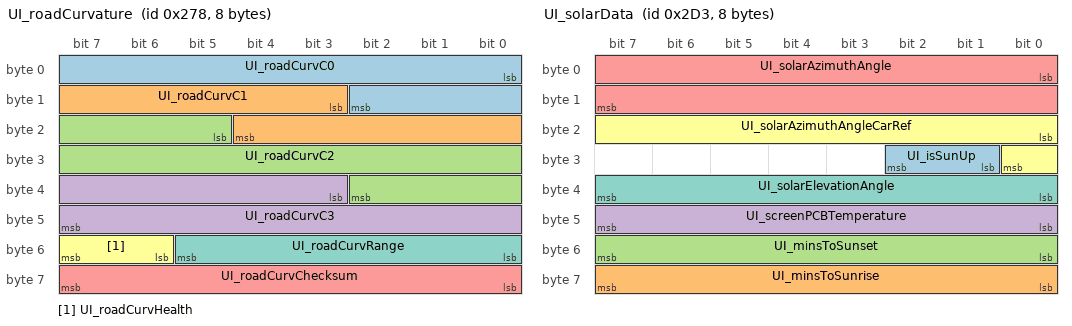
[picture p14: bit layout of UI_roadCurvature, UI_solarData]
BO_ 632 UI_roadCurvature: 8 VEH
 SG_ UI_roadCurvC0: 0|11@1- (0.02,0) [0|0] "m" X
 SG_ UI_roadCurvC1: 11|10@1- (0.00075,0) [0|0] "1" X
 SG_ UI_roadCurvC2: 21|14@1- (7.5e-06,0) [0|0] "1/m" X
 SG_ UI_roadCurvC3: 35|13@1- (3e-08,0) [0|0] "1/m2" X
 SG_ UI_roadCurvChecksum: 56|8@1+ (1,0) [0|0] "" X
 SG_ UI_roadCurvHealth: 54|2@1+ (1,0) [0|0] "" X
 SG_ UI_roadCurvRange: 48|6@1+ (4,0) [0|0] "m" X

BO_ 723 UI_solarData: 8 VEH
 SG_ UI_isSunUp: 25|2@1+ (1,0) [0|0] "" X
 SG_ UI_minsToSunrise: 56|8@1+ (10,0) [0|0] "min" X
 SG_ UI_minsToSunset: 48|8@1+ (10,0) [0|0] "min" X
 SG_ UI_screenPCBTemperature: 40|8@1- (0.5,40) [0|0] "degC" X
 SG_ UI_solarAzimuthAngle: 0|16@1- (1,0) [0|0] "degrees" X
 SG_ UI_solarAzimuthAngleCarRef: 16|9@1- (1,0) [0|0] "degrees" X
 SG_ UI_solarElevationAngle: 32|8@1- (1,0) [0|0] "degrees" X

BO_ 851 UI_status: 8 VehicleBus
 SG_ UI_touchActive : 0|1@1+ (1,0) [0|1] ""  VehicleBus
 SG_ UI_audioActive : 1|1@1+ (1,0) [0|1] ""  VehicleBus
 SG_ UI_bluetoothActive : 2|1@1+ (1,0) [0|1] ""  VehicleBus
 SG_ UI_cellActive : 3|1@1+ (1,0) [0|1] ""  VehicleBus
 SG_ UI_displayReady : 4|1@1+ (1,0) [0|1] ""  VehicleBus
 SG_ UI_displayOn : 5|1@1+ (1,0) [0|1] ""  VehicleBus
 SG_ UI_wifiActive : 6|1@1+ (1,0) [0|1] ""  VehicleBus
 SG_ UI_wifiConnected : 7|1@1+ (1,0) [0|1] ""  VehicleBus
 SG_ UI_systemActive : 8|1@1+ (1,0) [0|1] ""  VehicleBus
 SG_ UI_readyForDrive : 9|1@1+ (1,0) [0|1] ""  VehicleBus
 SG_ UI_cellConnected : 10|1@1+ (1,0) [0|1] ""  VehicleBus
 SG_ UI_vpnActive : 11|1@1+ (1,0) [0|1] ""  VehicleBus
 SG_ UI_autopilotTrial : 12|2@1+ (1,0) [0|3] ""  VehicleBus
 SG_ UI_factoryReset : 14|2@1+ (1,0) [0|3] ""  VehicleBus
 SG_ UI_gpsActive : 16|1@1+ (1,0) [0|1] ""  VehicleBus
 SG_ UI_screenshotActive : 17|1@1+ (1,0) [0|1] ""  VehicleBus
 SG_ UI_radioActive : 18|1@1+ (1,0) [0|1] ""  VehicleBus
 SG_ UI_cellNetworkTechnology : 19|4@1+ (1,0) [0|15] ""  VehicleBus
 SG_ UI_cellReceiverPower : 24|8@1+ (1,-128) [-128|127] "dB"  VehicleBus
 SG_ UI_falseTouchCounter : 32|8@1+ (1,0) [0|255] "1"  VehicleBus
 SG_ UI_developmentCar : 40|1@1+ (1,0) [0|1] ""  VehicleBus
 SG_ UI_cameraActive : 41|1@1+ (1,0) [0|1] ""  VehicleBus
 SG_ UI_cellSignalBars : 42|3@1+ (1,0) [0|7] ""  VehicleBus
 SG_ UI_trailerModeTelltale : 45|2@1+ (1,0) [0|3] ""  VehicleBus
 SG_ UI_pcbTemperature : 48|8@1- (1,40) [-87|167] "degC"  VehicleBus
 SG_ UI_cpuTemperature : 56|8@1- (1,40) [-87|167] "degC"  VehicleBus

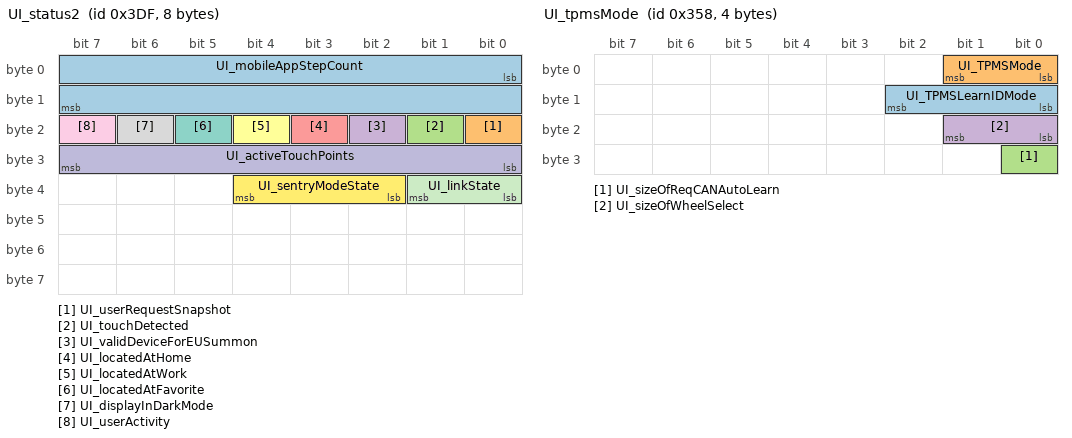
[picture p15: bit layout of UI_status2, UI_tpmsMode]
BO_ 991 UI_status2: 8 VehicleBus
 SG_ UI_mobileAppStepCount : 0|16@1+ (1,0) [0|65535] ""  VehicleBus
 SG_ UI_userRequestSnapshot : 16|1@1+ (1,0) [0|1] ""  VehicleBus
 SG_ UI_touchDetected : 17|1@1+ (1,0) [0|1] ""  VehicleBus
 SG_ UI_validDeviceForEUSummon : 18|1@1+ (1,0) [0|1] ""  VehicleBus
 SG_ UI_locatedAtHome : 19|1@1+ (1,0) [0|1] ""  VehicleBus
 SG_ UI_locatedAtWork : 20|1@1+ (1,0) [0|1] ""  VehicleBus
 SG_ UI_locatedAtFavorite : 21|1@1+ (1,0) [0|1] ""  VehicleBus
 SG_ UI_displayInDarkMode : 22|1@1+ (1,0) [0|1] ""  VehicleBus
 SG_ UI_userActivity : 23|1@1+ (1,0) [0|1] ""  VehicleBus
 SG_ UI_activeTouchPoints : 24|8@1+ (1,0) [0|255] ""  VehicleBus
 SG_ UI_linkState : 32|2@1+ (1,0) [0|3] ""  VehicleBus
 SG_ UI_sentryModeState : 34|3@1+ (1,0) [0|7] ""  VehicleBus

BO_ 1064 UI_telemetryControl: 8 CH
 SG_ UI_TCR_classConstElem: 5|1@1+ (1,0) [0|0] "" X
 SG_ UI_TCR_classMovingFourWheel: 8|1@1+ (1,0) [0|0] "" X
 SG_ UI_TCR_classMovingPed: 6|1@1+ (1,0) [0|0] "" X
 SG_ UI_TCR_classMovingTwoWheel: 7|1@1+ (1,0) [0|0] "" X
 SG_ UI_TCR_classUnknown: 9|1@1+ (1,0) [0|0] "" X
 SG_ UI_TCR_downSampleFactor: 10|4@1+ (1,0) [0|0] "" X
 SG_ UI_TCR_enable: 0|1@1+ (1,0) [0|0] "" X
 SG_ UI_TCR_maxDy: 48|5@1+ (0.5,0) [0|0] "m" X
 SG_ UI_TCR_maxObjects: 56|5@1+ (1,0) [0|0] "" X
 SG_ UI_TCR_maxRoadClass: 61|3@1+ (1,0) [0|0] "" X
 SG_ UI_TCR_minRCS: 40|8@1+ (0.25,-14) [0|0] "dB" X
 SG_ UI_TCR_moveStateIndeterm: 4|1@1+ (1,0) [0|0] "" X
 SG_ UI_TCR_moveStateMoving: 3|1@1+ (1,0) [0|0] "" X
 SG_ UI_TCR_moveStateStanding: 1|1@1+ (1,0) [0|0] "" X
 SG_ UI_TCR_moveStateStopped: 2|1@1+ (1,0) [0|0] "" X
 SG_ UI_TCR_vehSpeed: 32|8@1+ (1,0) [0|0] "" X
 SG_ UI_TCR_wExist: 24|5@1+ (1,0) [0|0] "" X

BO_ 856 UI_tpmsMode: 4 VEH
 SG_ UI_TPMSLearnIDMode: 8|3@1+ (1,0) [0|0] "" X
 SG_ UI_TPMSMode: 0|2@1+ (1,0) [0|0] "" X
 SG_ UI_sizeOfReqCANAutoLearn: 24|1@1+ (1,0) [0|0] "" X
 SG_ UI_sizeOfWheelSelect: 16|2@1+ (1,0) [0|0] "" X

BO_ 952 UI_tpmsRCPsetting: 8 CH
 SG_ UI_setRCPFront: 16|8@1+ (0.025,0) [0|0] "bar" X
 SG_ UI_setRCPRear: 24|8@1+ (0.025,0) [0|0] "bar" X

BO_ 627 UI_vehicleControl: 8 VEH
 SG_ UI_accessoryPowerRequest: 0|1@1+ (1,0) [0|0] "" X
 SG_ UI_alarmEnabled: 20|1@1+ (1,0) [0|0] "" X
 SG_ UI_ambientLightingEnabled: 40|1@1+ (1,0) [0|0] "" X
 SG_ UI_autoFoldMirrorsOn: 52|1@1+ (1,0) [0|0] "" X
 SG_ UI_autoHighBeamEnabled: 41|1@1+ (1,0) [0|0] "" X
 SG_ UI_childDoorLockOn: 16|1@1+ (1,0) [0|0] "" X
 SG_ UI_displayBrightnessLevel: 32|8@1+ (0.5,0) [0|0] "%" X
 SG_ UI_domeLightSwitch: 59|2@1+ (1,0) [0|0] "" X
 SG_ UI_driveStateRequest: 62|1@1+ (1,0) [0|0] "" X
 SG_ UI_frontFogSwitch: 3|1@1+ (1,0) [0|0] "" X
 SG_ UI_frontLeftSeatHeatReq: 42|2@1+ (1,0) [0|0] "" X
 SG_ UI_frontRightSeatHeatReq: 44|2@1+ (1,0) [0|0] "" X
 SG_ UI_frunkRequest: 5|1@1+ (1,0) [0|0] "" X
 SG_ UI_globalUnlockOn: 15|1@1+ (1,0) [0|0] "" X
 SG_ UI_honkHorn: 61|1@1+ (1,0) [0|0] "" X
 SG_ UI_intrusionSensorOn: 21|1@1+ (1,0) [0|0] "" X
 SG_ UI_lightSwitch: 1|2@1+ (1,0) [0|0] "" X
 SG_ UI_lockRequest: 17|3@1+ (1,0) [0|0] "" X
 SG_ UI_mirrorDipOnReverse: 53|1@1+ (1,0) [0|0] "" X
 SG_ UI_mirrorFoldRequest: 24|2@1+ (1,0) [0|0] "" X
 SG_ UI_mirrorHeatRequest: 26|1@1+ (1,0) [0|0] "" X
 SG_ UI_powerOff: 31|1@1+ (1,0) [0|0] "" X
 SG_ UI_rearCenterSeatHeatReq: 48|2@1+ (1,0) [0|0] "" X
 SG_ UI_rearFogSwitch: 23|1@1+ (1,0) [0|0] "" X
 SG_ UI_rearLeftSeatHeatReq: 46|2@1+ (1,0) [0|0] "" X
 SG_ UI_rearRightSeatHeatReq: 50|2@1+ (1,0) [0|0] "" X
 SG_ UI_rearWindowLockout: 63|1@1+ (1,0) [0|0] "" X
 SG_ UI_remoteClosureRequest: 54|2@1+ (1,0) [0|0] "" X
 SG_ UI_remoteStartRequest: 27|3@1+ (1,0) [0|0] "" X
 SG_ UI_seeYouHomeLightingOn: 30|1@1+ (1,0) [0|0] "" X
 SG_ UI_steeringBacklightEnabled: 8|1@1+ (1,0) [0|0] "" X
 SG_ UI_steeringButtonMode: 9|3@1+ (1,0) [0|0] "" X
 SG_ UI_stop12vSupport: 22|1@1+ (1,0) [0|0] "" X
 SG_ UI_summonActive: 4|1@1+ (1,0) [0|0] "" X
 SG_ UI_unlockOnPark: 14|1@1+ (1,0) [0|0] "" X
 SG_ UI_walkAwayLock: 13|1@1+ (1,0) [0|0] "" X
 SG_ UI_walkUpUnlock: 12|1@1+ (1,0) [0|0] "" X
 SG_ UI_wiperMode: 6|2@1+ (1,0) [0|0] "" X
 SG_ UI_wiperRequest: 56|3@1+ (1,0) [0|0] "" X

BO_ 947 UI_vehicleControl2: 2 VEH
 SG_ UI_PINToDriveEnabled : 6|1@1+ (1,0) [0|1] "" X
 SG_ UI_PINToDrivePassed : 7|1@1+ (1,0) [0|1] "" X
 SG_ UI_UMCUpdateInhibit : 2|1@1+ (1,0) [0|1] "" X
 SG_ UI_VCLEFTFeature1 : 15|1@1+ (1,0) [0|1] "" X
 SG_ UI_VCSECFeature1 : 14|1@1+ (1,0) [0|1] "" X
 SG_ UI_WCUpdateInhibit : 3|1@1+ (1,0) [0|1] "" X
 SG_ UI_alarmTriggerRequest : 13|1@1+ (1,0) [0|1] "" X
 SG_ UI_autoRollWindowsOnLockEnable : 29|1@1+ (1,0) [0|1] "" X
 SG_ UI_autopilotPowerStateRequest : 25|2@1+ (1,0) [0|2] "" X
 SG_ UI_batteryPreconditioningRequest : 23|1@1+ (1,0) [0|1] "" X
 SG_ UI_coastDownMode : 24|1@1+ (1,0) [0|1] "" X
 SG_ UI_efuseMXResistanceEstArmed : 30|1@1+ (1,0) [0|1] "" X
 SG_ UI_freeRollModeRequest : 19|1@1+ (1,0) [0|1] "" X
 SG_ UI_gloveboxRequest : 0|1@1+ (1,0) [0|1] "" X
 SG_ UI_lightSwitch : 9|3@1+ (1,0) [0|4] "" X
 SG_ UI_locksPanelActive : 5|1@1+ (1,0) [0|1] "" X
 SG_ UI_readyToAddKey : 12|1@1+ (1,0) [0|1] "" X
 SG_ UI_shorted12VCellTestMode : 27|2@1+ (1,0) [0|2] "" X
 SG_ UI_soundHornOnLock : 4|1@1+ (1,0) [0|1] "" X
 SG_ UI_summonState : 16|2@1+ (1,0) [0|3] "" X
 SG_ UI_trunkRequest : 1|1@1+ (1,0) [0|1] "" X
 SG_ UI_userPresent : 18|1@1+ (1,0) [0|1] "" X
 SG_ UI_windowRequest : 20|3@1+ (1,0) [0|4] "" X

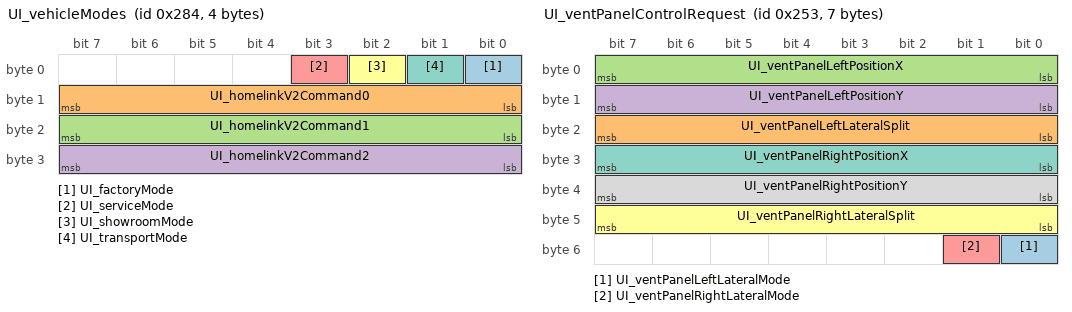
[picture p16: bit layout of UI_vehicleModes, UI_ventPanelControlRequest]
BO_ 644 UI_vehicleModes: 4 VEH
 SG_ UI_factoryMode: 0|1@1+ (1,0) [0|0] "" X
 SG_ UI_homelinkV2Command0: 8|8@1+ (1,0) [0|0] "" X
 SG_ UI_homelinkV2Command1: 16|8@1+ (1,0) [0|0] "" X
 SG_ UI_homelinkV2Command2: 24|8@1+ (1,0) [0|0] "" X
 SG_ UI_serviceMode: 3|1@1+ (1,0) [0|0] "" X
 SG_ UI_showroomMode: 2|1@1+ (1,0) [0|0] "" X
 SG_ UI_transportMode: 1|1@1+ (1,0) [0|0] "" X

BO_ 595 UI_ventPanelControlRequest: 7 VEH
 SG_ UI_ventPanelLeftLateralMode: 48|1@1+ (1,0) [0|0] "" X
 SG_ UI_ventPanelLeftLateralSplit: 16|8@1+ (0.5,0) [0|0] "%" X
 SG_ UI_ventPanelLeftPositionX: 0|8@1+ (0.5,0) [0|0] "%" X
 SG_ UI_ventPanelLeftPositionY: 8|8@1+ (0.5,0) [0|0] "%" X
 SG_ UI_ventPanelRightLateralMode: 49|1@1+ (1,0) [0|0] "" X
 SG_ UI_ventPanelRightLateralSplit: 40|8@1+ (0.5,0) [0|0] "%" X
 SG_ UI_ventPanelRightPositionX: 24|8@1+ (0.5,0) [0|0] "%" X
 SG_ UI_ventPanelRightPositionY: 32|8@1+ (0.5,0) [0|0] "%" X

BO_ 824 UMC_alertMatrix1: 8 VEH
 SG_ UMC_a001_gndMonIntrptLineSide: 0|1@1+ (1,0) [0|0] "" X
 SG_ UMC_a002_GFCITripped: 1|1@1+ (1,0) [0|0] "" X
 SG_ UMC_a003_GFCISelfTestFault: 2|1@1+ (1,0) [0|0] "" X
 SG_ UMC_a004_inputOverVoltage: 3|1@1+ (1,0) [0|0] "" X
 SG_ UMC_a005_inputUnderVoltage: 4|1@1+ (1,0) [0|0] "" X
 SG_ UMC_a006_contactorWelded: 5|1@1+ (1,0) [0|0] "" X
 SG_ UMC_a007_pcbaOT: 6|1@1+ (1,0) [0|0] "" X
 SG_ UMC_a008_wallPlugOT: 7|1@1+ (1,0) [0|0] "" X
 SG_ UMC_a009_vehConnOT: 8|1@1+ (1,0) [0|0] "" X
 SG_ UMC_a010_inputOT: 9|1@1+ (1,0) [0|0] "" X
 SG_ UMC_a011_proxDisconnected: 10|1@1+ (1,0) [0|0] "" X
 SG_ UMC_a012_pilotFault: 11|1@1+ (1,0) [0|0] "" X
 SG_ UMC_a013_SA_Temperature: 12|1@1+ (1,0) [0|0] "" X
 SG_ UMC_a014_SA_Genealogy: 13|1@1+ (1,0) [0|0] "" X
 SG_ UMC_a015_SA_Connection: 14|1@1+ (1,0) [0|0] "" X
 SG_ UMC_a016_pcbaOTFoldback: 15|1@1+ (1,0) [0|0] "" X
 SG_ UMC_a017_wallPlugOTFoldback: 16|1@1+ (1,0) [0|0] "" X
 SG_ UMC_a018_vehConnOTFoldback: 17|1@1+ (1,0) [0|0] "" X
 SG_ UMC_a019_inputOTFoldback: 18|1@1+ (1,0) [0|0] "" X
 SG_ UMC_a020_applicationCRC: 19|1@1+ (1,0) [0|0] "" X
 SG_ UMC_a021_dataBus: 20|1@1+ (1,0) [0|0] "" X
 SG_ UMC_a022_criticalRAM: 21|1@1+ (1,0) [0|0] "" X
 SG_ UMC_a023_adcSelfTest: 22|1@1+ (1,0) [0|0] "" X

BO_ 609 VCFRONT_12VBatteryStatus: 8 VEH
 SG_ VCFRONT_12VBatteryIndex M : 0|2@1+ (1,0) [0|4] ""  Receiver
 SG_ VCFRONT_IBSCurrent m0 : 16|12@1- (0.005,0) [-163.84|163.835] "A"  Receiver
 SG_ VCFRONT_IBSCurrentRaw m1 : 16|16@1- (0.005,0) [-163.84|163.835] "A"  Receiver
 SG_ VCFRONT_IBSVoltage m1 : 32|12@1+ (0.005443676098,0) [0|22.29185362131] "V"  Receiver
 SG_ VCFRONT_IBSAmpHours m2 : 2|14@1- (0.01,0) [-81.92|81.91] "Ah"  Receiver
 SG_ VCFRONT_IBSTemperature m2 : 8|16@0- (0.1,0) [-327.68|327.66] "degC"  Receiver

BO_ 545 VCFRONT_LVPowerState: 8 VEH
 SG_ VCFRONT_LVPowerStateChecksum: 56|8@1+ (1,0) [0|0] "" X
 SG_ VCFRONT_LVPowerStateCounter: 52|4@1+ (1,0) [0|0] "" X
 SG_ VCFRONT_LVPowerStateIndex M: 0|5@1+ (1,0) [0|0] "" X
 SG_ VCFRONT_vehiclePowerState: 5|2@1+ (1,0) [0|0] "" X
 SG_ VCFRONT_parkLVState m0: 8|2@1+ (1,0) [0|0] "" X
 SG_ VCFRONT_espLVState m0: 10|2@1+ (1,0) [0|0] "" X
 SG_ VCFRONT_radcLVState m0: 12|2@1+ (1,0) [0|0] "" X
 SG_ VCFRONT_hvacCompLVState m0: 14|2@1+ (1,0) [0|0] "" X
 SG_ VCFRONT_ptcLVRequest m0: 16|2@1+ (1,0) [0|0] "" X
 SG_ VCFRONT_sccmLVRequest m0: 18|2@1+ (1,0) [0|0] "" X
 SG_ VCFRONT_tpmsLVRequest m0: 20|2@1+ (1,0) [0|0] "" X
 SG_ VCFRONT_rcmLVRequest m0: 22|2@1+ (1,0) [0|0] "" X
 SG_ VCFRONT_iBoosterLVState m0: 24|2@1+ (1,0) [0|0] "" X
 SG_ VCFRONT_tunerLVRequest m0: 26|2@1+ (1,0) [0|0] "" X
 SG_ VCFRONT_amplifierLVRequest m0: 28|2@1+ (1,0) [0|0] "" X
 SG_ VCFRONT_das1HighCurrentLVState m0: 30|2@1+ (1,0) [0|0] "" X
 SG_ VCFRONT_das2HighCurrentLVState m0: 32|2@1+ (1,0) [0|0] "" X
 SG_ VCFRONT_diLVRequest m0: 34|2@1+ (1,0) [0|0] "" X
 SG_ VCFRONT_disLVState m0: 36|2@1+ (1,0) [0|0] "" X
 SG_ VCFRONT_oilPumpFrontLVState m0: 38|2@1+ (1,0) [0|0] "" X
 SG_ VCFRONT_oilPumpRearLVRequest m0: 40|2@1+ (1,0) [0|0] "" X
 SG_ VCFRONT_ocsLVRequest m0: 42|2@1+ (1,0) [0|0] "" X
 SG_ VCFRONT_vcleftHiCurrentLVState m0: 44|2@1+ (1,0) [0|0] "" X
 SG_ VCFRONT_vcrightHiCurrentLVState m0: 46|2@1+ (1,0) [0|0] "" X
 SG_ VCFRONT_uiHiCurrentLVState m0: 48|2@1+ (1,0) [0|0] "" X
 SG_ VCFRONT_uiAudioLVState m0: 50|2@1+ (1,0) [0|0] "" X
 SG_ VCFRONT_cpLVRequest m1: 8|2@1+ (1,0) [0|0] "" X
 SG_ VCFRONT_epasLVState m1: 10|2@1+ (1,0) [0|0] "" X
 SG_ VCFRONT_hvcLVRequest m1: 12|2@1+ (1,0) [0|0] "" X
 SG_ VCFRONT_tasLVState m1: 14|2@1+ (1,0) [0|0] "" X
 SG_ VCFRONT_pcsLVState m1: 16|2@1+ (1,0) [0|0] "" X

BO_ 832 VCFRONT_alertMatrix: 8 VEH
 SG_ VCFRONT_matrixIndex M: 0|4@1+ (1,0) [0|0] "" X
 SG_ VCFRONT_a001_WatchdogReset m0: 4|1@1+ (1,0) [0|0] "" X
 SG_ VCFRONT_a002_PowerLossReset m0: 5|1@1+ (1,0) [0|0] "" X
 SG_ VCFRONT_a003_SWAssertion m0: 6|1@1+ (1,0) [0|0] "" X
 SG_ VCFRONT_a010_ExtSupplyVoltError m0: 13|1@1+ (1,0) [0|0] "" X
 SG_ VCFRONT_a012_CPUReset m0: 15|1@1+ (1,0) [0|0] "" X
 SG_ VCFRONT_a013_AlertManagerFault m0: 16|1@1+ (1,0) [0|0] "" X
 SG_ VCFRONT_a015_NVMMAlert m0: 18|1@1+ (1,0) [0|0] "" X
 SG_ VCFRONT_a021_TaskSchedulerError m0: 24|1@1+ (1,0) [0|0] "" X
 SG_ VCFRONT_a022_TaskInitError m0: 25|1@1+ (1,0) [0|0] "" X
 SG_ VCFRONT_a031_UDSActive m0: 34|1@1+ (1,0) [0|0] "" X
 SG_ VCFRONT_a041_HighCPULoad m0: 44|1@1+ (1,0) [0|0] "" X
 SG_ VCFRONT_a042_HighStackUsage m0: 45|1@1+ (1,0) [0|0] "" X
 SG_ VCFRONT_a043_Task1msError m0: 46|1@1+ (1,0) [0|0] "" X
 SG_ VCFRONT_a044_Task10msError m0: 47|1@1+ (1,0) [0|0] "" X
 SG_ VCFRONT_a045_Task100msError m0: 48|1@1+ (1,0) [0|0] "" X
 SG_ VCFRONT_a046_Task1000msError m0: 49|1@1+ (1,0) [0|0] "" X
 SG_ VCFRONT_a059_inputResistanceHigh m0: 62|1@1+ (1,0) [0|0] "" X
 SG_ VCFRONT_a060_engineeringBuild m0: 63|1@1+ (1,0) [0|0] "" X
 SG_ VCFRONT_a061_XCPConnected m1: 4|1@1+ (1,0) [0|0] "" X
 SG_ VCFRONT_a062_XCPWasConnected m1: 5|1@1+ (1,0) [0|0] "" X
 SG_ VCFRONT_a063_SwitchFault m1: 6|1@1+ (1,0) [0|0] "" X
 SG_ VCFRONT_a064_busSleepReqTimeout m1: 7|1@1+ (1,0) [0|0] "" X
 SG_ VCFRONT_a097_CMP_MIA m1: 40|1@1+ (1,0) [0|0] "" X
 SG_ VCFRONT_a098_DI_THERMAL_MIA m1: 41|1@1+ (1,0) [0|0] "" X
 SG_ VCFRONT_a099_PARK_MIA m1: 42|1@1+ (1,0) [0|0] "" X
 SG_ VCFRONT_a100_CANbus_MIA m1: 43|1@1+ (1,0) [0|0] "" X
 SG_ VCFRONT_a101_PM_MIA m1: 44|1@1+ (1,0) [0|0] "" X
 SG_ VCFRONT_a102_PTC_MIA m1: 45|1@1+ (1,0) [0|0] "" X
 SG_ VCFRONT_a103_CP_MIA m1: 46|1@1+ (1,0) [0|0] "" X
 SG_ VCFRONT_a104_DAS_MIA m1: 47|1@1+ (1,0) [0|0] "" X
 SG_ VCFRONT_a105_TAS_MIA m1: 48|1@1+ (1,0) [0|0] "" X
 SG_ VCFRONT_a106_PCS_MIA m1: 49|1@1+ (1,0) [0|0] "" X
 SG_ VCFRONT_a107_BMS_MIA m1: 50|1@1+ (1,0) [0|0] "" X
 SG_ VCFRONT_a108_DIS_MIA m1: 51|1@1+ (1,0) [0|0] "" X
 SG_ VCFRONT_a109_RCM_MIA m1: 52|1@1+ (1,0) [0|0] "" X
 SG_ VCFRONT_a110_GTW_MIA m1: 53|1@1+ (1,0) [0|0] "" X
 SG_ VCFRONT_a111_EPBR_MIA m1: 54|1@1+ (1,0) [0|0] "" X
 SG_ VCFRONT_a112_EPBL_MIA m1: 55|1@1+ (1,0) [0|0] "" X
 SG_ VCFRONT_a113_UI_MIA m1: 56|1@1+ (1,0) [0|0] "" X
 SG_ VCFRONT_a114_ESP_MIA m1: 57|1@1+ (1,0) [0|0] "" X
 SG_ VCFRONT_a115_VCSEC_MIA m1: 58|1@1+ (1,0) [0|0] "" X
 SG_ VCFRONT_a116_VCRIGHT_MIA m1: 59|1@1+ (1,0) [0|0] "" X
 SG_ VCFRONT_a117_VCLEFT_MIA m1: 60|1@1+ (1,0) [0|0] "" X
 SG_ VCFRONT_a118_VCFRONT_MIA m1: 61|1@1+ (1,0) [0|0] "" X
 SG_ VCFRONT_a119_SCCM_MIA m1: 62|1@1+ (1,0) [0|0] "" X
 SG_ VCFRONT_a120_DI_DRIVE_MIA m1: 63|1@1+ (1,0) [0|0] "" X
 SG_ VCFRONT_a121_pumpBatICLatchFault m2: 4|1@1+ (1,0) [0|0] "" X
 SG_ VCFRONT_a122_pumpBatICWarning m2: 5|1@1+ (1,0) [0|0] "" X
 SG_ VCFRONT_a123_pumpPtICLatchFault m2: 6|1@1+ (1,0) [0|0] "" X
 SG_ VCFRONT_a124_pumpPtICWarning m2: 7|1@1+ (1,0) [0|0] "" X
 SG_ VCFRONT_a125_thmlFanICLatchFault m2: 8|1@1+ (1,0) [0|0] "" X
 SG_ VCFRONT_a126_thmlFanICWarning m2: 9|1@1+ (1,0) [0|0] "" X
 SG_ VCFRONT_a127_vcleftEFuseTrip m2: 10|1@1+ (1,0) [0|0] "" X
 SG_ VCFRONT_a128_vcrightEFuseTrip m2: 11|1@1+ (1,0) [0|0] "" X
 SG_ VCFRONT_a129_pcsEFuseTrip m2: 12|1@1+ (1,0) [0|0] "" X
 SG_ VCFRONT_a130_epas3pEFuseTrip m2: 13|1@1+ (1,0) [0|0] "" X
 SG_ VCFRONT_a131_epas3sEFuseTrip m2: 14|1@1+ (1,0) [0|0] "" X
 SG_ VCFRONT_a132_iBoosterEFuseTrip m2: 15|1@1+ (1,0) [0|0] "" X
 SG_ VCFRONT_a133_espEFuseTrip m2: 16|1@1+ (1,0) [0|0] "" X
 SG_ VCFRONT_a134_fusedHighEFuseTrip m2: 17|1@1+ (1,0) [0|0] "" X
 SG_ VCFRONT_a135_coolantLevelLow m2: 18|1@1+ (1,0) [0|0] "" X
 SG_ VCFRONT_a136_refrigDischTempSns m2: 19|1@1+ (1,0) [0|0] "" X
 SG_ VCFRONT_a137_refrigDischPresSns m2: 20|1@1+ (1,0) [0|0] "" X
 SG_ VCFRONT_a138_refrigSuctTempSns m2: 21|1@1+ (1,0) [0|0] "" X
 SG_ VCFRONT_a139_refrigSuctPresSns m2: 22|1@1+ (1,0) [0|0] "" X
 SG_ VCFRONT_a140_coolantTempPtSns m2: 23|1@1+ (1,0) [0|0] "" X
 SG_ VCFRONT_a141_coolantTempBatSns m2: 24|1@1+ (1,0) [0|0] "" X
 SG_ VCFRONT_a142_exvMotorFault m2: 25|1@1+ (1,0) [0|0] "" X
 SG_ VCFRONT_a143_pumpBatICTransFault m2: 26|1@1+ (1,0) [0|0] "" X
 SG_ VCFRONT_a144_pumpPtICTransFault m2: 27|1@1+ (1,0) [0|0] "" X
 SG_ VCFRONT_a145_thmlFanICTransFault m2: 28|1@1+ (1,0) [0|0] "" X
 SG_ VCFRONT_a146_pumpBatSoftStall m2: 29|1@1+ (1,0) [0|0] "" X
 SG_ VCFRONT_a147_pumpPtSoftStall m2: 30|1@1+ (1,0) [0|0] "" X
 SG_ VCFRONT_a148_thmlFanSoftStall m2: 31|1@1+ (1,0) [0|0] "" X
 SG_ VCFRONT_a149_BLEFrontPowerCycled m2: 32|1@1+ (1,0) [0|0] "" X
 SG_ VCFRONT_a150_pumpBatLowRPMCBang m2: 33|1@1+ (1,0) [0|0] "" X
 SG_ VCFRONT_a151_pumpPtLowRPMCBang m2: 34|1@1+ (1,0) [0|0] "" X
 SG_ VCFRONT_a152_thmlFanLowRPMCBang m2: 35|1@1+ (1,0) [0|0] "" X
 SG_ VCFRONT_a156_louverBlockage m2: 39|1@1+ (1,0) [0|0] "" X
 SG_ VCFRONT_a157_louverBreakage m2: 40|1@1+ (1,0) [0|0] "" X
 SG_ VCFRONT_a158_louverDisconnected m2: 41|1@1+ (1,0) [0|0] "" X
 SG_ VCFRONT_a159_fiveWayValveFault m2: 42|1@1+ (1,0) [0|0] "" X
 SG_ VCFRONT_a160_compressorInhibited m2: 43|1@1+ (1,0) [0|0] "" X
 SG_ VCFRONT_a161_compressorSelfFault m2: 44|1@1+ (1,0) [0|0] "" X
 SG_ VCFRONT_a164_eFuseLckoutMissing m2: 47|1@1+ (1,0) [0|0] "" X
 SG_ VCFRONT_a165_unxpctdEFuseLckout m2: 48|1@1+ (1,0) [0|0] "" X
 SG_ VCFRONT_a166_rightHCMMIA m2: 49|1@1+ (1,0) [0|0] "" X
 SG_ VCFRONT_a167_leftHCMMIA m2: 50|1@1+ (1,0) [0|0] "" X
 SG_ VCFRONT_a168_hcmShortToVBAT m2: 51|1@1+ (1,0) [0|0] "" X
 SG_ VCFRONT_a169_hcmPhaseEnableFail m2: 52|1@1+ (1,0) [0|0] "" X
 SG_ VCFRONT_a170_hcmUnderVoltage m2: 53|1@1+ (1,0) [0|0] "" X
 SG_ VCFRONT_a171_driveBlckdByMsmtch m2: 54|1@1+ (1,0) [0|0] "" X
 SG_ VCFRONT_a172_wsteHtBlckdByMsmtch m2: 55|1@1+ (1,0) [0|0] "" X
 SG_ VCFRONT_a173_HVBlckdByMsmtch m2: 56|1@1+ (1,0) [0|0] "" X
 SG_ VCFRONT_a174_driveNotAuthed m2: 57|1@1+ (1,0) [0|0] "" X
 SG_ VCFRONT_a175_ambientTempSns m2: 58|1@1+ (1,0) [0|0] "" X
 SG_ VCFRONT_a176_vehicleInSelfTest m2: 59|1@1+ (1,0) [0|0] "" X
 SG_ VCFRONT_a177_mcuAudioEFuseFault m2: 60|1@1+ (1,0) [0|0] "" X
 SG_ VCFRONT_a179_highLVAmpsIntoPCS m2: 62|1@1+ (1,0) [0|0] "" X
 SG_ VCFRONT_a180_12VNotSupported m2: 63|1@1+ (1,0) [0|0] "" X
 SG_ VCFRONT_a182_replace12VBattery m3: 5|1@1+ (1,0) [0|0] "" X
 SG_ VCFRONT_a183_low12VCapacity m3: 6|1@1+ (1,0) [0|0] "" X
 SG_ VCFRONT_a185_washerFluidLow m3: 8|1@1+ (1,0) [0|0] "" X
 SG_ VCFRONT_a186_noDriveChgCableCon m3: 9|1@1+ (1,0) [0|0] "" X
 SG_ VCFRONT_a187_busesNotSleeping m3: 10|1@1+ (1,0) [0|0] "" X
 SG_ VCFRONT_a188_sleepFailed m3: 11|1@1+ (1,0) [0|0] "" X
 SG_ VCFRONT_a189_IBSMIA m3: 12|1@1+ (1,0) [0|0] "" X
 SG_ VCFRONT_a190_DCDCNotOperational m3: 13|1@1+ (1,0) [0|0] "" X
 SG_ VCFRONT_a191_exitDriveLow12V m3: 14|1@1+ (1,0) [0|0] "" X
 SG_ VCFRONT_a192_criticalLoadShed m3: 15|1@1+ (1,0) [0|0] "" X
 SG_ VCFRONT_a193_mcuAudioRetry m3: 16|1@1+ (1,0) [0|0] "" X
 SG_ VCFRONT_a194_iBoosterRetry m3: 17|1@1+ (1,0) [0|0] "" X
 SG_ VCFRONT_a195_drveBlckdVltgeTooHgh m3: 18|1@1+ (1,0) [0|0] "" X
 SG_ VCFRONT_a196_discnctd12VBattery m3: 19|1@1+ (1,0) [0|0] "" X
 SG_ VCFRONT_a198_PRVCANOverterminate m3: 21|1@1+ (1,0) [0|0] "" X
 SG_ VCFRONT_a199_PRVCANUndertrminate m3: 22|1@1+ (1,0) [0|0] "" X
 SG_ VCFRONT_a200_vcleftSelfTestFail m3: 23|1@1+ (1,0) [0|0] "" X
 SG_ VCFRONT_a201_vcrightSelfTestFail m3: 24|1@1+ (1,0) [0|0] "" X
 SG_ VCFRONT_a202_pcsSelfTestFail m3: 25|1@1+ (1,0) [0|0] "" X
 SG_ VCFRONT_a203_epas3pSelfTestFail m3: 26|1@1+ (1,0) [0|0] "" X
 SG_ VCFRONT_a204_epas3sSelfTestFail m3: 27|1@1+ (1,0) [0|0] "" X
 SG_ VCFRONT_a205_iBoosterSelfTestFail m3: 28|1@1+ (1,0) [0|0] "" X
 SG_ VCFRONT_a206_espSelfTestFail m3: 29|1@1+ (1,0) [0|0] "" X
 SG_ VCFRONT_a207_vbatFusdSelfTestFail m3: 30|1@1+ (1,0) [0|0] "" X
 SG_ VCFRONT_a208_brakeFluidLow m3: 31|1@1+ (1,0) [0|0] "" X
 SG_ VCFRONT_a209_brakeFluidSNA m3: 32|1@1+ (1,0) [0|0] "" X
 SG_ VCFRONT_a210_fiveWayValveCalib m3: 33|1@1+ (1,0) [0|0] "" X
 SG_ VCFRONT_a211_I2CFault m3: 34|1@1+ (1,0) [0|0] "" X
 SG_ VCFRONT_a212_IBSOverTemp m3: 35|1@1+ (1,0) [0|0] "" X
 SG_ VCFRONT_a213_12VOvercharge m3: 36|1@1+ (1,0) [0|0] "" X
 SG_ VCFRONT_a214_airCompUnderCurrent m3: 37|1@1+ (1,0) [0|0] "" X
 SG_ VCFRONT_a215_airCompDriverFault m3: 38|1@1+ (1,0) [0|0] "" X
 SG_ VCFRONT_a219_12VVoltFloorRchd m3: 42|1@1+ (1,0) [0|0] "" X
 SG_ VCFRONT_a220_reverseBatteryFault m3: 43|1@1+ (1,0) [0|0] "" X
 SG_ VCFRONT_a221_leftTurnLightFault m3: 44|1@1+ (1,0) [0|0] "" X
 SG_ VCFRONT_a222_rightTurnLightFault m3: 45|1@1+ (1,0) [0|0] "" X
 SG_ VCFRONT_a223_12VTempSensDiscnect m3: 46|1@1+ (1,0) [0|0] "" X
 SG_ VCFRONT_a224_revBatChrgPmpFault m3: 47|1@1+ (1,0) [0|0] "" X
 SG_ VCFRONT_a225_driveBlckdByShowroom m3: 48|1@1+ (1,0) [0|0] "" X
 SG_ VCFRONT_a226_railAPoweredForFrunk m3: 49|1@1+ (1,0) [0|0] "" X
 SG_ VCFRONT_a228_pumpBatFbkSanity m3: 51|1@1+ (1,0) [0|0] "" X
 SG_ VCFRONT_a229_pumpPtFbkSanity m3: 52|1@1+ (1,0) [0|0] "" X
 SG_ VCFRONT_a230_thmlFanFbkSanity m3: 53|1@1+ (1,0) [0|0] "" X
 SG_ VCFRONT_a231_12VTempSensShort m3: 54|1@1+ (1,0) [0|0] "" X
 SG_ VCFRONT_a233_autopilot1EFuseFault m3: 56|1@1+ (1,0) [0|0] "" X
 SG_ VCFRONT_a234_autopilot2EFuseFault m3: 57|1@1+ (1,0) [0|0] "" X
 SG_ VCFRONT_a235_ptTempSnsIrrational m3: 58|1@1+ (1,0) [0|0] "" X
 SG_ VCFRONT_a236_batTempSnsIrrational m3: 59|1@1+ (1,0) [0|0] "" X
 SG_ VCFRONT_a237_pumpBatChipComms m3: 60|1@1+ (1,0) [0|0] "" X
 SG_ VCFRONT_a238_pumpPtChipComms m3: 61|1@1+ (1,0) [0|0] "" X
 SG_ VCFRONT_a239_thmlFanChipComms m3: 62|1@1+ (1,0) [0|0] "" X
 SG_ VCFRONT_a243_12VOverchargeInstc m4: 6|1@1+ (1,0) [0|0] "" X
 SG_ VCFRONT_a244_sleepBypassFault m4: 7|1@1+ (1,0) [0|0] "" X
 SG_ VCFRONT_a245_pump1EFuseFault m4: 8|1@1+ (1,0) [0|0] "" X
 SG_ VCFRONT_a246_pump2EFuseFault m4: 9|1@1+ (1,0) [0|0] "" X
 SG_ VCFRONT_a247_evapSolenoidFault m4: 10|1@1+ (1,0) [0|0] "" X
 SG_ VCFRONT_a248_voltageOutOfSpec m4: 11|1@1+ (1,0) [0|0] "" X
 SG_ VCFRONT_a249_fiveWayValveBadMode m4: 12|1@1+ (1,0) [0|0] "" X
 SG_ VCFRONT_a250_headlampsNotAimed m4: 13|1@1+ (1,0) [0|0] "" X
 SG_ VCFRONT_a251_UIWakeupTrigger m4: 14|1@1+ (1,0) [0|0] "" X
 SG_ VCFRONT_a252_frontControllerWakeup m4: 15|1@1+ (1,0) [0|0] "" X
 SG_ VCFRONT_a253_maxChrgeSssionTmeout m4: 16|1@1+ (1,0) [0|0] "" X
 SG_ VCFRONT_a254_pumpBatStopped m4: 17|1@1+ (1,0) [0|0] "" X
 SG_ VCFRONT_a255_pumpPtStopped m4: 18|1@1+ (1,0) [0|0] "" X
 SG_ VCFRONT_a256_compTornShaftSeal m4: 19|1@1+ (1,0) [0|0] "" X
 SG_ VCFRONT_a257_portExpanderVOR m4: 20|1@1+ (1,0) [0|0] "" X
 SG_ VCFRONT_a258_resistanceEstimationRun m4: 21|1@1+ (1,0) [0|0] "" X
 SG_ VCFRONT_a259_12vVoltageDropOnHighLoadCurrent m4: 22|1@1+ (1,0) [0|0] "" X

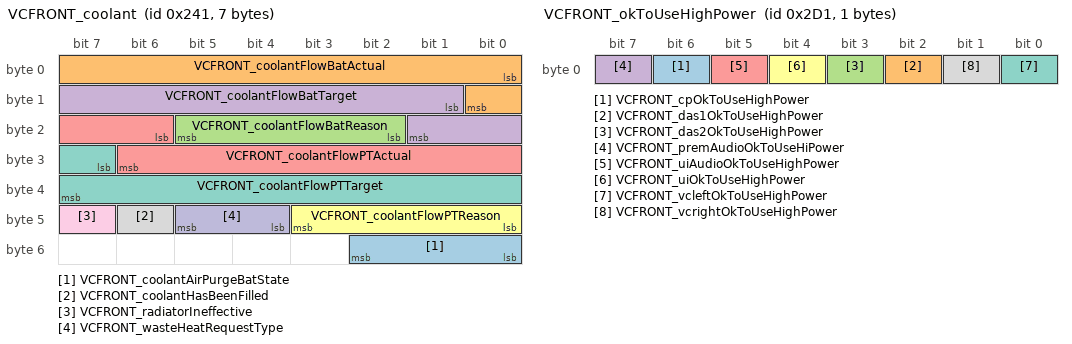
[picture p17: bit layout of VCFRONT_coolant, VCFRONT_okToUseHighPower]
BO_ 577 VCFRONT_coolant: 7 VEH
 SG_ VCFRONT_coolantAirPurgeBatState: 48|3@1+ (1,0) [0|0] "" X
 SG_ VCFRONT_coolantFlowBatActual: 0|9@1+ (0.1,0) [0|0] "LPM" X
 SG_ VCFRONT_coolantFlowBatReason: 18|4@1+ (1,0) [0|0] "" X
 SG_ VCFRONT_coolantFlowBatTarget: 9|9@1+ (0.1,0) [0|0] "LPM" X
 SG_ VCFRONT_coolantFlowPTActual: 22|9@1+ (0.1,0) [0|0] "LPM" X
 SG_ VCFRONT_coolantFlowPTReason: 40|4@1+ (1,0) [0|0] "" X
 SG_ VCFRONT_coolantFlowPTTarget: 31|9@1+ (0.1,0) [0|0] "LPM" X
 SG_ VCFRONT_coolantHasBeenFilled: 46|1@1+ (1,0) [0|0] "" X
 SG_ VCFRONT_radiatorIneffective: 47|1@1+ (1,0) [0|0] "" X
 SG_ VCFRONT_wasteHeatRequestType: 44|2@1+ (1,0) [0|0] "" X

BO_ 753 VCFRONT_eFuseDebugStatus: 8 VEH
 SG_ VCFRONT_eFuseDebugStatusIndex M: 0|5@1+ (1,0) [0|0] "" X
 SG_ VCFRONT_rightControllerState m0: 8|2@1+ (1,0) [0|0] "" X
 SG_ VCFRONT_rightControllerFault m0: 10|1@1+ (1,0) [0|0] "" X
 SG_ VCFRONT_vcrightSelfTestResult m0: 11|4@1+ (1,0) [0|0] "" X
 SG_ VCFRONT_rightControllerTemp m0: 15|11@1+ (0.125,-40) [0|0] "degC" X
 SG_ VCFRONT_rightControllerVoltage m0: 31|16@1+ (0.1,0) [0|0] "V" X
 SG_ VCFRONT_rightControllerCurrent m0: 47|16@1+ (0.1,0) [0|0] "A" X
 SG_ VCFRONT_leftControllerState m1: 8|2@1+ (1,0) [0|0] "" X
 SG_ VCFRONT_leftControllerFault m1: 10|1@1+ (1,0) [0|0] "" X
 SG_ VCFRONT_vcleftSelfTestResult m1: 11|4@1+ (1,0) [0|0] "" X
 SG_ VCFRONT_leftControllerTemp m1: 15|11@1+ (0.125,-40) [0|0] "degC" X
 SG_ VCFRONT_leftControllerVoltage m1: 31|16@1+ (0.1,0) [0|0] "V" X
 SG_ VCFRONT_leftControllerCurrent m1: 47|16@1+ (0.1,0) [0|0] "A" X
 SG_ VCFRONT_PCSState m2: 8|2@1+ (1,0) [0|0] "" X
 SG_ VCFRONT_PCSFault m2: 10|1@1+ (1,0) [0|0] "" X
 SG_ VCFRONT_pcsSelfTestResult m2: 11|4@1+ (1,0) [0|0] "" X
 SG_ VCFRONT_PCSTemp m2: 15|11@1+ (0.125,-40) [0|0] "degC" X
 SG_ VCFRONT_PCSVoltage m2: 31|16@1+ (0.1,0) [0|0] "V" X
 SG_ VCFRONT_PCSCurrent m2: 47|16@1- (0.1,0) [0|0] "A" X
 SG_ VCFRONT_iBoosterState m3: 8|2@1+ (1,0) [0|0] "" X
 SG_ VCFRONT_iBoosterFault m3: 10|1@1+ (1,0) [0|0] "" X
 SG_ VCFRONT_iBoosterSelfTestResult m3: 11|4@1+ (1,0) [0|0] "" X
 SG_ VCFRONT_iBoosterTemp m3: 15|11@1+ (0.125,-40) [0|0] "degC" X
 SG_ VCFRONT_iBoosterVoltage m3: 31|16@1+ (0.1,0) [0|0] "V" X
 SG_ VCFRONT_iBoosterCurrent m3: 47|16@1+ (0.1,0) [0|0] "A" X
 SG_ VCFRONT_EPAS3PState m4: 8|2@1+ (1,0) [0|0] "" X
 SG_ VCFRONT_EPAS3PFault m4: 10|1@1+ (1,0) [0|0] "" X
 SG_ VCFRONT_EPAS3PSelfTestResult m4: 11|4@1+ (1,0) [0|0] "" X
 SG_ VCFRONT_EPAS3PTemp m4: 15|11@1+ (0.125,-40) [0|0] "degC" X
 SG_ VCFRONT_EPAS3PVoltage m4: 31|16@1+ (0.1,0) [0|0] "V" X
 SG_ VCFRONT_EPAS3PCurrent m4: 47|16@1+ (0.1,0) [0|0] "A" X
 SG_ VCFRONT_EPAS3SState m5: 8|2@1+ (1,0) [0|0] "" X
 SG_ VCFRONT_EPAS3SFault m5: 10|1@1+ (1,0) [0|0] "" X
 SG_ VCFRONT_EPAS3SSelfTestResult m5: 11|4@1+ (1,0) [0|0] "" X
 SG_ VCFRONT_EPAS3STemp m5: 15|11@1+ (0.125,-40) [0|0] "degC" X
 SG_ VCFRONT_EPAS3SVoltage m5: 31|16@1+ (0.1,0) [0|0] "V" X
 SG_ VCFRONT_EPAS3SCurrent m5: 47|16@1+ (0.1,0) [0|0] "A" X
 SG_ VCFRONT_ESPMotorState m6: 8|2@1+ (1,0) [0|0] "" X
 SG_ VCFRONT_ESPMotorFault m6: 10|1@1+ (1,0) [0|0] "" X
 SG_ VCFRONT_ESPMotorSelfTestResult m6: 11|4@1+ (1,0) [0|0] "" X
 SG_ VCFRONT_ESPMotorTemp m6: 15|11@1+ (0.125,-40) [0|0] "degC" X
 SG_ VCFRONT_ESPMotorVoltage m6: 31|16@1+ (0.1,0) [0|0] "V" X
 SG_ VCFRONT_ESPMotorCurrent m6: 47|16@1+ (0.1,0) [0|0] "A" X
 SG_ VCFRONT_ESPValveState m7: 8|2@1+ (1,0) [0|0] "" X
 SG_ VCFRONT_ESPValveFault m7: 10|1@1+ (1,0) [0|0] "" X
 SG_ VCFRONT_ESPValveTemp m7: 12|11@1+ (0.125,-40) [0|0] "degC" X
 SG_ VCFRONT_ESPValveVoltage m7: 28|16@1+ (0.1,0) [0|0] "V" X
 SG_ VCFRONT_ESPValveCurrent m7: 44|16@1+ (0.1,0) [0|0] "A" X
 SG_ VCFRONT_autopilot1State m8: 8|2@1+ (1,0) [0|0] "" X
 SG_ VCFRONT_autopilot1Fault m8: 10|1@1+ (1,0) [0|0] "" X
 SG_ VCFRONT_autopilot1Temp m8: 11|11@1+ (0.125,-40) [0|0] "degC" X
 SG_ VCFRONT_autopilot1Voltage m8: 27|16@1+ (0.1,0) [0|0] "V" X
 SG_ VCFRONT_autopilot1Current m8: 43|16@1+ (0.1,0) [0|0] "A" X
 SG_ VCFRONT_autopilot2State m9: 8|2@1+ (1,0) [0|0] "" X
 SG_ VCFRONT_autopilot2Fault m9: 10|1@1+ (1,0) [0|0] "" X
 SG_ VCFRONT_autopilot2Temp m9: 11|11@1+ (0.125,-40) [0|0] "degC" X
 SG_ VCFRONT_autopilot2Voltage m9: 27|16@1+ (0.1,0) [0|0] "V" X
 SG_ VCFRONT_autopilot2Current m9: 43|16@1+ (0.1,0) [0|0] "A" X
 SG_ VCFRONT_sleepBypassState m10: 8|1@1+ (1,0) [0|0] "" X
 SG_ VCFRONT_sleepBypassFault m10: 9|1@1+ (1,0) [0|0] "" X
 SG_ VCFRONT_sleepBypassVoltage m10: 10|16@1+ (0.1,0) [0|0] "V" X
 SG_ VCFRONT_sleepBypassCurrent m10: 26|16@1+ (0.1,0) [0|0] "A" X
 SG_ VCFRONT_uiAudioState m11: 5|1@1+ (1,0) [0|0] "" X
 SG_ VCFRONT_uiAudioFault m11: 6|1@1+ (1,0) [0|0] "" X
 SG_ VCFRONT_uiAudioCurrent m11: 8|16@1+ (0.1,0) [0|0] "A" X
 SG_ VCFRONT_uiState m11: 24|1@1+ (1,0) [0|0] "" X
 SG_ VCFRONT_uiFault m11: 25|1@1+ (1,0) [0|0] "" X
 SG_ VCFRONT_uiCurrent m11: 32|16@1+ (0.1,0) [0|0] "A" X
 SG_ VCFRONT_headlampLeftState m12: 8|1@1+ (1,0) [0|0] "" X
 SG_ VCFRONT_headlampLeftFault m12: 9|1@1+ (1,0) [0|0] "" X
 SG_ VCFRONT_headlampLeftCurrent m12: 10|10@1+ (0.1,0) [0|0] "A" X
 SG_ VCFRONT_headlampLeftVoltage m12: 20|8@1+ (0.1,0) [0|0] "V" X
 SG_ VCFRONT_headlampRightState m12: 28|1@1+ (1,0) [0|0] "" X
 SG_ VCFRONT_headlampRightFault m12: 29|1@1+ (1,0) [0|0] "" X
 SG_ VCFRONT_headlampRightCurrent m12: 30|10@1+ (0.1,0) [0|0] "A" X
 SG_ VCFRONT_headlampRightVoltage m12: 40|8@1+ (0.1,0) [0|0] "V" X
 SG_ VCFRONT_headlampLeftTemperature m12: 48|8@1- (1,-40) [0|0] "degC" X
 SG_ VCFRONT_headlampRightTemperature m12: 56|8@1- (1,-40) [0|0] "degC" X
 SG_ VCFRONT_vbatFusedHighState m13: 8|1@1+ (1,0) [0|0] "" X
 SG_ VCFRONT_vbatFusedHighFault m13: 9|1@1+ (1,0) [0|0] "" X
 SG_ VCFRONT_vbatFusedSelfTestResult m13: 10|4@1+ (1,0) [0|0] "" X
 SG_ VCFRONT_vbatFusedHighTemp m13: 14|11@1+ (0.125,-40) [0|0] "degC" X
 SG_ VCFRONT_vbatFusedHighVoltage m13: 30|16@1+ (0.1,0) [0|0] "V" X
 SG_ VCFRONT_vbatFusedHighCurrent m13: 46|16@1+ (0.1,0) [0|0] "A" X
 SG_ VCFRONT_pump1AndFanState m14: 5|1@1+ (1,0) [0|0] "" X
 SG_ VCFRONT_pump1AndFanCurrent m14: 6|16@1+ (0.1,0) [0|0] "A" X
 SG_ VCFRONT_pump1AndFanVoltage m14: 22|12@1+ (0.1,0) [0|0] "V" X
 SG_ VCFRONT_pump2AndAirCompState m14: 34|1@1+ (1,0) [0|0] "" X
 SG_ VCFRONT_pump2AndAirCompCurrent m14: 35|16@1+ (0.1,0) [0|0] "A" X
 SG_ VCFRONT_pump2AndAirCompVoltage m14: 51|12@1+ (0.1,0) [0|0] "V" X
 SG_ VCFRONT_railA_12v m15: 8|12@1+ (0.00544368,0) [0|0] "V" X
 SG_ VCFRONT_railB_12v m15: 20|12@1+ (0.00544368,0) [0|0] "V" X
 SG_ VCFRONT_railA_5v m15: 32|12@1+ (0.00544368,0) [0|0] "V" X
 SG_ VCFRONT_railB_5v m15: 44|12@1+ (0.00544368,0) [0|0] "V" X
 SG_ VCFRONT_eFuseLockoutVoltage m16: 8|12@1+ (0.00544368,0) [0|0] "V" X
 SG_ VCFRONT_ChargePumpVoltage m16: 24|16@1+ (0.00544368,0) [0|0] "V" X
 SG_ VCFRONT_vbatProt m16: 40|12@1+ (0.00544368,0) [0|0] "V" X

BO_ 769 VCFRONT_info: 8 VEH
 SG_ VCFRONT_infoIndex M: 0|8@1+ (1,0) [0|0] "" X
 SG_ VCFRONT_infoBuildType m10: 8|3@1+ (1,0) [0|0] "" X
 SG_ VCFRONT_infoBuildConfigId m10: 16|16@1+ (1,0) [0|0] "" X
 SG_ VCFRONT_infoHardwareId m10: 32|16@1+ (1,0) [0|0] "" X
 SG_ VCFRONT_infoComponentId m10: 48|16@1+ (1,0) [0|0] "" X
 SG_ VCFRONT_infoPcbaId m11: 8|8@1+ (1,0) [0|0] "" X
 SG_ VCFRONT_infoAssemblyId m11: 16|8@1+ (1,0) [0|0] "" X
 SG_ VCFRONT_infoUsageId m11: 24|16@1+ (1,0) [0|0] "" X
 SG_ VCFRONT_infoSubUsageId m11: 40|16@1+ (1,0) [0|0] "" X
 SG_ VCFRONT_infoAppCrc m13: 8|32@1+ (1,0) [0|0] "" X
 SG_ VCFRONT_hcmlAppCRC m16: 32|32@1+ (1,0) [0|0] "" X
 SG_ VCFRONT_infoAppGitHash m17: 10|54@1+ (4,0) [0|0] "" X
 SG_ VCFRONT_infoBootGitHash m18: 10|54@1+ (4,0) [0|0] "" X
 SG_ VCFRONT_infoPlatformType m19: 8|8@1+ (1,0) [0|0] "" X
 SG_ VCFRONT_infoBootUdsProtoVersion m20: 8|16@1+ (1,0) [0|0] "" X
 SG_ VCFRONT_infoBootCrc m20: 24|32@1+ (1,0) [0|0] "" X
 SG_ VCFRONT_hcmrAppCRC m23: 32|32@1+ (1,0) [0|0] "" X
 SG_ VCFRONT_infoSubcomponent3 m24: 32|32@1+ (1,0) [0|0] "" X
 SG_ VCFRONT_infoSubcomponent4 m31: 32|32@1+ (1,0) [0|0] "" X

BO_ 1009 VCFRONT_lighting: 8 VEH
 SG_ VCFRONT_DRLLeftStatus: 36|2@1+ (1,0) [0|0] "" X
 SG_ VCFRONT_DRLRightStatus: 38|2@1+ (1,0) [0|0] "" X
 SG_ VCFRONT_ambientLightingBrightnes: 8|8@1+ (0.5,0) [0|0] "%" X
 SG_ VCFRONT_approachLightingRequest: 25|1@1+ (1,0) [0|0] "" X
 SG_ VCFRONT_courtesyLightingRequest: 24|1@1+ (1,0) [0|0] "" X
 SG_ VCFRONT_fogLeftStatus: 40|2@1+ (1,0) [0|0] "" X
 SG_ VCFRONT_fogRightStatus: 42|2@1+ (1,0) [0|0] "" X
 SG_ VCFRONT_hazardLightRequest: 4|3@1+ (1,0) [0|0] "" X
 SG_ VCFRONT_hazardSwitchBacklight: 27|1@1+ (1,0) [0|0] "" X
 SG_ VCFRONT_highBeamLeftStatus: 32|2@1+ (1,0) [0|0] "" X
 SG_ VCFRONT_highBeamRightStatus: 34|2@1+ (1,0) [0|0] "" X
 SG_ VCFRONT_highBeamSwitchActive: 58|1@1+ (1,0) [0|0] "" X
 SG_ VCFRONT_indicatorLeftRequest: 0|2@1+ (1,0) [0|0] "" X
 SG_ VCFRONT_indicatorRightRequest: 2|2@1+ (1,0) [0|0] "" X
 SG_ VCFRONT_lowBeamLeftStatus: 28|2@1+ (1,0) [0|0] "" X
 SG_ VCFRONT_lowBeamRightStatus: 30|2@1+ (1,0) [0|0] "" X
 SG_ VCFRONT_lowBeamsCalibrated: 62|1@1+ (1,0) [0|0] "" X
 SG_ VCFRONT_lowBeamsOnForDRL: 61|1@1+ (1,0) [0|0] "" X
 SG_ VCFRONT_parkLeftStatus: 54|2@1+ (1,0) [0|0] "" X
 SG_ VCFRONT_parkRightStatus: 56|2@1+ (1,0) [0|0] "" X
 SG_ VCFRONT_seeYouHomeLightingReq: 26|1@1+ (1,0) [0|0] "" X
 SG_ VCFRONT_sideMarkersStatus: 44|2@1+ (1,0) [0|0] "" X
 SG_ VCFRONT_sideRepeaterLeftStatus: 46|2@1+ (1,0) [0|0] "" X
 SG_ VCFRONT_sideRepeaterRightStatus: 48|2@1+ (1,0) [0|0] "" X
 SG_ VCFRONT_simLatchingStalk: 59|2@1+ (1,0) [0|0] "" X
 SG_ VCFRONT_switchLightingBrightness: 16|8@1+ (0.5,0) [0|0] "%" X
 SG_ VCFRONT_turnSignalLeftStatus: 50|2@1+ (1,0) [0|0] "" X
 SG_ VCFRONT_turnSignalRightStatus: 52|2@1+ (1,0) [0|0] "" X

BO_ 705 VCFRONT_logging10Hz: 8 VEH
 SG_ VCFRONT_logging10HzIndex M : 0|3@1+ (1,0) [0|7] "" X
 SG_ VCFRONT_activeLouverAbnormalKT m4 : 3|1@1+ (1,0) [0|1] "" X
 SG_ VCFRONT_activeLouverCalibRange m4 : 53|8@1+ (1,630) [630|880] "ticks" X
 SG_ VCFRONT_activeLouverCommSuccess m4 : 63|1@1+ (1,0) [0|1] "" X
 SG_ VCFRONT_activeLouverDemand m4 : 32|7@1+ (1,0) [0|100] "%" X
 SG_ VCFRONT_activeLouverDisconnect m4 : 6|1@1+ (1,0) [0|1] "" X
 SG_ VCFRONT_activeLouverFalsStallCal m4 : 62|1@1+ (1,0) [0|1] "" X
 SG_ VCFRONT_activeLouverFalsStallRun m4 : 61|1@1+ (1,0) [0|1] "" X
 SG_ VCFRONT_activeLouverIsCalibrated m4 : 15|1@1+ (1,0) [0|1] "" X
 SG_ VCFRONT_activeLouverMotorCounts m4 : 16|11@1+ (1,-100) [-100|1900] "ticks" X
 SG_ VCFRONT_activeLouverMotorState m4 : 8|3@1+ (1,0) [0|7] "" X
 SG_ VCFRONT_activeLouverOverCurrent m4 : 4|1@1+ (1,0) [0|1] "" X
 SG_ VCFRONT_activeLouverOverTemp m4 : 5|1@1+ (1,0) [0|1] "" X
 SG_ VCFRONT_activeLouverStallCounter m4 : 40|3@1+ (1,0) [0|7] "" X
 SG_ VCFRONT_activeLouverStallLength m4 : 43|10@1+ (1,0) [0|1000] "ticks" X
 SG_ VCFRONT_activeLouverStalled m4 : 7|1@1+ (1,0) [0|1] "" X
 SG_ VCFRONT_activeLouverState m4 : 11|4@1+ (1,0) [0|8] "" X
 SG_ VCFRONT_compLimitDeadband m3 : 8|1@1+ (1,0) [0|1] "" X
 SG_ VCFRONT_compLimitNvh m3 : 6|1@1+ (1,0) [0|1] "" X
 SG_ VCFRONT_compLimitPresDischargeHi m3 : 3|1@1+ (1,0) [0|1] "" X
 SG_ VCFRONT_compLimitScrollSepRamp m3 : 7|1@1+ (1,0) [0|1] "" X
 SG_ VCFRONT_compLimitScrollSepRegion m3 : 5|1@1+ (1,0) [0|1] "" X
 SG_ VCFRONT_compLimitTempDischargeHi m3 : 4|1@1+ (1,0) [0|1] "" X
 SG_ VCFRONT_compLimitTempDischargeSi m3 : 19|1@1+ (1,0) [0|1] "" X
 SG_ VCFRONT_compRampRateUpMax m3 : 20|6@1+ (0.1,0) [0|6] "%/s" X
 SG_ VCFRONT_compStandbyCoastDownMode m3 : 15|1@1+ (1,0) [0|1] "" X
 SG_ VCFRONT_compStandbyCommunication m3 : 10|1@1+ (1,0) [0|1] "" X
 SG_ VCFRONT_compStandbyHVNotReady m3 : 11|1@1+ (1,0) [0|1] "" X
 SG_ VCFRONT_compStandbyHighSuctionSu m3 : 16|1@1+ (1,0) [0|1] "" X
 SG_ VCFRONT_compStandbyLowAmbient m3 : 12|1@1+ (1,0) [0|1] "" X
 SG_ VCFRONT_compStandbyLowDischPress m3 : 13|1@1+ (1,0) [0|1] "" X
 SG_ VCFRONT_compStandbyMultiplePdCut m3 : 17|1@1+ (1,0) [0|1] "" X
 SG_ VCFRONT_compStandbyRefrigNotOk m3 : 14|1@1+ (1,0) [0|1] "" X
 SG_ VCFRONT_compStandbySelfNotReady m3 : 9|1@1+ (1,0) [0|1] "" X
 SG_ VCFRONT_compStandbyShowroomMode m3 : 18|1@1+ (1,0) [0|1] "" X
 SG_ VCFRONT_coolantFlowAmbSourceActu m0 : 48|8@1+ (0.1,0) [0|25] "LPM" X
 SG_ VCFRONT_coolantFlowAmbSourceTarg m0 : 56|8@1+ (0.1,0) [0|25] "LPM" X
 SG_ VCFRONT_coolantTempBasedMode m2 : 3|2@1+ (1,0) [0|3] "" X
 SG_ VCFRONT_coolantValveAngleActual m2 : 8|11@1+ (0.25,-100) [-100|410] "deg" X
 SG_ VCFRONT_coolantValveAngleTarget m2 : 19|10@1+ (0.25,-5) [-5|245] "deg" X
 SG_ VCFRONT_coolantValveAngleTravel m2 : 40|10@1+ (5,0) [0|5000] "deg" X
 SG_ VCFRONT_coolantValveDuty m2 : 32|8@1- (1,0) [-100|100] "%" X
 SG_ VCFRONT_coolantValveISense m2 : 56|7@1+ (0.01,0) [0|1.2] "A" X
 SG_ VCFRONT_coolantValveModeWrong m2 : 5|1@1+ (1,0) [0|1] "" X
 SG_ VCFRONT_coolantValveState m2 : 29|2@1+ (1,0) [0|3] "" X
 SG_ VCFRONT_exvFlow m3 : 32|10@1+ (0.1,0) [0|100] "%" X
 SG_ VCFRONT_exvIsFlooding m3 : 42|1@1+ (1,0) [0|1] "" X
 SG_ VCFRONT_exvMotorState m3 : 28|4@1+ (1,0) [0|10] "" X
 SG_ VCFRONT_exvPrechillActive m3 : 43|1@1+ (1,0) [0|1] "" X
 SG_ VCFRONT_pumpBatSpiError m0 : 46|1@1+ (1,0) [0|1] "" X
 SG_ VCFRONT_pumpBatteryEnabled m0 : 41|1@1+ (1,0) [0|1] "" X
 SG_ VCFRONT_pumpBatteryInitd m0 : 39|1@1+ (1,0) [0|1] "" X
 SG_ VCFRONT_pumpBatteryOutVoltage m0 : 24|7@1+ (0.2,0) [0|20] "V" X
 SG_ VCFRONT_pumpBatteryPowerOn m0 : 43|1@1+ (1,0) [0|1] "" X
 SG_ VCFRONT_pumpBatteryRPMTarget m0 : 3|10@1+ (10,0) [0|10000] "rpm" X
 SG_ VCFRONT_pumpPowertrainEnabled m0 : 42|1@1+ (1,0) [0|1] "" X
 SG_ VCFRONT_pumpPowertrainInitd m0 : 40|1@1+ (1,0) [0|1] "" X
 SG_ VCFRONT_pumpPowertrainOutVoltage m0 : 32|7@1+ (0.2,0) [0|20] "V" X
 SG_ VCFRONT_pumpPowertrainPowerOn m0 : 44|1@1+ (1,0) [0|1] "" X
 SG_ VCFRONT_pumpPowertrainRPMTarget m0 : 13|10@1+ (10,0) [0|10000] "rpm" X
 SG_ VCFRONT_pumpPtSpiError m0 : 47|1@1+ (1,0) [0|1] "" X
 SG_ VCFRONT_pumpsWake m0 : 45|1@1+ (1,0) [0|1] "" X
 SG_ VCFRONT_radarHeaterCurrent m6 : 8|8@1+ (0.1,0) [0|25.5] "A" X
 SG_ VCFRONT_radarHeaterDuty m6 : 16|7@1+ (1,0) [0|100] "%" X
 SG_ VCFRONT_radarHeaterTargetVoltage m6 : 24|8@1+ (0.1,0) [0|16] "V" X
 SG_ VCFRONT_radiatorFanDemandLimit m1 : 48|7@1+ (1,0) [0|100] "%" X
 SG_ VCFRONT_radiatorFanDemandLimited m1 : 47|1@1+ (1,0) [0|1] "" X
 SG_ VCFRONT_radiatorFanEnabled m1 : 27|1@1+ (1,0) [0|1] "" X
 SG_ VCFRONT_radiatorFanInitd m1 : 26|1@1+ (1,0) [0|1] "" X
 SG_ VCFRONT_radiatorFanOutVoltage m1 : 8|7@1+ (0.2,0) [0|20] "V" X
 SG_ VCFRONT_radiatorFanPhaseCurrent m1 : 32|8@1+ (0.25,-10) [-10|50] "A" X
 SG_ VCFRONT_radiatorFanPhaseIMax m1 : 40|7@1+ (0.25,0) [5|35] "A" X
 SG_ VCFRONT_radiatorFanPowerOn m1 : 28|1@1+ (1,0) [0|1] "" X
 SG_ VCFRONT_radiatorFanRPMTarget m1 : 16|10@1+ (10,0) [0|10000] "rpm" X
 SG_ VCFRONT_refrigerantHasBeenFilled m3 : 27|1@1+ (1,0) [0|1] "" X
 SG_ VCFRONT_refrigerantValvesClosed m3 : 26|1@1+ (1,0) [0|1] "" X
 SG_ VCFRONT_solenoidEvapCurrent m3 : 58|6@1+ (0.04,0) [0|2.4] "A" X
 SG_ VCFRONT_subcoolFeedbackFlow m5 : 13|10@1- (0.1,0) [-50|50] "%" X
 SG_ VCFRONT_subcoolFeedforwardFlow m5 : 3|10@1+ (0.1,0) [0|100] "%" X
 SG_ VCFRONT_subcoolProtectionFlow m5 : 24|10@1+ (0.1,0) [0|100] "%" X
 SG_ VCFRONT_subcoolProtectionType m5 : 34|3@1+ (1,0) [0|4] "" X
 SG_ VCFRONT_tempDischargeSimulated m3 : 44|11@1+ (0.125,-40) [-40|150] "C" X
 SG_ VCFRONT_thmlFanSpiError m1 : 55|1@1+ (1,0) [0|1] "" X
 SG_ VCFRONT_usingSimulatedAmbTemp m3 : 57|1@1+ (1,0) [0|1] "" X
 SG_ VCFRONT_usingSimulatedDischTemp m3 : 56|1@1+ (1,0) [0|1] "" X
 SG_ VCFRONT_usingSimulatedSuctTemp m3 : 55|1@1+ (1,0) [0|1] "" X

BO_ 897 VCFRONT_logging1Hz: 8 VEH
 SG_ VCFRONT_logging1HzIndex M : 0|5@1+ (1,0) [0|19] ""  Receiver
 SG_ VCFRONT_CCQdotActual m9 : 21|7@1+ (80,0) [0|10100] "W"  Receiver
 SG_ VCFRONT_CCQdotFdFrwrdTarget m9 : 7|7@1+ (80,0) [0|10100] "W"  Receiver
 SG_ VCFRONT_CCQdotFdbk m9 : 14|7@1- (80,0) [-5000|5000] "W"  Receiver
 SG_ VCFRONT_CMPDischargeSuperheat m8 : 17|5@1- (1,6) [-10|21] "C"  Receiver
 SG_ VCFRONT_DIQdotA m9 : 42|7@1+ (80,0) [0|10000] "W"  Receiver
 SG_ VCFRONT_HCML_bladeTemp m3 : 32|8@1- (1,67) [-60|194] "C"  Receiver
 SG_ VCFRONT_HCML_diffuseTemp m3 : 40|8@1- (1,67) [-60|194] "C"  Receiver
 SG_ VCFRONT_HCML_highBeamTemp m3 : 16|8@1- (1,67) [-60|194] "C"  Receiver
 SG_ VCFRONT_HCML_lowBeamSpotTemp m3 : 8|8@1- (1,67) [-60|194] "C"  Receiver
 SG_ VCFRONT_HCML_turnTemp m3 : 24|8@1- (1,67) [-60|194] "C"  Receiver
 SG_ VCFRONT_HCMR_bladeTemp m4 : 32|8@1- (1,67) [-60|194] "C"  Receiver
 SG_ VCFRONT_HCMR_diffuseTemp m4 : 40|8@1- (1,67) [-60|194] "C"  Receiver
 SG_ VCFRONT_HCMR_highBeamTemp m4 : 16|8@1- (1,67) [-60|194] "C"  Receiver
 SG_ VCFRONT_HCMR_lowBeamSpotTemp m4 : 8|8@1- (1,67) [-60|194] "C"  Receiver
 SG_ VCFRONT_HCMR_turnTemp m4 : 24|8@1- (1,67) [-60|194] "C"  Receiver
 SG_ VCFRONT_PDischargeControllerOutp m14 : 24|8@1+ (0.5,0) [0|100] "%"  Receiver
 SG_ VCFRONT_PSuctionControllerOutput m14 : 40|8@1+ (0.5,0) [0|100] "%"  Receiver
 SG_ VCFRONT_ambientColderThanBatt m16 : 8|1@1+ (1,0) [0|1] ""  Receiver
 SG_ VCFRONT_ambientSourcingAvailable m16 : 9|1@1+ (1,0) [0|1] ""  Receiver
 SG_ VCFRONT_ambientSourcingDisabled m14 : 38|1@1+ (1,0) [0|1] ""  Receiver
 SG_ VCFRONT_battDissipation m12 : 8|8@1+ (140,0) [0|35000] "W"  Receiver
 SG_ VCFRONT_battLoopWorthCooling m16 : 15|1@1+ (1,0) [0|1] ""  Receiver
 SG_ VCFRONT_battOverStagUpperLimit m16 : 6|1@1+ (1,0) [0|1] ""  Receiver
 SG_ VCFRONT_battUnderStagUpperLimit m16 : 7|1@1+ (1,0) [0|1] ""  Receiver
 SG_ VCFRONT_cabinHeatEnergyDuringDri m8 : 42|7@1+ (150,0) [0|19000] "Wh"  Receiver
 SG_ VCFRONT_calibratedPositionHCML m6 : 5|10@1+ (1,0) [0|1023] "Steps"  Receiver
 SG_ VCFRONT_calibratedPositionHCMR m6 : 16|10@1+ (1,0) [0|1023] "Steps"  Receiver
 SG_ VCFRONT_ccLeftExvCalibFailed m11 : 60|1@1+ (1,0) [0|1] ""  Receiver
 SG_ VCFRONT_ccLeftExvCalibOffset m11 : 40|8@1- (4,0) [-510|510] "ticks"  Receiver
 SG_ VCFRONT_ccLeftExvRange m7 : 41|9@1+ (3,0) [0|1500] "ticks"  Receiver
 SG_ VCFRONT_ccRightExvCalibFailed m11 : 61|1@1+ (1,0) [0|1] ""  Receiver
 SG_ VCFRONT_ccRightExvCalibOffset m11 : 48|8@1- (4,0) [-510|510] "ticks"  Receiver
 SG_ VCFRONT_ccRightExvRange m7 : 50|9@1+ (3,0) [0|1500] "ticks"  Receiver
 SG_ VCFRONT_chillerExvCalibFailed m11 : 56|1@1+ (1,0) [0|1] ""  Receiver
 SG_ VCFRONT_chillerExvCalibOffset m11 : 8|8@1- (4,0) [-510|510] "ticks"  Receiver
 SG_ VCFRONT_chillerExvRange m7 : 5|9@1+ (3,0) [0|1500] "ticks"  Receiver
 SG_ VCFRONT_chillerInletTempEstimate m13 : 27|8@1- (1,0) [-40|85] "C"  Receiver
 SG_ VCFRONT_chillerLiftDisabledLowPs m14 : 39|1@1+ (1,0) [0|1] ""  Receiver
 SG_ VCFRONT_chillerPassiveCoolPower m12 : 24|8@1- (60,7560) [0|15000] "W"  Receiver
 SG_ VCFRONT_compEnergyDuringDrive m8 : 35|7@1+ (150,0) [0|19000] "Wh"  Receiver
 SG_ VCFRONT_condenserPressureLimit m1 : 8|6@1+ (0.16,10) [10|20] "bar"  Receiver
 SG_ VCFRONT_coolantLevelVoltage m0 : 55|9@1+ (0.01,0) [0|5] "V"  Receiver
 SG_ VCFRONT_coolantValveAngleDrift m2 : 18|10@1+ (0.25,-127) [-127|127] "degrees"  Receiver
 SG_ VCFRONT_coolantValveCountRange m2 : 8|10@1+ (1,375) [375|1375] "ticks"  Receiver
 SG_ VCFRONT_coolantValveRadBypass m2 : 56|7@1+ (1,0) [0|100] "%"  Receiver
 SG_ VCFRONT_coolantValveRecalCount m2 : 28|16@1+ (1,0) [0|65535] ""  Receiver
 SG_ VCFRONT_coolantValveRecalReason m2 : 5|3@1+ (1,0) [0|6] ""  Receiver
 SG_ VCFRONT_coolantValveWindupEstL m2 : 44|6@1+ (2,0) [0|126] "ticks"  Receiver
 SG_ VCFRONT_coolantValveWindupEstR m2 : 50|6@1+ (2,0) [0|126] "ticks"  Receiver
 SG_ VCFRONT_currentPositionHCML m6 : 26|10@1+ (1,0) [0|1023] "Steps"  Receiver
 SG_ VCFRONT_currentPositionHCMR m6 : 36|10@1+ (1,0) [0|1023] "Steps"  Receiver
 SG_ VCFRONT_cycleModelConverged m10 : 61|1@1+ (1,0) [0|1] ""  Receiver
 SG_ VCFRONT_diDissipation m12 : 16|8@1+ (80,0) [0|20000] "W"  Receiver
 SG_ VCFRONT_dischargePressureTarget m14 : 8|7@1+ (0.25,0) [0|26] "bar"  Receiver
 SG_ VCFRONT_estCompPower m16 : 48|8@1+ (50,0) [0|12750] "W"  Receiver
 SG_ VCFRONT_estCompPressureInlet m16 : 24|8@1+ (0.05,0) [0|12.75] "bar"  Receiver
 SG_ VCFRONT_estCompPressureOutlet m16 : 32|8@1+ (0.1,0) [1|26.5] "bar"  Receiver
 SG_ VCFRONT_estCompRefrigMassflow m16 : 17|7@1+ (2,0) [0|254] "g/s"  Receiver
 SG_ VCFRONT_estCompTempOutlet m16 : 40|8@1+ (1.5,0) [0|190.5] "C"  Receiver
 SG_ VCFRONT_estCompressorRpm m10 : 48|6@1+ (400,0) [0|25200] "rpm"  Receiver
 SG_ VCFRONT_estPressureDisch m10 : 19|7@1+ (0.25,0) [0|31.75] "bar"  Receiver
 SG_ VCFRONT_estPressureLiq m10 : 5|7@1+ (0.25,0) [0|31.75] "bar"  Receiver
 SG_ VCFRONT_estPressureSuct m10 : 12|7@1+ (0.125,0) [0|11.5] "bar"  Receiver
 SG_ VCFRONT_estQLift m10 : 54|7@1+ (100,0) [0|12700] "W"  Receiver
 SG_ VCFRONT_estTempDisch m10 : 40|8@1- (0.8,68.8) [-34|170] "C"  Receiver
 SG_ VCFRONT_estTempLiq m10 : 26|8@1- (0.8,68.8) [-34|170] "C"  Receiver
 SG_ VCFRONT_estTempSuct m10 : 34|6@1- (1,2) [-30|33] "C"  Receiver
 SG_ VCFRONT_evapDisabledLowPsCutout m14 : 15|1@1+ (1,0) [0|1] ""  Receiver
 SG_ VCFRONT_evapExvCalibFailed m11 : 57|1@1+ (1,0) [0|1] ""  Receiver
 SG_ VCFRONT_evapExvCalibOffset m11 : 16|8@1- (4,0) [-510|510] "ticks"  Receiver
 SG_ VCFRONT_evapExvRange m7 : 14|9@1+ (3,0) [0|1500] "ticks"  Receiver
 SG_ VCFRONT_evapFdFrwrdTarget m9 : 28|7@1+ (80,0) [0|10100] "W"  Receiver
 SG_ VCFRONT_evapFdFrwrdTargetMinimum m9 : 49|7@1+ (80,0) [0|10000] "W"  Receiver
 SG_ VCFRONT_evapFdbk m9 : 35|7@1- (80,0) [-5000|5000] "W"  Receiver
 SG_ VCFRONT_exteriorQuietModeAllowed m9 : 6|1@1+ (1,0) [0|1] ""  Receiver
 SG_ VCFRONT_exteriorQuietModeEnabled m9 : 5|1@1+ (1,0) [0|1] ""  Receiver
 SG_ VCFRONT_fanControlFeedfwdActive m15 : 49|1@1+ (1,0) [0|1] ""  Receiver
 SG_ VCFRONT_fanControlRadCanCool m15 : 48|1@1+ (1,0) [0|1] ""  Receiver
 SG_ VCFRONT_fanControlRadiatorInletT m15 : 57|6@1- (1.8,36) [-20|90] "C"  Receiver
 SG_ VCFRONT_fanControlRadiatorUa m15 : 50|7@1+ (8,0) [0|1000] "W/C"  Receiver
 SG_ VCFRONT_fanDemandCondenser m1 : 14|7@1+ (1,0) [0|100] "%"  Receiver
 SG_ VCFRONT_fanDemandRadiator m1 : 21|7@1+ (1,0) [0|100] "%"  Receiver
 SG_ VCFRONT_feedBackDuctTempControll m15 : 32|8@1+ (1,-100) [-100|100] "-"  Receiver
 SG_ VCFRONT_feedBackEvapTempControll m15 : 24|7@1+ (0.01,-0.5) [-0.5|0.5] "-"  Receiver
 SG_ VCFRONT_feedFwdFanDemand m13 : 35|7@1+ (1,0) [0|100] "%"  Receiver
 SG_ VCFRONT_feedFwdMDotCabinCondense m15 : 16|8@1+ (0.005,0) [0|1] "-"  Receiver
 SG_ VCFRONT_feedFwdMDotEvaporator m15 : 8|8@1+ (0.005,0) [0|1] "-"  Receiver
 SG_ VCFRONT_feedFwdPumpDemand m13 : 42|7@1+ (1,0) [0|100] "%"  Receiver
 SG_ VCFRONT_feedfwdLoadCoolingDomina m9 : 59|1@1+ (1,0) [0|1] ""  Receiver
 SG_ VCFRONT_homelinkRegionCode m5 : 8|4@1+ (1,0) [0|9] ""  Receiver
 SG_ VCFRONT_hpAmbientSource m17 : 6|1@1+ (1,0) [0|1] ""  Receiver
 SG_ VCFRONT_hpAtSteadyState m16 : 63|1@1+ (1,0) [0|1] ""  Receiver
 SG_ VCFRONT_hpBattStagTarget m8 : 28|7@1+ (1,-40) [-40|80] "C"  Receiver
 SG_ VCFRONT_hpBatteryCool m17 : 19|1@1+ (1,0) [0|1] ""  Receiver
 SG_ VCFRONT_hpBatteryCoolCabinConden m17 : 20|1@1+ (1,0) [0|1] ""  Receiver
 SG_ VCFRONT_hpBatteryCoolCabinReheat m17 : 21|1@1+ (1,0) [0|1] ""  Receiver
 SG_ VCFRONT_hpBatteryCoolEvaporator m17 : 22|1@1+ (1,0) [0|1] ""  Receiver
 SG_ VCFRONT_hpBatteryHeatAmbientSour m17 : 17|1@1+ (1,0) [0|1] ""  Receiver
 SG_ VCFRONT_hpBatteryHeatCOP1 m17 : 18|1@1+ (1,0) [0|1] ""  Receiver
 SG_ VCFRONT_hpCOP m8 : 22|6@1+ (0.1,0) [0|6] "-"  Receiver
 SG_ VCFRONT_hpCabinCoolEvaporator m17 : 15|1@1+ (1,0) [0|1] ""  Receiver
 SG_ VCFRONT_hpCabinCoolEvaporatorReh m17 : 16|1@1+ (1,0) [0|1] ""  Receiver
 SG_ VCFRONT_hpCabinHeatAmbientSource m17 : 8|1@1+ (1,0) [0|1] ""  Receiver
 SG_ VCFRONT_hpCabinHeatBatteryCoolRe m17 : 14|1@1+ (1,0) [0|1] ""  Receiver
 SG_ VCFRONT_hpCabinHeatBatteryHeatRe m17 : 13|1@1+ (1,0) [0|1] ""  Receiver
 SG_ VCFRONT_hpCabinHeatBlend m17 : 11|1@1+ (1,0) [0|1] ""  Receiver
 SG_ VCFRONT_hpCabinHeatCOP1 m17 : 12|1@1+ (1,0) [0|1] ""  Receiver
 SG_ VCFRONT_hpCabinHeatReheatAmbient m17 : 10|1@1+ (1,0) [0|1] ""  Receiver
 SG_ VCFRONT_hpCabinHeatReheatScaveng m17 : 9|1@1+ (1,0) [0|1] ""  Receiver
 SG_ VCFRONT_hpCabinHeatScavengeOnly m17 : 7|1@1+ (1,0) [0|1] ""  Receiver
 SG_ VCFRONT_hpCompPowerIndex m16 : 56|7@1+ (1,0) [0|127] "-"  Receiver
 SG_ VCFRONT_hpForceScavenge m16 : 5|1@1+ (1,0) [0|1] ""  Receiver
 SG_ VCFRONT_hpGeneral m17 : 5|1@1+ (1,0) [0|1] ""  Receiver
 SG_ VCFRONT_hpMode m16 : 10|5@1+ (1,0) [0|19] ""  Receiver
 SG_ VCFRONT_hpPotentialLowRefrig m9 : 61|1@1+ (1,0) [0|1] ""  Receiver
 SG_ VCFRONT_hpRefrigerantPurgeState m9 : 62|2@1+ (1,0) [0|2] ""  Receiver
 SG_ VCFRONT_hpSubcoolTarget m8 : 12|5@1+ (1,0) [0|31] "C"  Receiver
 SG_ VCFRONT_lccExvCalibFailed m11 : 59|1@1+ (1,0) [0|1] ""  Receiver
 SG_ VCFRONT_lccExvCalibOffset m11 : 32|8@1- (4,0) [-510|510] "ticks"  Receiver
 SG_ VCFRONT_lccExvRange m7 : 32|9@1+ (3,0) [0|1500] "ticks"  Receiver
 SG_ VCFRONT_lccInletTempEstimate m13 : 19|8@1- (1,0) [-40|85] "C"  Receiver
 SG_ VCFRONT_lccPassiveHeatPower m12 : 32|8@1+ (60,0) [0|15000] "W"  Receiver
 SG_ VCFRONT_lowSideLiftEnergyDrive m8 : 49|7@1+ (150,0) [0|19000] "Wh"  Receiver
 SG_ VCFRONT_lowSideWattsLift m8 : 56|7@1+ (60,0) [0|7600] "W"  Receiver
 SG_ VCFRONT_maxAllowedEvapPowerInSer m12 : 40|8@1+ (40,0) [0|10000] "W"  Receiver
 SG_ VCFRONT_maxChillerCoolingPower m15 : 40|8@1+ (100,0) [0|20000] "W"  Receiver
 SG_ VCFRONT_maxCompressorRPMAllowed m14 : 56|7@1+ (90,0) [0|11430] "rpm"  Receiver
 SG_ VCFRONT_minAllowedChillerPowerIn m12 : 48|8@1+ (40,0) [0|10000] "W"  Receiver
 SG_ VCFRONT_minAllowedSuctionPressur m14 : 48|7@1+ (0.02,0) [0|2.5] "bar"  Receiver
 SG_ VCFRONT_minFlowPDCont m14 : 16|8@1+ (0.5,0) [0|100] "%"  Receiver
 SG_ VCFRONT_modeDesired m0 : 14|2@1+ (1,0) [0|3] ""  Receiver
 SG_ VCFRONT_modeTransitionID m0 : 8|6@1+ (1,0) [0|39] ""  Receiver
 SG_ VCFRONT_modelLoadCoolingDominant m9 : 60|1@1+ (1,0) [0|1] ""  Receiver
 SG_ VCFRONT_passiveCoolingState m9 : 56|2@1+ (1,0) [0|3] ""  Receiver
 SG_ VCFRONT_ptLoopWorthCooling m16 : 16|1@1+ (1,0) [0|1] ""  Receiver
 SG_ VCFRONT_pumpBatteryFETTemp m1 : 36|8@1+ (1,-40) [-40|150] "C"  Receiver
 SG_ VCFRONT_pumpPowertrainFETTemp m1 : 44|8@1+ (1,-40) [-40|150] "C"  Receiver
 SG_ VCFRONT_radActiveRejectEstimate m13 : 49|15@1+ (1,0) [0|30000] "W"  Receiver
 SG_ VCFRONT_radPassiveRejectEstimate m13 : 5|14@1+ (1,0) [0|15000] "W"  Receiver
 SG_ VCFRONT_radiatorFanFETTemp m1 : 52|8@1+ (1,-40) [-40|150] "C"  Receiver
 SG_ VCFRONT_radiatorFanRunReason m1 : 60|4@1+ (1,0) [0|8] ""  Receiver
 SG_ VCFRONT_recircExvCalibFailed m11 : 58|1@1+ (1,0) [0|1] ""  Receiver
 SG_ VCFRONT_recircExvCalibOffset m11 : 24|8@1- (4,0) [-510|510] "ticks"  Receiver
 SG_ VCFRONT_recircExvRange m7 : 23|9@1+ (3,0) [0|1500] "ticks"  Receiver
 SG_ VCFRONT_subcoolActual m8 : 5|7@1- (0.4,15.2) [-10|40] "C"  Receiver
 SG_ VCFRONT_suctionPressureTarget m14 : 32|6@1+ (0.15,0) [0|8] "bar"  Receiver
 SG_ VCFRONT_targetBatActiveCool m0 : 32|7@1+ (1,0) [0|100] "C"  Receiver
 SG_ VCFRONT_targetBatActiveHeat m0 : 48|7@1+ (1,-40) [-40|60] "C"  Receiver
 SG_ VCFRONT_targetBatPassive m0 : 40|7@1+ (1,-20) [-20|80] "C"  Receiver
 SG_ VCFRONT_targetPTActiveCool m0 : 16|8@1+ (1,-40) [-40|120] "C"  Receiver
 SG_ VCFRONT_targetPTPassive m0 : 24|8@1+ (1,-40) [-40|120] "C"  Receiver
 SG_ VCFRONT_tempRefrigSuction m1 : 28|8@1+ (0.5,-40) [-40|85] "C"  Receiver
 SG_ VCFRONT_totalLoadCoolingDominant m9 : 58|1@1+ (1,0) [0|1] ""  Receiver
 SG_ VCFRONT_wiperCycles m18 : 48|16@1+ (100,0) [0|6553500] "Cycles"  Receiver

BO_ 721 VCFRONT_okToUseHighPower: 1 VEH
 SG_ VCFRONT_cpOkToUseHighPower: 6|1@1+ (1,0) [0|0] "" X
 SG_ VCFRONT_das1OkToUseHighPower: 2|1@1+ (1,0) [0|0] "" X
 SG_ VCFRONT_das2OkToUseHighPower: 3|1@1+ (1,0) [0|0] "" X
 SG_ VCFRONT_premAudioOkToUseHiPower: 7|1@1+ (1,0) [0|0] "" X
 SG_ VCFRONT_uiAudioOkToUseHighPower: 5|1@1+ (1,0) [0|0] "" X
 SG_ VCFRONT_uiOkToUseHighPower: 4|1@1+ (1,0) [0|0] "" X
 SG_ VCFRONT_vcleftOkToUseHighPower: 0|1@1+ (1,0) [0|0] "" X
 SG_ VCFRONT_vcrightOkToUseHighPower: 1|1@1+ (1,0) [0|0] "" X

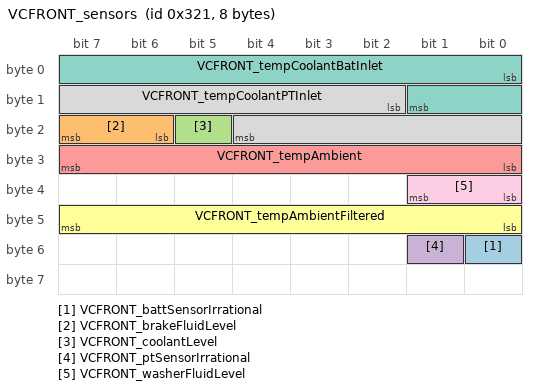
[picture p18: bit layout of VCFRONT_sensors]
BO_ 801 VCFRONT_sensors: 8 VEH
 SG_ VCFRONT_battSensorIrrational: 48|1@1+ (1,0) [0|0] "" X
 SG_ VCFRONT_brakeFluidLevel: 22|2@1+ (1,0) [0|0] "" X
 SG_ VCFRONT_coolantLevel: 21|1@1+ (1,0) [0|0] "" X
 SG_ VCFRONT_ptSensorIrrational: 49|1@1+ (1,0) [0|0] "" X
 SG_ VCFRONT_tempAmbient: 24|8@1+ (0.5,-40) [0|0] "degC" X
 SG_ VCFRONT_tempAmbientFiltered: 40|8@1+ (0.5,-40) [0|0] "degC" X
 SG_ VCFRONT_tempCoolantBatInlet: 0|10@1+ (0.125,-40) [0|0] "degC" X
 SG_ VCFRONT_tempCoolantPTInlet: 10|11@1+ (0.125,-40) [0|0] "degC" X
 SG_ VCFRONT_washerFluidLevel: 32|2@1+ (1,0) [0|0] "" X

BO_ 737 VCFRONT_status: 8 VEH
 SG_ VCFRONT_statusIndex M : 0|3@1+ (1,0) [0|6] "" X
 SG_ VCFRONT_12VARailStable m5 : 5|1@1+ (1,0) [0|1] "" X
 SG_ VCFRONT_12VBRailStable m5 : 6|1@1+ (1,0) [0|1] "" X
 SG_ VCFRONT_12VOverchargeCounter m4 : 16|4@1+ (1,0) [0|15] "" X
 SG_ VCFRONT_5VARailStable m5 : 3|1@1+ (1,0) [0|1] "" X
 SG_ VCFRONT_5VBRailStable m5 : 4|1@1+ (1,0) [0|1] "" X
 SG_ VCFRONT_AS8510Voltage m5 : 28|12@1+ (0.00544368,0) [0|22.2864] "V" X
 SG_ VCFRONT_ChargePumpVoltageStable m5 : 9|1@1+ (1,0) [0|1] "" X
 SG_ VCFRONT_HSDInitCompleteU13 m5 : 11|1@1+ (1,0) [0|1] "" X
 SG_ VCFRONT_HSDInitCompleteU16 m5 : 12|1@1+ (1,0) [0|1] "" X
 SG_ VCFRONT_IBSFault m4 : 15|1@1+ (1,0) [0|1] "" X
 SG_ VCFRONT_PCSMia m4 : 14|1@1+ (1,0) [0|1] "" X
 SG_ VCFRONT_PEResetLineState m5 : 10|1@1+ (1,0) [0|1] "" X
 SG_ VCFRONT_airCompressorStatus m0 : 25|3@1+ (1,0) [0|7] "" X
 SG_ VCFRONT_anyClosureOpen m0 : 49|1@1+ (1,0) [0|1] "" X
 SG_ VCFRONT_anyDoorOpen m0 : 50|1@1+ (1,0) [0|1] "" X
 SG_ VCFRONT_batterySMState m1 : 16|4@1+ (1,0) [0|8] "" X
 SG_ VCFRONT_chargeNeeded m4 : 13|1@1+ (1,0) [0|1] "" X
 SG_ VCFRONT_chillerDemandActive m3 : 26|1@1+ (1,0) [0|1] "" X
 SG_ VCFRONT_compPerfRecoveryLimited m3 : 27|1@1+ (1,0) [0|1] "" X
 SG_ VCFRONT_coolantFillRoutineStatus m3 : 50|2@1+ (1,0) [0|3] "" X
 SG_ VCFRONT_crashDetectedType m0 : 20|2@1+ (1,0) [0|2] "" X
 SG_ VCFRONT_crashState m0 : 22|2@1+ (1,0) [0|2] "" X
 SG_ VCFRONT_crashUnlockOverrideSet m0 : 24|1@1+ (1,0) [0|1] "" X
 SG_ VCFRONT_epasWakeLine m1 : 4|1@1+ (1,0) [0|1] "" X
 SG_ VCFRONT_freezeEvapITerm m3 : 24|1@1+ (1,0) [0|1] "" X
 SG_ VCFRONT_frunkAccessPost m0 : 62|1@1+ (1,0) [0|1] "" X
 SG_ VCFRONT_frunkInteriorRelSwitch m0 : 48|1@1+ (1,0) [0|1] "" X
 SG_ VCFRONT_frunkLatchStatus m0 : 3|4@1+ (1,0) [0|8] "" X
 SG_ VCFRONT_frunkLatchType m0 : 58|2@1+ (1,0) [0|2] "" X
 SG_ VCFRONT_hasLowRefrigerant m3 : 29|1@1+ (1,0) [0|1] "" X
 SG_ VCFRONT_headlampLeftFanStatus m0 : 60|1@1+ (1,0) [0|1] "" X
 SG_ VCFRONT_headlampRightFanStatus m0 : 61|1@1+ (1,0) [0|1] "" X
 SG_ VCFRONT_headlightLeftVPosition m0 : 28|10@1+ (1,0) [0|1023] "ticks" X
 SG_ VCFRONT_headlightRightVPosition m0 : 38|10@1+ (1,0) [0|1023] "ticks" X
 SG_ VCFRONT_homelinkCommStatus m2 : 48|2@1+ (1,0) [0|3] "" X
 SG_ VCFRONT_homelinkV2Response0 m2 : 8|8@1+ (1,0) [0|255] "" X
 SG_ VCFRONT_homelinkV2Response1 m2 : 16|8@1+ (1,0) [0|255] "" X
 SG_ VCFRONT_homelinkV2Response2 m2 : 24|8@1+ (1,0) [0|255] "" X
 SG_ VCFRONT_homelinkV2Response3 m2 : 32|8@1+ (1,0) [0|255] "" X
 SG_ VCFRONT_homelinkV2Response4 m2 : 40|8@1+ (1,0) [0|255] "" X
 SG_ VCFRONT_hornOn m0 : 51|1@1+ (1,0) [0|1] "" X
 SG_ VCFRONT_hvacPerfTestCommand m3 : 48|2@1+ (1,0) [0|2] "" X
 SG_ VCFRONT_iBoosterStateDBG m1 : 5|3@1+ (1,0) [0|4] "" X
 SG_ VCFRONT_iBoosterWakeLine m1 : 3|1@1+ (1,0) [0|1] "" X
 SG_ VCFRONT_isActiveHeatingBattery m0 : 63|1@1+ (1,0) [0|1] "" X
 SG_ VCFRONT_isColdStartRunning m3 : 30|1@1+ (1,0) [0|1] "" X
 SG_ VCFRONT_isEvapOperationAllowed m3 : 25|1@1+ (1,0) [0|1] "" X
 SG_ VCFRONT_isHeatPumpOilPurgeActive m3 : 31|1@1+ (1,0) [0|1] "" X
 SG_ VCFRONT_maxEvapHeatRejection m3 : 8|8@1+ (65,0) [0|16575] "W" X
 SG_ VCFRONT_minEvapHeatRejection m3 : 16|8@1+ (10,0) [0|2500] "W" X
 SG_ VCFRONT_pressureRefrigDischarge m3 : 40|8@1+ (0.125,0) [0|31.75] "bar" X
 SG_ VCFRONT_pressureRefrigSuction m3 : 32|7@1+ (0.125,0) [0|11.5] "bar" X
 SG_ VCFRONT_radarHeaterState m0 : 52|3@1+ (1,0) [0|4] "" X
 SG_ VCFRONT_railAState m5 : 7|1@1+ (1,0) [0|1] "" X
 SG_ VCFRONT_railBState m5 : 8|1@1+ (1,0) [0|1] "" X
 SG_ VCFRONT_refrigFillRoutineStatus m3 : 52|2@1+ (1,0) [0|3] ""  Receiver
 SG_ VCFRONT_reverseBatteryFault m4 : 30|1@1+ (1,0) [0|1] "" X
 SG_ VCFRONT_shortedCellFaultCounter m4 : 44|3@1+ (1,0) [0|7] "" X
 SG_ VCFRONT_silentWakeIBSCurrent m4 : 32|12@1- (0.1,-204.7) [-409.5|0] "mA" X
 SG_ VCFRONT_sleepCurrent m1 : 32|12@1- (0.1,-204.7) [-409.5|0] "mA" X
 SG_ VCFRONT_tempCompTargetVoltage m4 : 3|10@1+ (0.01,9) [9|16] "V" X
 SG_ VCFRONT_timeSpentSleeping m1 : 24|8@1+ (1,0) [0|255] "s" X
 SG_ VCFRONT_vbatMonitorVoltage m5 : 16|12@1+ (0.00544368,0) [0|22.2864] "V" X
 SG_ VCFRONT_vbatProt m5 : 40|12@1+ (0.00544368,0) [0|22.2919] "V" X
 SG_ VCFRONT_vehicleStatusDBG m1 : 8|5@1+ (1,0) [0|17] "" X
 SG_ VCFRONT_voltageDropCounter m4 : 20|4@1+ (1,0) [0|15] "" X
 SG_ VCFRONT_voltageFloorReachedCount m4 : 24|4@1+ (1,0) [0|15] "" X
 SG_ VCFRONT_voltageProfile m4 : 28|2@1+ (1,0) [0|3] "" X
 SG_ VCFRONT_wiperPosition m0 : 12|3@1+ (1,0) [0|4] "" X
 SG_ VCFRONT_wiperSpeed m0 : 8|4@1+ (1,0) [0|8] "" X
 SG_ VCFRONT_wiperState m0 : 16|4@1+ (1,0) [0|12] "" X

BO_ 929 VCFRONT_vehicleStatus: 8 VEH
 SG_ VCFRONT_12vStatusForDrive: 14|2@1+ (1,0) [0|0] "" X
 SG_ VCFRONT_2RowCenterUnbuckled: 38|2@1+ (1,0) [0|0] "" X
 SG_ VCFRONT_2RowLeftUnbuckled: 36|2@1+ (1,0) [0|0] "" X
 SG_ VCFRONT_2RowRightUnbuckled: 40|2@1+ (1,0) [0|0] "" X
 SG_ VCFRONT_APGlassHeaterState: 2|3@1+ (1,0) [0|0] "" X
 SG_ VCFRONT_LVLoadRequest: 9|1@1+ (1,0) [0|0] "" X
 SG_ VCFRONT_batterySupportRequest: 27|1@1+ (1,0) [0|0] "" X
 SG_ VCFRONT_bmsHvChargeEnable: 0|1@1+ (1,0) [0|0] "" X
 SG_ VCFRONT_diPowerOnState: 10|3@1+ (1,0) [0|0] "" X
 SG_ VCFRONT_driverBuckleStatus: 30|1@1+ (1,0) [0|0] "" X
 SG_ VCFRONT_driverDoorStatus: 31|1@1+ (1,0) [0|0] "" X
 SG_ VCFRONT_driverIsLeaving: 28|1@1+ (1,0) [0|0] "" X
 SG_ VCFRONT_driverIsLeavingAnySpeed: 13|1@1+ (1,0) [0|0] "" X
 SG_ VCFRONT_driverUnbuckled: 32|2@1+ (1,0) [0|0] "" X
 SG_ VCFRONT_is12VBatterySupported: 5|1@1+ (1,0) [0|0] "" X
 SG_ VCFRONT_ota12VSupportRequest: 29|1@1+ (1,0) [0|0] "" X
 SG_ VCFRONT_passengerUnbuckled: 34|2@1+ (1,0) [0|0] "" X
 SG_ VCFRONT_pcs12vVoltageTarget: 16|11@1+ (0.01,0) [0|0] "V" X
 SG_ VCFRONT_pcsEFuseVoltage: 42|10@1+ (0.1,0) [0|0] "V" X
 SG_ VCFRONT_preconditionRequest: 1|1@1+ (1,0) [0|0] "" X
 SG_ VCFRONT_standbySupplySupported : 6|1@1+ (1,0) [0|1] "" X
 SG_ VCFRONT_thermalSystemType : 5|1@1+ (1,0) [0|1] "" X
 SG_ VCFRONT_vehicleStatusChecksum: 56|8@1+ (1,0) [0|0] "" X
 SG_ VCFRONT_vehicleStatusCounter: 52|4@1+ (1,0) [0|0] "" X

BA_DEF_ BO_ "GenMsgSendType" ENUM "Cyclic";
BA_DEF_ BO_ "GenMsgCycleTime" INT 0 10000;

BA_ "GenMsgSendType" BO_ 273 0;
BA_ "GenMsgCycleTime" BO_ 273 1000;

BA_ "GenMsgSendType" BO_ 799 0;
BA_ "GenMsgCycleTime" BO_ 799 500;

BA_ "GenMsgSendType" BO_ 964 0;
BA_ "GenMsgCycleTime" BO_ 964 1000;

BA_ "GenMsgSendType" BO_ 708 0;
BA_ "GenMsgCycleTime" BO_ 708 1000;

BA_ "GenMsgSendType" BO_ 676 0;
BA_ "GenMsgCycleTime" BO_ 676 1000;

BA_ "GenMsgSendType" BO_ 900 0;
BA_ "GenMsgCycleTime" BO_ 900 1000;

BA_ "GenMsgSendType" BO_ 1748 0;
BA_ "GenMsgCycleTime" BO_ 1748 1000;

BA_ "GenMsgSendType" BO_ 772 0;
BA_ "GenMsgCycleTime" BO_ 772 1000;

BA_ "GenMsgSendType" BO_ 790 0;
BA_ "GenMsgCycleTime" BO_ 790 1000;

BA_ "GenMsgSendType" BO_ 837 0;
BA_ "GenMsgCycleTime" BO_ 837 1000;

BA_ "GenMsgSendType" BO_ 647 0;
BA_ "GenMsgCycleTime" BO_ 647 100;

BA_ "GenMsgSendType" BO_ 1282 0;
BA_ "GenMsgCycleTime" BO_ 1282 1000;

BA_ "GenMsgSendType" BO_ 1329 0;
BA_ "GenMsgCycleTime" BO_ 1329 1000;

BA_ "GenMsgSendType" BO_ 881 0;
BA_ "GenMsgCycleTime" BO_ 881 1000;

BA_ "GenMsgSendType" BO_ 17 0;
BA_ "GenMsgCycleTime" BO_ 17 10;

BA_ "GenMsgSendType" BO_ 257 0;
BA_ "GenMsgCycleTime" BO_ 257 20;

BA_ "GenMsgSendType" BO_ 849 0;
BA_ "GenMsgCycleTime" BO_ 849 10000;

BA_ "GenMsgSendType" BO_ 289 0;
BA_ "GenMsgCycleTime" BO_ 289 10;

BA_ "GenMsgSendType" BO_ 529 0;
BA_ "GenMsgCycleTime" BO_ 529 100;

BA_ "GenMsgSendType" BO_ 1359 0;
BA_ "GenMsgCycleTime" BO_ 1359 100;

BA_ "GenMsgSendType" BO_ 816 0;
BA_ "GenMsgCycleTime" BO_ 816 1000;

BA_ "GenMsgSendType" BO_ 585 0;
BA_ "GenMsgCycleTime" BO_ 585 100;

BA_ "GenMsgSendType" BO_ 297 0;
BA_ "GenMsgCycleTime" BO_ 297 10;

BA_ "GenMsgSendType" BO_ 815 0;
BA_ "GenMsgCycleTime" BO_ 815 1000;

BA_ "GenMsgSendType" BO_ 1355 0;
BA_ "GenMsgCycleTime" BO_ 1355 1000;

BA_ "GenMsgSendType" BO_ 869 0;
BA_ "GenMsgCycleTime" BO_ 869 1000;

BA_ "GenMsgSendType" BO_ 880 0;
BA_ "GenMsgCycleTime" BO_ 880 1000;

BA_ "GenMsgSendType" BO_ 523 0;
BA_ "GenMsgCycleTime" BO_ 523 10;

BA_ "GenMsgSendType" BO_ 1357 0;
BA_ "GenMsgCycleTime" BO_ 1357 1000;

BA_ "GenMsgSendType" BO_ 525 0;
BA_ "GenMsgCycleTime" BO_ 525 10;

BA_ "GenMsgSendType" BO_ 845 0;
BA_ "GenMsgCycleTime" BO_ 845 1000;

BA_ "GenMsgSendType" BO_ 877 0;
BA_ "GenMsgCycleTime" BO_ 877 1000;

BA_ "GenMsgSendType" BO_ 909 0;
BA_ "GenMsgCycleTime" BO_ 909 1000;

BA_ "GenMsgSendType" BO_ 941 0;
BA_ "GenMsgCycleTime" BO_ 941 1000;

BA_ "GenMsgSendType" BO_ 973 0;
BA_ "GenMsgCycleTime" BO_ 973 1000;

BA_ "GenMsgSendType" BO_ 979 0;
BA_ "GenMsgCycleTime" BO_ 979 500;

BA_ "GenMsgSendType" BO_ 291 0;
BA_ "GenMsgCycleTime" BO_ 291 1000;

BA_ "GenMsgSendType" BO_ 819 0;
BA_ "GenMsgCycleTime" BO_ 819 500;

BA_ "GenMsgSendType" BO_ 659 0;
BA_ "GenMsgCycleTime" BO_ 659 500;

BA_ "GenMsgSendType" BO_ 531 0;
BA_ "GenMsgCycleTime" BO_ 531 500;

BA_ "GenMsgSendType" BO_ 664 0;
BA_ "GenMsgCycleTime" BO_ 664 500;

BA_ "GenMsgSendType" BO_ 679 0;
BA_ "GenMsgCycleTime" BO_ 679 500;

BA_ "GenMsgSendType" BO_ 1280 0;
BA_ "GenMsgCycleTime" BO_ 1280 5000;

BA_ "GenMsgSendType" BO_ 1096 0;
BA_ "GenMsgCycleTime" BO_ 1096 1000;

BA_ "GenMsgSendType" BO_ 1016 0;
BA_ "GenMsgCycleTime" BO_ 1016 1000;

BA_ "GenMsgSendType" BO_ 568 0;
BA_ "GenMsgCycleTime" BO_ 568 500;

BA_ "GenMsgSendType" BO_ 536 0;
BA_ "GenMsgCycleTime" BO_ 536 500;

BA_ "GenMsgSendType" BO_ 645 0;
BA_ "GenMsgCycleTime" BO_ 645 500;

BA_ "GenMsgSendType" BO_ 984 0;
BA_ "GenMsgCycleTime" BO_ 984 1000;

BA_ "GenMsgSendType" BO_ 1139 0;
BA_ "GenMsgCycleTime" BO_ 1139 500;

BA_ "GenMsgSendType" BO_ 985 0;
BA_ "GenMsgCycleTime" BO_ 985 1000;

BA_ "GenMsgSendType" BO_ 755 0;
BA_ "GenMsgCycleTime" BO_ 755 500;

BA_ "GenMsgSendType" BO_ 79 0;
BA_ "GenMsgCycleTime" BO_ 79 1000;

BA_ "GenMsgSendType" BO_ 1011 0;
BA_ "GenMsgCycleTime" BO_ 1011 1000;

BA_ "GenMsgSendType" BO_ 787 0;
BA_ "GenMsgCycleTime" BO_ 787 500;

BA_ "GenMsgSendType" BO_ 499 0;
BA_ "GenMsgCycleTime" BO_ 499 1000;

BA_ "GenMsgSendType" BO_ 435 0;
BA_ "GenMsgCycleTime" BO_ 435 1000;

BA_ "GenMsgSendType" BO_ 371 0;
BA_ "GenMsgCycleTime" BO_ 371 1000;

BA_ "GenMsgSendType" BO_ 307 0;
BA_ "GenMsgCycleTime" BO_ 307 1000;

BA_ "GenMsgSendType" BO_ 698 0;
BA_ "GenMsgCycleTime" BO_ 698 500;

BA_ "GenMsgSendType" BO_ 632 0;
BA_ "GenMsgCycleTime" BO_ 632 500;

BA_ "GenMsgSendType" BO_ 723 0;
BA_ "GenMsgCycleTime" BO_ 723 1000;

BA_ "GenMsgSendType" BO_ 1064 0;
BA_ "GenMsgCycleTime" BO_ 1064 1000;

BA_ "GenMsgSendType" BO_ 952 0;
BA_ "GenMsgCycleTime" BO_ 952 1000;

BA_ "GenMsgSendType" BO_ 627 0;
BA_ "GenMsgCycleTime" BO_ 627 500;

BA_ "GenMsgSendType" BO_ 947 0;
BA_ "GenMsgCycleTime" BO_ 947 500;

BA_ "GenMsgSendType" BO_ 644 0;
BA_ "GenMsgCycleTime" BO_ 644 500;

BA_ "GenMsgSendType" BO_ 595 0;
BA_ "GenMsgCycleTime" BO_ 595 500;

BA_ "GenMsgSendType" BO_ 824 0;
BA_ "GenMsgCycleTime" BO_ 824 1000;

BA_ "GenMsgSendType" BO_ 609 0;
BA_ "GenMsgCycleTime" BO_ 609 100;

BA_ "GenMsgSendType" BO_ 545 0;
BA_ "GenMsgCycleTime" BO_ 545 50;

BA_ "GenMsgSendType" BO_ 832 0;
BA_ "GenMsgCycleTime" BO_ 832 100;

BA_ "GenMsgSendType" BO_ 577 0;
BA_ "GenMsgCycleTime" BO_ 577 100;

BA_ "GenMsgSendType" BO_ 753 0;
BA_ "GenMsgCycleTime" BO_ 753 100;

BA_ "GenMsgSendType" BO_ 769 0;
BA_ "GenMsgCycleTime" BO_ 769 1000;

BA_ "GenMsgSendType" BO_ 1009 0;
BA_ "GenMsgCycleTime" BO_ 1009 100;

BA_ "GenMsgSendType" BO_ 705 0;
BA_ "GenMsgCycleTime" BO_ 705 17;

BA_ "GenMsgSendType" BO_ 897 0;
BA_ "GenMsgCycleTime" BO_ 897 250;

BA_ "GenMsgSendType" BO_ 721 0;
BA_ "GenMsgCycleTime" BO_ 721 100;

BA_ "GenMsgSendType" BO_ 801 0;
BA_ "GenMsgCycleTime" BO_ 801 1000;

BA_ "GenMsgSendType" BO_ 737 0;
BA_ "GenMsgCycleTime" BO_ 737 20;

BA_ "GenMsgSendType" BO_ 929 0;
BA_ "GenMsgCycleTime" BO_ 929 100;

VAL_ 964 PCS_infoIndex 0 "DEPRECATED_0" 1 "DEPRECATED_1" 2 "DEPRECATED_2" 3 "DEPRECATED_3" 4 "DEPRECATED_4" 5 "DEPRECATED_5" 6 "DEPRECATED_6" 7 "DEPRECATED_7" 8 "DEPRECATED_8" 9 "DEPRECATED_9" 10 "BUILD_HWID_COMPONENTID" 11 "PCBAID_ASSYID_USAGEID" 13 "APP_CRC" 14 "BOOTLOADER_SVN" 15 "BOOTLOADER_CRC" 16 "SUBCOMPONENT" 17 "APP_GITHASH" 18 "BOOTLOADER_GITHASH" 19 "VERSION_DEPRECATED" 20 "UDS_PROTOCOL_BOOTCRC" 22 "VARIANTCRC" 25 "PACKAGE_PN_1_7" 26 "PACKAGE_PN_8_14" 27 "PACKAGE_PN_15_20" 29 "PACKAGE_SN_1_7" 30 "PACKAGE_SN_8_14" 31 "SUBCOMPONENT_GITHASH" 255 "END";
VAL_ 964 PCS_buildType 0 "UNKNOWN_BUILD" 1 "PLATFORM_BUILD" 2 "LOCAL_BUILD" 3 "TRACEABLE_CI_BUILD" 4 "MFG_BUILD";

VAL_ 708 PCS_logMessageSelect 0 "PHA_1" 1 "PHB_1" 2 "PHC_1" 3 "CHG_1" 4 "CHG_2" 5 "CHG_3" 6 "DCDC_1" 7 "DCDC_2" 8 "DCDC_3" 9 "SYSTEM_1" 10 "PHA_2" 11 "PHB_2" 12 "PHC_2" 13 "CHG_4" 14 "DLOG_1" 15 "DLOG_2" 16 "DLOG_3" 17 "DLOG_4" 18 "DCDC_4" 19 "DCDC_5" 20 "CHG_NO_FLOW" 21 "CHG_LINE_OFFSET" 22 "DCDC_STATISTICS" 23 "CHG_STATISTICS" 24 "NUM_MSGS";
VAL_ 708 PCS_chgInputFrequencyL1N 0 "FREQUENCY_UNKNOWN";
VAL_ 708 PCS_chgInputFrequencyL2N 0 "FREQUENCY_UNKNOWN";
VAL_ 708 PCS_chgInputFrequencyL3N 0 "FREQUENCY_UNKNOWN";
VAL_ 708 PCS_chgInternalPhaseConfig 0 "SNA" 1 "SINGLE_PHASE" 2 "THREE_PHASE" 3 "THREE_PHASE_DELTA" 4 "SINGLE_PHASE_IEC_GB" 5 "MFG_TEST_CONFIG_1" 6 "MFG_TEST_CONFIG_2" 7 "TOTAL_NUM";
VAL_ 708 PCS_chgPhAState 0 "INIT" 1 "IDLE" 2 "PRECHARGE" 3 "ENABLE" 4 "FAULT" 5 "CLEAR_FAULTS" 6 "SHUTTING_DOWN";
VAL_ 708 PCS_chgPhBState 0 "INIT" 1 "IDLE" 2 "PRECHARGE" 3 "ENABLE" 4 "FAULT" 5 "CLEAR_FAULTS" 6 "SHUTTING_DOWN";
VAL_ 708 PCS_chgPhCState 0 "INIT" 1 "IDLE" 2 "PRECHARGE" 3 "ENABLE" 4 "FAULT" 5 "CLEAR_FAULTS" 6 "SHUTTING_DOWN";
VAL_ 708 PCS_chgPhALastShutdownReason 0 "REASON_NONE" 1 "SW_ENABLE" 2 "HW_ENABLE" 3 "SW_FAULT" 4 "HW_FAULT" 5 "PLL_NOT_LOCKED" 6 "INPUT_UV" 7 "INPUT_OV" 8 "OUTPUT_UV" 9 "OUTPUT_OV" 10 "PRECHARGE_TIMEOUT" 11 "INT_BUS_UV" 12 "CONTROL_REGULATION_FAULT" 13 "OVER_TEMPERATURE" 14 "TEMP_IRRATIONAL" 15 "SENSOR_IRRATIONAL" 16 "FREQ_OUT_OF_RANGE" 17 "LINE_TRANSIENT_FAULT";
VAL_ 708 PCS_chgPhBLastShutdownReason 0 "REASON_NONE" 1 "SW_ENABLE" 2 "HW_ENABLE" 3 "SW_FAULT" 4 "HW_FAULT" 5 "PLL_NOT_LOCKED" 6 "INPUT_UV" 7 "INPUT_OV" 8 "OUTPUT_UV" 9 "OUTPUT_OV" 10 "PRECHARGE_TIMEOUT" 11 "INT_BUS_UV" 12 "CONTROL_REGULATION_FAULT" 13 "OVER_TEMPERATURE" 14 "TEMP_IRRATIONAL" 15 "SENSOR_IRRATIONAL" 16 "FREQ_OUT_OF_RANGE" 17 "LINE_TRANSIENT_FAULT";
VAL_ 708 PCS_chgPhCLastShutdownReason 0 "REASON_NONE" 1 "SW_ENABLE" 2 "HW_ENABLE" 3 "SW_FAULT" 4 "HW_FAULT" 5 "PLL_NOT_LOCKED" 6 "INPUT_UV" 7 "INPUT_OV" 8 "OUTPUT_UV" 9 "OUTPUT_OV" 10 "PRECHARGE_TIMEOUT" 11 "INT_BUS_UV" 12 "CONTROL_REGULATION_FAULT" 13 "OVER_TEMPERATURE" 14 "TEMP_IRRATIONAL" 15 "SENSOR_IRRATIONAL" 16 "FREQ_OUT_OF_RANGE" 17 "LINE_TRANSIENT_FAULT";
VAL_ 708 PCS_dcdcTankVoltage -1024 "TANK_VOLTAGE_SNA";
VAL_ 708 PCS_cpu2BootState 0 "BOOTROM" 1 "BOOTLOADER" 2 "APPLICATION" 3 "ERROR";
VAL_ 708 PCS_acChargeSelfTestState 0 "IDLE" 1 "STARTED";
VAL_ 708 PCS_chgInputFreqWobblePHAPeak 0 "FREQUENCY_UNKNOWN";
VAL_ 708 PCS_chgInputFreqWobblePHBPeak 0 "FREQUENCY_UNKNOWN";
VAL_ 708 PCS_chgInputFreqWobblePHCPeak 0 "FREQUENCY_UNKNOWN";
VAL_ 708 PCS_dLogPhAChannel1Content 0 "INPUT_VOLTAGE" 1 "INPUT_CURRENT" 2 "OUTPUT_CURRENT" 3 "INT_BUS_VOLTAGE";
VAL_ 708 PCS_dLogPhBChannel1Content 0 "INPUT_VOLTAGE" 1 "INPUT_CURRENT" 2 "OUTPUT_CURRENT" 3 "INT_BUS_VOLTAGE";
VAL_ 708 PCS_dLogPhCChannel1Content 0 "INPUT_VOLTAGE" 1 "INPUT_CURRENT" 2 "OUTPUT_CURRENT" 3 "INT_BUS_VOLTAGE";
VAL_ 708 PCS_dLogPhAChannel2Content 0 "INPUT_VOLTAGE" 1 "INPUT_CURRENT" 2 "OUTPUT_CURRENT" 3 "INT_BUS_VOLTAGE";
VAL_ 708 PCS_dLogPhBChannel2Content 0 "INPUT_VOLTAGE" 1 "INPUT_CURRENT" 2 "OUTPUT_CURRENT" 3 "INT_BUS_VOLTAGE";
VAL_ 708 PCS_dLogPhCChannel2Content 0 "INPUT_VOLTAGE" 1 "INPUT_CURRENT" 2 "OUTPUT_CURRENT" 3 "INT_BUS_VOLTAGE";
VAL_ 708 PCS_dLogPhAChannel3Content 0 "INPUT_VOLTAGE" 1 "INPUT_CURRENT" 2 "OUTPUT_CURRENT" 3 "INT_BUS_VOLTAGE";
VAL_ 708 PCS_dLogPhBChannel3Content 0 "INPUT_VOLTAGE" 1 "INPUT_CURRENT" 2 "OUTPUT_CURRENT" 3 "INT_BUS_VOLTAGE";
VAL_ 708 PCS_dLogPhCChannel3Content 0 "INPUT_VOLTAGE" 1 "INPUT_CURRENT" 2 "OUTPUT_CURRENT" 3 "INT_BUS_VOLTAGE";
VAL_ 708 PCS_dLogPhAChannel4Content 0 "INPUT_VOLTAGE" 1 "INPUT_CURRENT" 2 "OUTPUT_CURRENT" 3 "INT_BUS_VOLTAGE";
VAL_ 708 PCS_dLogPhBChannel4Content 0 "INPUT_VOLTAGE" 1 "INPUT_CURRENT" 2 "OUTPUT_CURRENT" 3 "INT_BUS_VOLTAGE";
VAL_ 708 PCS_dLogPhCChannel4Content 0 "INPUT_VOLTAGE" 1 "INPUT_CURRENT" 2 "OUTPUT_CURRENT" 3 "INT_BUS_VOLTAGE";

VAL_ 676 PCS_ambientTemp 1023 "TEMPERATURE_SNA";
VAL_ 676 PCS_chgPhATemp 1023 "TEMPERATURE_SNA";
VAL_ 676 PCS_chgPhBTemp 1023 "TEMPERATURE_SNA";
VAL_ 676 PCS_chgPhCTemp 1023 "TEMPERATURE_SNA";
VAL_ 676 PCS_dcdcTemp 1023 "TEMPERATURE_SNA";

VAL_ 1748 PMS_infoIndex 0 "DEPRECATED_0" 1 "DEPRECATED_1" 2 "DEPRECATED_2" 3 "DEPRECATED_3" 4 "DEPRECATED_4" 5 "DEPRECATED_5" 6 "DEPRECATED_6" 7 "DEPRECATED_7" 8 "DEPRECATED_8" 9 "DEPRECATED_9" 10 "BUILD_HWID_COMPONENTID" 11 "PCBAID_ASSYID_USAGEID" 13 "APP_CRC" 14 "BOOTLOADER_SVN" 15 "BOOTLOADER_CRC" 16 "SUBCOMPONENT" 17 "APP_GITHASH" 18 "BOOTLOADER_GITHASH" 19 "VERSION_DEPRECATED" 20 "UDS_PROTOCOL_BOOTCRC" 22 "VARIANTCRC" 25 "PACKAGE_PN_1_7" 26 "PACKAGE_PN_8_14" 27 "PACKAGE_PN_15_20" 29 "PACKAGE_SN_1_7" 30 "PACKAGE_SN_8_14" 31 "SUBCOMPONENT_GITHASH" 255 "END";
VAL_ 1748 PMS_buildType 0 "UNKNOWN_BUILD" 1 "PLATFORM_BUILD" 2 "LOCAL_BUILD" 3 "TRACEABLE_CI_BUILD" 4 "MFG_BUILD";
VAL_ 1748 PMS_hardwareId 252 "CONFIGURABLE_HWID_PLACEHOLDER";

VAL_ 790 PM_infoIndex 0 "DEPRECATED_0" 1 "DEPRECATED_1" 2 "DEPRECATED_2" 3 "DEPRECATED_3" 4 "DEPRECATED_4" 5 "DEPRECATED_5" 6 "DEPRECATED_6" 7 "DEPRECATED_7" 8 "DEPRECATED_8" 9 "DEPRECATED_9" 10 "BUILD_HWID_COMPONENTID" 11 "PCBAID_ASSYID_USAGEID" 13 "APP_CRC" 14 "BOOTLOADER_SVN" 15 "BOOTLOADER_CRC" 16 "SUBCOMPONENT" 17 "APP_GITHASH" 18 "BOOTLOADER_GITHASH" 19 "VERSION_DEPRECATED" 20 "UDS_PROTOCOL_BOOTCRC" 22 "VARIANTCRC" 25 "PACKAGE_PN_1_7" 26 "PACKAGE_PN_8_14" 27 "PACKAGE_PN_15_20" 29 "PACKAGE_SN_1_7" 30 "PACKAGE_SN_8_14" 31 "SUBCOMPONENT_GITHASH" 255 "END";
VAL_ 790 PM_buildType 0 "UNKNOWN_BUILD" 1 "PLATFORM_BUILD" 2 "LOCAL_BUILD" 3 "TRACEABLE_CI_BUILD" 4 "MFG_BUILD";
VAL_ 790 PM_hardwareId 252 "CONFIGURABLE_HWID_PLACEHOLDER";

VAL_ 837 PTC_infoIndex 0 "DEPRECATED_0" 1 "DEPRECATED_1" 2 "DEPRECATED_2" 3 "DEPRECATED_3" 4 "DEPRECATED_4" 5 "DEPRECATED_5" 6 "DEPRECATED_6" 7 "DEPRECATED_7" 8 "DEPRECATED_8" 9 "DEPRECATED_9" 10 "BUILD_HWID_COMPONENTID" 11 "PCBAID_ASSYID_USAGEID" 13 "APP_CRC" 14 "BOOTLOADER_SVN" 15 "BOOTLOADER_CRC" 16 "SUBCOMPONENT" 17 "APP_GITHASH" 18 "BOOTLOADER_GITHASH" 19 "VERSION_DEPRECATED" 20 "UDS_PROTOCOL_BOOTCRC" 22 "VARIANTCRC" 25 "PACKAGE_PN_1_7" 26 "PACKAGE_PN_8_14" 27 "PACKAGE_PN_15_20" 29 "PACKAGE_SN_1_7" 30 "PACKAGE_SN_8_14" 31 "SUBCOMPONENT_GITHASH" 255 "END";
VAL_ 837 PTC_infoBuildType 0 "UNKNOWN_BUILD" 1 "PLATFORM_BUILD" 2 "LOCAL_BUILD" 3 "TRACEABLE_CI_BUILD" 4 "MFG_BUILD";
VAL_ 837 PTC_infoAssemblyId 1 "ASSEMBLY1" 255 "ASSEMBLY_SNA";

VAL_ 1329 RADC_infoIndex 10 "Mux10" 11 "Mux11" 13 "Mux13" 19 "Mux19" 20 "Mux20";
VAL_ 1329 RADC_infoBuildType 0 "UNKNOWN_BUILD" 1 "PLATFORM_BUILD" 2 "LOCAL_BUILD" 3 "TRACEABLE_CI_BUILD" 4 "MFG_BUILD";

VAL_ 881 RCM_matrixIndex 0 "AlertMatrix0" 1 "AlertMatrix1";

VAL_ 17 RCM_collisionFront 0 "INACTIVE" 1 "ACTIVE" 3 "SNA";
VAL_ 17 RCM_collisionLeft 0 "INACTIVE" 1 "ACTIVE" 3 "SNA";
VAL_ 17 RCM_collisionRear 0 "INACTIVE" 1 "ACTIVE" 3 "SNA";
VAL_ 17 RCM_collisionRight 0 "INACTIVE" 1 "ACTIVE" 3 "SNA";
VAL_ 17 RCM_collisionRollover 0 "INACTIVE" 1 "ACTIVE" 3 "SNA";
VAL_ 17 RCM_collisionSeverity 0 "PRETENSIONER" 1 "FIRST_STAGE" 2 "SECOND_STAGE" 3 "PEDPRO_EVENT";

VAL_ 257 RCM_pitchRate -16384 "SNA";
VAL_ 257 RCM_pitchRateQF 0 "INIT" 1 "VALID" 2 "TEMP_INVALID" 3 "FAULTED";
VAL_ 257 RCM_rollRate -16384 "SNA";
VAL_ 257 RCM_rollRateQF 0 "INIT" 1 "VALID" 2 "TEMP_INVALID" 3 "FAULTED";
VAL_ 257 RCM_yawRate -32768 "SNA";
VAL_ 257 RCM_yawRateQF 0 "FAULTED" 1 "NOT_FAULTED";
VAL_ 273 RCM_lateralAccel -32768 "SNA" ;
VAL_ 273 RCM_lateralAccelQF 0 "FAULTED" 1 "NOT_FAULTED" ;
VAL_ 273 RCM_longitudinalAccel -32768 "SNA" ;
VAL_ 273 RCM_longitudinalAccelQF 0 "FAULTED" 1 "NOT_FAULTED" ;
VAL_ 273 RCM_verticalAccel -32768 "SNA" ;
VAL_ 273 RCM_verticalAccelQF 0 "FAULTED" 1 "NOT_FAULTED" ;

VAL_ 849 RCM_infoIndex 0 "DEPRECATED_0" 1 "DEPRECATED_1" 2 "DEPRECATED_2" 3 "DEPRECATED_3" 4 "DEPRECATED_4" 5 "DEPRECATED_5" 6 "DEPRECATED_6" 7 "DEPRECATED_7" 8 "DEPRECATED_8" 9 "DEPRECATED_9" 10 "BUILD_HWID_COMPONENTID" 11 "PCBAID_ASSYID_USAGEID" 13 "APP_CRC" 14 "BOOTLOADER_SVN" 15 "BOOTLOADER_CRC" 16 "SUBCOMPONENT" 17 "APP_GITHASH" 18 "BOOTLOADER_GITHASH" 19 "VERSION_DEPRECATED" 20 "UDS_PROTOCOL_BOOTCRC" 22 "VARIANTCRC" 25 "PACKAGE_PN_1_7" 26 "PACKAGE_PN_8_14" 27 "PACKAGE_PN_15_20" 29 "PACKAGE_SN_1_7" 30 "PACKAGE_SN_8_14" 31 "SUBCOMPONENT_GITHASH" 255 "END";
VAL_ 849 RCM_infoBuildType 0 "UNKNOWN_BUILD" 1 "PLATFORM_BUILD" 2 "LOCAL_BUILD" 3 "TRACEABLE_CI_BUILD" 4 "MFG_BUILD";

VAL_ 289 RCM_crashAlgoWakeup 0 "INACTIVE" 1 "ACTIVE" 3 "SNA";
VAL_ 289 RCM_nearDeployFront 0 "INACTIVE" 1 "ACTIVE" 3 "SNA";
VAL_ 289 RCM_nearDeployLeft 0 "INACTIVE" 1 "ACTIVE" 3 "SNA";
VAL_ 289 RCM_nearDeployRear 0 "INACTIVE" 1 "ACTIVE" 3 "SNA";
VAL_ 289 RCM_nearDeployRight 0 "INACTIVE" 1 "ACTIVE" 3 "SNA";
VAL_ 289 RCM_nearDeployRollover 0 "INACTIVE" 1 "ACTIVE" 3 "SNA";

VAL_ 529 RCM_airbagCutoffStatus 0 "RCM_PASSENGER_AIRBAG_ENABLED" 1 "RCM_PASSENGER_AIRBAG_DISABLED" 3 "SNA";
VAL_ 529 RCM_alrSwitchStatus 0 "RCM_ALR_NOT_ENGAGED" 1 "RCM_ALR_ENGAGED" 2 "RCM_ALR_FAULTED" 3 "SNA";
VAL_ 529 RCM_armStatus 0 "RCM_UNARMED" 1 "RCM_ARMED" 2 "ARMED_WITH_NOFIRE_CAL" 3 "SNA";
VAL_ 529 RCM_driverOrientationInitStatus 0 "RCM_DRIVER_ORIENTATION_INIT_NOT_COMPLETE" 1 "RCM_DRIVER_ORIENTATION_MATCHED_LHD" 2 "RCM_DRIVER_ORIENTATION_MATCHED_RHD" 3 "RCM_DRIVER_ORIENTATION_MISMATCH_DEFAULT_LHD" 4 "RCM_DRIVER_ORIENTATION_MISMATCH_DEFAULT_RHD" 7 "SNA";
VAL_ 529 RCM_edr1State 0 "EMPTY" 1 "STORED" 2 "LOCKED" 3 "UNAVAILABLE";
VAL_ 529 RCM_edr2State 0 "EMPTY" 1 "STORED" 2 "LOCKED" 3 "UNAVAILABLE";
VAL_ 529 RCM_imuOffsetLearnState 0 "OFFSET_LEARNING_OFF" 1 "SLOW_LEARNING_DISTANCE" 2 "FAST_LEARNING_TIME" 3 "OFFSETS_UNABLE_TO_LEARN";
VAL_ 529 RCM_keepPowerReason 0 "NO_KEEP_POWER_REQUEST" 1 "IN_IDLE_MODE" 2 "CRASH_ALGO_ACTIVE" 3 "EDR_STORING_TO_EEPROM" 4 "EDR_UPLOADING" 5 "CANNOT_POWER_DOWN" 6 "INITIALIZATION_PHASE" 7 "INVALID_POWER_OFF_REQUEST";
VAL_ 529 RCM_passAirbagIndicatorRequest 0 "RCM_PASSENGER_AIRBAG_INDICATOR_ON" 1 "RCM_PASSENGER_AIRBAG_INDICATOR_OFF" 3 "SNA";
VAL_ 529 RCM_seatTrackPositionDrvr 0 "RCM_SEAT_POSITION_NEAR" 1 "RCM_SEAT_POSITION_FAR" 2 "RCM_SEAT_POSITION_FAULTED" 3 "SNA";
VAL_ 529 RCM_seatTrackPositionPass 0 "RCM_SEAT_POSITION_NEAR" 1 "RCM_SEAT_POSITION_FAR" 2 "RCM_SEAT_POSITION_FAULTED" 3 "SNA";
VAL_ 529 RCM_vinLearnFlag 0 "RCM_VIN_NOT_STORED" 1 "RCM_VIN_STORED" 2 "RCM_VIN_STORED_MISMATCH" 3 "SNA";
VAL_ 529 RCM_warningIndicatorState 0 "RCM_WARNING_INDICATOR_OFF" 1 "RCM_WARNING_INDICATOR_ON" 3 "SNA";

VAL_ 1359 SCCM_matrixIndex 0 "SCCM_AlertMatrix0";

VAL_ 816 SCCM_infoIndex 10 "BUILD_HWID_COMPONENTID" 11 "PCBAID_ASSYID_USAGEID" 13 "APP_CRC" 14 "BOOTLOADER_SVN" 16 "SUBCOMPONENT1" 17 "APP_SVNHASH" 18 "BOOTLOADER_SVNHASH" 20 "UDS_PROTOCOL_BOOTCRC" 255 "END";
VAL_ 816 SCCM_infoBuildType 0 "UNKNOWN_BUILD" 1 "PLATFORM_BUILD" 2 "LOCAL_BUILD" 3 "TRACEABLE_CI_BUILD" 4 "MFG_BUILD";

VAL_ 585 SCCM_highBeamStalkStatus 0 "IDLE" 1 "PULL" 2 "PUSH" 3 "SNA";
VAL_ 585 SCCM_turnIndicatorStalkStatus 0 "IDLE" 2 "UP_1" 4 "UP_2" 7 "DOWN_1" 8 "DOWN_2" 5 "SNA";
VAL_ 585 SCCM_washWipeButtonStatus 0 "NOT_PRESSED" 1 "1ST_DETENT" 2 "2ND_DETENT" 3 "SNA";

VAL_ 297 SCCM_steeringAngleSensorStatus 0 "OK" 1 "INIT" 2 "ERROR" 3 "ERROR_INIT";
VAL_ 297 SCCM_steeringAngleValidity 0 "INVALID" 1 "VALID" 2 "INIT" 3 "SNA";

VAL_ 1357 TAS_infoIndex 0 "DEPRECATED_0" 1 "DEPRECATED_1" 2 "DEPRECATED_2" 3 "DEPRECATED_3" 4 "DEPRECATED_4" 5 "DEPRECATED_5" 6 "DEPRECATED_6" 7 "DEPRECATED_7" 8 "DEPRECATED_8" 9 "DEPRECATED_9" 10 "BUILD_HWID_COMPONENTID" 11 "PCBAID_ASSYID_USAGEID" 13 "APP_CRC" 14 "BOOTLOADER_SVN" 15 "BOOTLOADER_CRC" 16 "SUBCOMPONENT1" 17 "APP_GITHASH" 18 "BOOTLOADER_GITHASH" 19 "VERSION_DEPRECATED" 20 "UDS_PROTOCOL_BOOTCRC" 23 "SUBCOMPONENT2" 24 "SUBCOMPONENT3" 31 "SUBCOMPONENT4" 255 "END";
VAL_ 1357 TAS_infoBuildType 0 "UNKNOWN_BUILD" 1 "PLATFORM_BUILD" 2 "LOCAL_BUILD" 3 "TRACEABLE_CI_BUILD" 4 "MFG_BUILD";
VAL_ 1357 TAS_infoAssemblyId 1 "ASSEMBLY1" 255 "ASSEMBLY_SNA";
VAL_ 1357 TAS_infoMajorVersion 254 "LOCAL_BUILD" 255 "SNA";
VAL_ 1357 TAS_infoBranchOrigin 254 "LOCAL_BUILD" 255 "SNA";
VAL_ 1357 TAS_infoMaturity 254 "LOCAL_BUILD" 255 "SNA";
VAL_ 1357 TAS_infoHardwareRevision 254 "LOCAL_BUILD" 255 "SNA";

VAL_ 525 TAS_currentLevel 0 "VERY_HIGH" 1 "HIGH" 2 "STANDARD" 3 "LOW" 4 "VERY_LOW";
VAL_ 525 TAS_filterMode 0 "NONE" 1 "INIT" 2 "CALIBRATE" 3 "TEST" 4 "READY" 5 "LOADING" 6 "DRIVE" 7 "STOPPING";
VAL_ 525 TAS_levelingState 0 "IDLE" 1 "READ_P_RESERVOIR" 2 "MANUAL_SPRING_CONTROL" 3 "EXHAUST_GALLERY" 4 "COMPRESSOR_RAMPUP" 5 "COMPRESSOR_PREFILL_GALLERY" 6 "FILL_RESERVOIR_FROM_COMPRESSOR" 7 "FILL_SPRING_FROM_COMPRESSOR" 8 "FILL_SPRING_FROM_BOOST" 9 "FILL_SPRING_FROM_RESERVOIR" 10 "FILL_SPRING_RESERVOIR_FROM_COMPRESSOR" 11 "LOWER_SPRING" 12 "EMPTY_RESERVOIR";
VAL_ 525 TAS_limpHomeMode 0 "0" 1 "10" 2 "20" 3 "30" 4 "40";
VAL_ 525 TAS_runMode 0 "INIT" 1 "SYSTEM_CHECK" 2 "SERVICE" 3 "ASSEMBLY" 4 "DAN" 5 "NORMAL" 6 "LOW_POWER";
VAL_ 525 TAS_targetLevel 0 "VERY_HIGH" 1 "HIGH" 2 "STANDARD" 3 "LOW" 4 "VERY_LOW";

VAL_ 879 TPMS_learningStatus 0 "FAILED" 1 "ONGOING" 2 "STOPPED" 3 "PASSED";
VAL_ 879 TPMS_localisationStatus 0 "FAILED" 1 "ONGOING" 2 "STOPPED" 3 "PASSED";

VAL_ 799 TPMS_pressureFL 255 "SNA";
VAL_ 799 TPMS_pressureFR 255 "SNA";
VAL_ 799 TPMS_pressureRL 255 "SNA";
VAL_ 799 TPMS_pressureRR 255 "SNA";
VAL_ 799 TPMS_temperatureFL 255 "SNA";
VAL_ 799 TPMS_temperatureFR 255 "SNA";
VAL_ 799 TPMS_temperatureRL 255 "SNA";
VAL_ 799 TPMS_temperatureRR 255 "SNA";

VAL_ 1519 TPMS_infoIndex 0 "DEPRECATED_0" 1 "DEPRECATED_1" 2 "DEPRECATED_2" 3 "DEPRECATED_3" 4 "DEPRECATED_4" 5 "DEPRECATED_5" 6 "DEPRECATED_6" 7 "DEPRECATED_7" 8 "DEPRECATED_8" 9 "DEPRECATED_9" 10 "BUILD_HWID_COMPONENTID" 11 "PCBAID_ASSYID_USAGEID" 13 "APP_CRC" 14 "BOOTLOADER_SVN" 15 "BOOTLOADER_CRC" 16 "SUBCOMPONENT" 17 "APP_GITHASH" 18 "BOOTLOADER_GITHASH" 19 "VERSION_DEPRECATED" 20 "UDS_PROTOCOL_BOOTCRC" 22 "VARIANTCRC" 25 "PACKAGE_PN_1_7" 26 "PACKAGE_PN_8_14" 27 "PACKAGE_PN_15_20" 29 "PACKAGE_SN_1_7" 30 "PACKAGE_SN_8_14" 31 "SUBCOMPONENT_GITHASH" 255 "END";

VAL_ 979 UI_airbagCutoffSwState 0 "PASSENGER_AIRBAG_ON" 1 "PASSENGER_AIRBAG_OFF" 2 "SNA";
VAL_ 979 UI_warningIndicatorStatus 0 "WARNING_LAMP_OFF" 1 "WARNING_LAMP_ON" 3 "SNA";

VAL_ 1523 UI_alertID 0 "ALERT_DO_NOT_USE_ZERO" 1 "a001_DriverDoorOpen" 2 "a002_DoorOpen" 3 "a003_TrunkOpen" 4 "a004_FrunkOpen" 5 "a005_HeadlightsOnDoorOpen" 6 "a006_RemoteServiceAlert" 7 "a007_SoftPackConfigMismatch" 8 "a008_TouchScreenError" 9 "a009_SquashfsError" 10 "a010_MapsMissing" 11 "a011_IncorrectMap" 12 "a012_NotOnPrivateProperty" 13 "a013_TPMSHardWarning" 14 "a014_TPMSSoftWarning" 15 "a015_TPMSOverPressureWarning" 16 "a016_TPMSTemperatureWarning" 17 "a017_TPMSSystemFault" 18 "a018_SlipStartOn" 19 "a019_ParkBrakeFault" 20 "a020_SteeringReduced" 21 "a021_RearSeatbeltUnbuckled" 22 "a022_ApeFusesEtc" 23 "a023_CellInternetCheckFailed" 24 "a024_WifiInternetCheckFailed" 25 "a025_WifiOnlineCheckFailed" 26 "a026_ModemResetLoopDetected" 27 "a027_AutoSteerMIA" 28 "a028_FrontTrunkPopupClosed" 29 "a029_ModemMIA" 30 "a030_ModemVMCrash" 31 "a031_BrakeFluidLow" 32 "a032_CellModemRecoveryResets" 33 "a033_ApTrialExpired" 34 "a034_WakeupProblem" 35 "a035_AudioWatchdogKernelError" 36 "a036_AudioWatchdogHfpError" 37 "a037_AudioWatchdogXrunStormError" 38 "a038_AudioWatchdogA2bI2cLockupError" 39 "a039_AudioA2bNeedRediscovery" 40 "a040_HomelinkTransmit" 41 "a041_AudioDmesgXrun" 42 "a042_AudioDmesgRtThrottling" 43 "a043_InvalidMapDataOverride" 44 "a044_AudioDmesgDspException";
VAL_ 1523 UI_alertState 0 "CLEARED" 1 "SET";

VAL_ 1021 UI_autopilotControlIndex 0 "0" 1 "1" 2 "2" 3 "3" 4 "4" 5 "5" 6 "6" 7 "7";
VAL_ 1021 UI_hovEnabled 0 "OFF" 1 "ON";
VAL_ 1021 UI_donDisableAutoWiperDuration 0 "DEFAULT" 1 "5_S" 2 "15_S" 3 "30_S" 4 "60_S" 5 "120_S" 6 "OFF";
VAL_ 1021 UI_donDisableOnAutoWiperSpeed 0 "OFF" 1 "1" 2 "2" 3 "3" 4 "4" 5 "5" 6 "6" 7 "7" 8 "8" 9 "9" 10 "10" 11 "11" 12 "12" 13 "13" 14 "14" 15 "INVALID";
VAL_ 1021 UI_blindspotMinSpeed 0 "DEFAULT" 1 "5_KPH" 2 "10_KPH" 3 "15_KPH" 4 "20_KPH" 5 "25_KPH" 6 "30_KPH" 7 "35_KPH" 8 "40_KPH" 9 "45_KPH" 10 "OFF";
VAL_ 1021 UI_blindspotDistance 0 "DEFAULT" 1 "0P5_M" 2 "1_M" 3 "2_M" 4 "4_M" 5 "OFF";
VAL_ 1021 UI_blindspotTTC 0 "DEFAULT" 1 "0P5_S" 2 "1_S" 3 "2_S" 4 "4_S" 5 "3_S" 6 "5_S" 7 "OFF";
VAL_ 1021 UI_donStopEndOfRampBuffer 0 "DEFAULT" 1 "15_M" 2 "30_M" 3 "45_M" 4 "OFF";
VAL_ 1021 UI_donDisableCutin 0 "OFF" 1 "ON";
VAL_ 1021 UI_donMinGoreWidthForAbortMap 0 "DEFAULT" 1 "0_M" 2 "0P5_M" 3 "1_M" 4 "1P5_M" 5 "2_M" 6 "2P5_M" 7 "3_M" 8 "3P5_M" 9 "4_M" 10 "4P5_M" 11 "5_M";
VAL_ 1021 UI_donAlcProgGoreAbortThres 0 "DEFAULT" 1 "0P00" 2 "0P05" 3 "0P10" 4 "0P15" 5 "0P20" 6 "0P25" 7 "0P30" 8 "0P35" 9 "0P40";
VAL_ 1021 UI_donMinGoreWidthForAbortNotMap 0 "DEFAULT" 1 "0_M" 2 "0P5_M" 3 "1_M" 4 "1P5_M" 5 "2_M" 6 "2P5_M" 7 "3_M" 8 "3P5_M" 9 "4_M" 10 "4P5_M" 11 "5_M";

VAL_ 819 UI_acChargeCurrentLimit 127 "SNA";

VAL_ 659 UI_accOvertakeEnable 0 "ACC_OVERTAKE_OFF" 1 "ACC_OVERTAKE_ON" 3 "SNA";
VAL_ 659 UI_aebEnable 0 "AEB_OFF" 1 "AEB_ON" 3 "SNA";
VAL_ 659 UI_aesEnable 0 "AES_OFF" 1 "AES_ON" 3 "SNA";
VAL_ 659 UI_ahlbEnable 0 "AHLB_OFF" 1 "AHLB_ON" 3 "SNA";
VAL_ 659 UI_autoLaneChangeEnable 0 "OFF" 1 "ON" 3 "SNA";
VAL_ 659 UI_autoParkRequest 0 "NONE" 1 "PARK_LEFT_PARALLEL" 2 "PARK_LEFT_CROSS" 3 "PARK_RIGHT_PARALLEL" 4 "PARK_RIGHT_CROSS" 5 "PARALLEL_PULL_OUT_TO_LEFT" 6 "PARALLEL_PULL_OUT_TO_RIGHT" 7 "ABORT" 8 "COMPLETE" 9 "SEARCH" 10 "PAUSE" 11 "RESUME" 15 "SNA";
VAL_ 659 UI_bsdEnable 0 "BSD_OFF" 1 "BSD_ON" 3 "SNA";
VAL_ 659 UI_distanceUnits 0 "KM" 1 "MILES";
VAL_ 659 UI_fcwEnable 0 "FCW_OFF" 1 "FCW_ON" 3 "SNA";
VAL_ 659 UI_fcwSensitivity 0 "AEB_SENSITIVITY_EARLY" 1 "AEB_SENSITIVITY_AVERAGE" 2 "AEB_SENSITIVITY_LATE" 3 "SNA";
VAL_ 659 UI_latControlEnable 0 "OFF" 1 "ON" 2 "UNAVAILABLE" 3 "SNA";
VAL_ 659 UI_ldwEnable 0 "NO_HAPTIC" 1 "LDW_TRIGGERS_HAPTIC" 3 "SNA";
VAL_ 659 UI_parkBrakeRequest 0 "IDLE" 1 "PRESSED" 3 "SNA";
VAL_ 659 UI_pedalSafetyEnable 0 "PEDAL_SAFETY_OFF" 1 "PEDAL_SAFETY_ON" 3 "SNA";
VAL_ 659 UI_redLightStopSignEnable 0 "RLSSW_OFF" 1 "RLSSW_ON" 3 "SNA";
VAL_ 659 UI_selfParkTune 15 "SNA";
VAL_ 659 UI_steeringTuneRequest 0 "COMFORT" 1 "STANDARD" 2 "SPORT";
VAL_ 659 UI_suspensionLevelRequest 0 "NO_CHANGE_SNA" 1 "REQUEST_LOW_LEVEL" 2 "REQUEST_NORMAL_LEVEL" 3 "REQUEST_HIGH_LEVEL" 4 "REQUEST_VERY_HIGH_LEVEL" 5 "TOGGLE_JACK_MODE" 6 "SWITCH_DEFECT" 7 "REQUEST_VERY_LOW_LEVEL";
VAL_ 659 UI_tractionControlMode 0 "NORMAL_SELECTED" 1 "SLIP_START_SELECTED" 2 "DEV_MODE_1_SELECTED" 3 "DEV_MODE_2_SELECTED" 4 "ROLLS_MODE_SELECTED" 5 "DYNO_MODE_SELECTED";
VAL_ 659 UI_trailerMode 0 "OFF" 1 "ON";
VAL_ 659 UI_winchModeRequest 0 "IDLE" 1 "ENTER" 2 "EXIT";
VAL_ 659 UI_zeroSpeedConfirmed 0 "CANCELED" 1 "CONFIRMED" 2 "UNUSED" 3 "SNA";

VAL_ 531 UI_cruiseSpeedCommand 0 "IDLE" 1 "INC_SHORT" 2 "INC_LONG" 3 "DEC_SHORT" 4 "DEC_LONG" 5 "SNAP";
VAL_ 531 UI_speedLimitTick 255 "SNA";

VAL_ 1280 UI_debugEcuTarget 1 "DI" 2 "DIS" 3 "PM" 4 "PMS" 5 "BMS" 6 "VCRIGHT" 7 "VCFRONT";

VAL_ 1096 UI_anonDebugFlag1 0 "OFF" 1 "ON";
VAL_ 1096 UI_anonDebugFlag2 0 "OFF" 1 "ON";
VAL_ 1096 UI_anonDebugFlag3 0 "OFF" 1 "ON";
VAL_ 1096 UI_anonDebugFlag4 0 "OFF" 1 "ON";

VAL_ 1016 UI_accFollowDistanceSetting 0 "1" 1 "2" 2 "3" 3 "4" 4 "5" 5 "6" 6 "7" 7 "SNA";
VAL_ 1016 UI_autopilotControlRequest 0 "LEGACY_LAT_CTRL" 1 "NEXT_GEN_CTRL";
VAL_ 1016 UI_curvSpeedAdaptDisable 0 "ON" 1 "OFF";
VAL_ 1016 UI_curvatureDatabaseOnly 0 "OFF" 1 "ON";
VAL_ 1016 UI_driveOnMapsEnable 0 "OFF" 1 "ON";
VAL_ 1016 UI_drivingSide 0 "LEFT" 1 "RIGHT" 2 "UNKNOWN";
VAL_ 1016 UI_exceptionListEnable 0 "OFF" 1 "ON";
VAL_ 1016 UI_followNavRouteEnable 0 "OFF" 1 "ON";
VAL_ 1016 UI_forksEnable 0 "OFF" 1 "ON";
VAL_ 1016 UI_fuseHPPDisable 0 "ON" 1 "OFF";
VAL_ 1016 UI_fuseLanesDisable 0 "ON" 1 "OFF";
VAL_ 1016 UI_fuseVehiclesDisable 0 "ON" 1 "OFF";
VAL_ 1016 UI_handsOnRequirementDisable 0 "ON" 1 "OFF";
VAL_ 1016 UI_lssElkEnabled 0 "OFF" 1 "ON";
VAL_ 1016 UI_lssLdwEnabled 0 "OFF" 1 "ON";
VAL_ 1016 UI_lssLkaEnabled 0 "OFF" 1 "ON";
VAL_ 1016 UI_roadCheckDisable 0 "ON" 1 "OFF";
VAL_ 1016 UI_selfParkRequest 0 "NONE" 1 "SELF_PARK_FORWARD" 2 "SELF_PARK_REVERSE" 3 "ABORT" 4 "PRIME" 5 "PAUSE" 6 "RESUME" 7 "AUTO_SUMMON_FORWARD" 8 "AUTO_SUMMON_REVERSE" 9 "AUTO_SUMMON_CANCEL" 10 "AUTO_SUMMON_PRIMED" 15 "SNA";
VAL_ 1016 UI_source3D 0 "Z_FROM_MAP" 1 "Z_FROM_PATH_PREDICTION" 2 "XYZ_PREDICTION";
VAL_ 1016 UI_summonEntryType 0 "STRAIGHT" 1 "TURN_RIGHT" 2 "TURN_LEFT" 3 "SNA";
VAL_ 1016 UI_summonExitType 0 "STRAIGHT" 1 "TURN_RIGHT" 2 "TURN_LEFT" 3 "SNA";
VAL_ 1016 UI_summonReverseDist 63 "SNA";
VAL_ 1016 UI_ulcBlindSpotConfig 0 "STANDARD" 1 "AGGRESSIVE" 2 "MAD_MAX";
VAL_ 1016 UI_ulcSpeedConfig 0 "7MPH" 1 "10MPH" 2 "15MPH";
VAL_ 1016 UI_visionSpeedType 0 "DISABLED" 1 "ONE_SECOND" 2 "TWO_SECOND" 3 "OPTIMIZED";

VAL_ 568 UI_countryCode 0 "UNKNOWN" 1023 "SNA";
VAL_ 568 UI_mapSpeedLimit 0 "UNKNOWN" 1 "LESS_OR_EQ_5" 2 "LESS_OR_EQ_7" 3 "LESS_OR_EQ_10" 4 "LESS_OR_EQ_15" 5 "LESS_OR_EQ_20" 6 "LESS_OR_EQ_25" 7 "LESS_OR_EQ_30" 8 "LESS_OR_EQ_35" 9 "LESS_OR_EQ_40" 10 "LESS_OR_EQ_45" 11 "LESS_OR_EQ_50" 12 "LESS_OR_EQ_55" 13 "LESS_OR_EQ_60" 14 "LESS_OR_EQ_65" 15 "LESS_OR_EQ_70" 16 "LESS_OR_EQ_75" 17 "LESS_OR_EQ_80" 18 "LESS_OR_EQ_85" 19 "LESS_OR_EQ_90" 20 "LESS_OR_EQ_95" 21 "LESS_OR_EQ_100" 22 "LESS_OR_EQ_105" 23 "LESS_OR_EQ_110" 24 "LESS_OR_EQ_115" 25 "LESS_OR_EQ_120" 26 "LESS_OR_EQ_130" 27 "LESS_OR_EQ_140" 28 "LESS_OR_EQ_150" 29 "LESS_OR_EQ_160" 30 "UNLIMITED" 31 "SNA";
VAL_ 568 UI_mapSpeedLimitDependency 0 "NONE" 1 "SCHOOL" 2 "RAIN" 3 "SNOW" 4 "TIME" 5 "SEASON" 6 "LANE" 7 "SNA";
VAL_ 568 UI_mapSpeedLimitType 1 "REGULAR" 2 "ADVISORY" 3 "DEPENDENT" 4 "BUMPS" 7 "UNKNOWN_SNA";
VAL_ 568 UI_mapSpeedUnits 0 "MPH" 1 "KPH";
VAL_ 568 UI_nextBranchDist 31 "SNA";
VAL_ 568 UI_roadClass 0 "UNKNOWN_INVALID_SNA" 1 "CLASS_1_MAJOR" 2 "CLASS_2" 3 "CLASS_3" 4 "CLASS_4" 5 "CLASS_5" 6 "CLASS_6_MINOR";

VAL_ 536 UI_roadSign 0 "NONE" 1 "STOP_SIGN" 2 "TRAFFIC_LIGHT" 3 "SPEED_LIMIT" 4 "SPEED_SPLINE" 5 "SPLINE_ID_FULL" 255 "SNA";
VAL_ 536 UI_splineLocConfidence 0 "SNA";
VAL_ 536 UI_stopSignStopLineDist 1023 "SNA";
VAL_ 536 UI_stopSignStopLineConf 0 "SNA";
VAL_ 536 UI_trafficLightStopLineDist 1023 "SNA";
VAL_ 536 UI_trafficLightStopLineConf 0 "SNA";
VAL_ 536 UI_baseMapSpeedLimitMPS 255 "SNA";
VAL_ 536 UI_bottomQrtlFleetSpeedMPS 255 "SNA";
VAL_ 536 UI_topQrtlFleetSpeedMPS 255 "SNA";
VAL_ 536 UI_meanFleetSplineSpeedMPS 255 "SNA";
VAL_ 536 UI_medianFleetSpeedMPS 255 "SNA";
VAL_ 536 UI_meanFleetSplineAccelMPS2 255 "SNA";
VAL_ 536 UI_rampType 0 "NONE_SNA" 1 "ENTRANCE" 2 "EXIT" 3 "INTERCHANGE_ENTRANCE" 4 "INTERCHANGE_EXIT";
VAL_ 536 UI_currSplineIdFull 0 "SNA";

VAL_ 645 UI_driverProfileRecallIndex 0 "SNA" 1 "1" 2 "2" 3 "3" 4 "4" 5 "5";
VAL_ 645 UI_leftBackrestSwitchUp 0 "SNA" 1 "OFF" 2 "ON" 3 "FAULT";
VAL_ 645 UI_leftBackrestSwitchDown 0 "SNA" 1 "OFF" 2 "ON" 3 "FAULT";
VAL_ 645 UI_leftLiftSwitchUp 0 "SNA" 1 "OFF" 2 "ON" 3 "FAULT";
VAL_ 645 UI_leftLiftSwitchDown 0 "SNA" 1 "OFF" 2 "ON" 3 "FAULT";
VAL_ 645 UI_rightBackrestSwitchUp 0 "SNA" 1 "OFF" 2 "ON" 3 "FAULT";
VAL_ 645 UI_rightBackrestSwitchDown 0 "SNA" 1 "OFF" 2 "ON" 3 "FAULT";
VAL_ 645 UI_rightLiftSwitchUp 0 "SNA" 1 "OFF" 2 "ON" 3 "FAULT";
VAL_ 645 UI_rightLiftSwitchDown 0 "SNA" 1 "OFF" 2 "ON" 3 "FAULT";

VAL_ 984 UI_elevation 65535 "SNA";

VAL_ 1139 UI_nmKeepAwakeReason 0 "NONE_SNA" 1 "KEEPALIVEACTIVE" 2 "GUI_NEVER_SLEEP_SET" 3 "PM_CHECKING" 4 "UNKNOWN_REMOTE_REQUEST" 5 "MODEM_RESET" 6 "UPDATER" 7 "HERMES" 8 "AUTOFUSER" 9 "UPDATE_COUNTDOWN" 15 "MULTIPLE";

VAL_ 985 UI_mapSpeedLimitUnits 0 "MPH" 1 "KPH";
VAL_ 985 UI_userSpeedOffsetUnits 0 "MPH" 1 "KPH";

VAL_ 755 UI_hvacReqACDisable 0 "AUTO" 1 "OFF" 2 "ON";
VAL_ 755 UI_hvacReqAirDistributionMode 0 "AUTO" 1 "MANUAL_FLOOR" 2 "MANUAL_PANEL" 3 "MANUAL_PANEL_FLOOR" 4 "MANUAL_DEFROST" 5 "MANUAL_DEFROST_FLOOR" 6 "MANUAL_DEFROST_PANEL" 7 "MANUAL_DEFROST_PANEL_FLOOR";
VAL_ 755 UI_hvacReqBlowerSegment 0 "OFF" 1 "1" 2 "2" 3 "3" 4 "4" 5 "5" 6 "6" 7 "7" 8 "8" 9 "9" 10 "10" 11 "AUTO";
VAL_ 755 UI_hvacReqManualDefogState 0 "NONE" 1 "DEFOG" 2 "DEFROST";
VAL_ 755 UI_hvacReqRecirc 0 "AUTO" 1 "RECIRC" 2 "FRESH";
VAL_ 755 UI_hvacReqSecondRowState 0 "AUTO" 1 "OFF" 2 "LOW" 3 "MED" 4 "HIGH";
VAL_ 755 UI_hvacReqTempSetpointLeft 0 "LO" 26 "HI";
VAL_ 755 UI_hvacReqTempSetpointRight 0 "LO" 26 "HI";
VAL_ 755 UI_hvacReqUserPowerState 0 "OFF" 1 "ON" 2 "PRECONDITION" 3 "OVERHEAT_PROTECT_FANONLY" 4 "OVERHEAT_PROTECT";

VAL_ 79 UI_gpsAccuracy 127 "SNA";

VAL_ 1011 UI_odometer 16777215 "SNA";

VAL_ 787 UI_creepTorque 0 "OFF" 1 "ON";
VAL_ 787 UI_limitMode 0 "NORMAL" 1 "VALET" 2 "FACTORY";
VAL_ 787 UI_motorOnMode 0 "NORMAL" 1 "FRONT_ONLY" 2 "REAR_ONLY";
VAL_ 787 UI_pedalMap 0 "CHILL" 1 "SPORT";
VAL_ 787 UI_speedLimit 255 "SNA";
VAL_ 787 UI_systemPowerLimit 31 "SNA";
VAL_ 787 UI_systemTorqueLimit 63 "SNA";
VAL_ 787 UI_trackModeRequest 0 "IDLE" 1 "ON" 2 "OFF";
VAL_ 787 UI_wasteMode 0 "NONE" 1 "PARTIAL" 2 "FULL";
VAL_ 787 UI_wasteModeRegenLimit 0 "MAX" 1 "30A" 2 "10A" 3 "0A";

VAL_ 698 UI_radarTargetDx 255 "NO_OBJECT";
VAL_ 698 UI_radarTargetDxEnd 255 "NO_OBJECT";

VAL_ 632 UI_roadCurvHealth 0 "UNAVAILABLE" 1 "DEGRADED" 2 "AVAILABLE" 3 "DATABASE";

VAL_ 723 UI_isSunUp 0 "DOWN" 1 "UP" 3 "SNA";
VAL_ 723 UI_solarAzimuthAngle -32768 "SNA";
VAL_ 723 UI_solarAzimuthAngleCarRef 255 "SNA";
VAL_ 723 UI_solarElevationAngle 127 "SNA";

VAL_ 851 UI_autopilotTrial 0 "NONE" 1 "START" 2 "STOP" 3 "ACTIVE";
VAL_ 851 UI_cellNetworkTechnology 0 "NONE" 1 "GPRS" 2 "EDGE" 3 "UMTS" 4 "HSDPA" 5 "HSUPA" 6 "HSPA" 7 "LTE" 15 "SNA";
VAL_ 851 UI_cellSignalBars 0 "ZERO" 1 "ONE" 2 "TWO" 3 "THREE" 4 "FOUR" 5 "FIVE" 7 "SNA";
VAL_ 851 UI_factoryReset 0 "NONE_SNA" 1 "DEVELOPER" 2 "DIAGNOSTIC" 3 "CUSTOMER";

VAL_ 856 UI_TPMSLearnIDMode 0 "NO_ID_LEARN_FUNCTION" 1 "AUTO_LEARN_ACTIVE_BY_MANUAL" 2 "AUTO_LOCATION_ACTIVE_BY_MANUAL" 3 "AUTO_LEARN_ACTIVE_AFTER_PWR" 4 "AUTO_LOCATION_ACTIVE_AFTER_PWR";
VAL_ 856 UI_TPMSMode 0 "UNUSED_MODE" 1 "NORMAL_MODE" 2 "PERFORMANCE_MODE";
VAL_ 856 UI_sizeOfWheelSelect 0 "UNUSED" 1 "18_INCH_WHEEL" 2 "19_INCH_WHEEL";

VAL_ 627 UI_displayBrightnessLevel 255 "SNA";
VAL_ 627 UI_domeLightSwitch 0 "OFF" 1 "ON" 2 "AUTO";
VAL_ 627 UI_driveStateRequest 0 "IDLE" 1 "START";
VAL_ 627 UI_frontLeftSeatHeatReq 0 "OFF" 1 "LEVEL1" 2 "LEVEL2" 3 "LEVEL3";
VAL_ 627 UI_frontRightSeatHeatReq 0 "OFF" 1 "LEVEL1" 2 "LEVEL2" 3 "LEVEL3";
VAL_ 627 UI_lightSwitch 0 "AUTO_SNA" 1 "ON" 2 "PARKING" 3 "OFF";
VAL_ 627 UI_lockRequest 0 "IDLE" 1 "LOCK" 2 "UNLOCK" 3 "REMOTE_UNLOCK" 4 "REMOTE_LOCK" 7 "SNA";
VAL_ 627 UI_mirrorFoldRequest 0 "IDLE" 1 "RETRACT" 2 "PRESENT" 3 "SNA";
VAL_ 627 UI_rearCenterSeatHeatReq 0 "OFF" 1 "LEVEL1" 2 "LEVEL2" 3 "LEVEL3";
VAL_ 627 UI_rearLeftSeatHeatReq 0 "OFF" 1 "LEVEL1" 2 "LEVEL2" 3 "LEVEL3";
VAL_ 627 UI_rearRightSeatHeatReq 0 "OFF" 1 "LEVEL1" 2 "LEVEL2" 3 "LEVEL3";
VAL_ 627 UI_remoteClosureRequest 0 "IDLE" 1 "REAR_TRUNK_MOVE" 2 "FRONT_TRUNK_MOVE" 3 "SNA";
VAL_ 627 UI_remoteStartRequest 0 "IDLE" 1 "START" 4 "SNA";
VAL_ 627 UI_steeringBacklightEnabled 0 "DISABLED" 1 "ENABLED";
VAL_ 627 UI_steeringButtonMode 0 "OFF" 1 "STEERING_COLUMN_ADJ" 2 "MIRROR_LEFT" 3 "MIRROR_RIGHT" 4 "HEADLIGHT_LEFT" 5 "HEADLIGHT_RIGHT";
VAL_ 627 UI_wiperMode 0 "SNA" 1 "SERVICE" 2 "NORMAL" 3 "PARK";
VAL_ 627 UI_wiperRequest 0 "SNA" 1 "OFF" 2 "AUTO" 3 "SLOW_INTERMITTENT" 4 "FAST_INTERMITTENT" 5 "SLOW_CONTINUOUS" 6 "FAST_CONTINUOUS";

VAL_ 644 UI_factoryMode 0 "DISABLED" 1 "ENABLED";
VAL_ 644 UI_serviceMode 0 "DISABLED" 1 "ENABLED";
VAL_ 644 UI_showroomMode 0 "DISABLED" 1 "ENABLED";
VAL_ 644 UI_transportMode 0 "DISABLED" 1 "ENABLED";

VAL_ 595 UI_ventPanelLeftLateralMode 0 "SINGLE" 1 "SPLIT";
VAL_ 595 UI_ventPanelRightLateralMode 0 "SINGLE" 1 "SPLIT";

VAL_ 609 VCFRONT_IBSTemperature 32767 "VCFRONT_IBS_TEMPERATURE_SNA";

VAL_ 545 VCFRONT_LVPowerStateIndex 0 "Mux0" 1 "Mux1";
VAL_ 545 VCFRONT_vehiclePowerState 0 "OFF" 1 "CONDITIONING" 2 "ACCESSORY" 3 "DRIVE";
VAL_ 545 VCFRONT_parkLVState 0 "OFF" 1 "ON" 2 "GOING_DOWN" 3 "FAULT";
VAL_ 545 VCFRONT_espLVState 0 "OFF" 1 "ON" 2 "GOING_DOWN" 3 "FAULT";
VAL_ 545 VCFRONT_radcLVState 0 "OFF" 1 "ON" 2 "GOING_DOWN" 3 "FAULT";
VAL_ 545 VCFRONT_hvacCompLVState 0 "OFF" 1 "ON" 2 "GOING_DOWN" 3 "FAULT";
VAL_ 545 VCFRONT_ptcLVRequest 0 "OFF" 1 "ON" 2 "GOING_DOWN" 3 "FAULT";
VAL_ 545 VCFRONT_sccmLVRequest 0 "OFF" 1 "ON" 2 "GOING_DOWN" 3 "FAULT";
VAL_ 545 VCFRONT_tpmsLVRequest 0 "OFF" 1 "ON" 2 "GOING_DOWN" 3 "FAULT";
VAL_ 545 VCFRONT_rcmLVRequest 0 "OFF" 1 "ON" 2 "GOING_DOWN" 3 "FAULT";
VAL_ 545 VCFRONT_iBoosterLVState 0 "OFF" 1 "ON" 2 "GOING_DOWN" 3 "FAULT";
VAL_ 545 VCFRONT_tunerLVRequest 0 "OFF" 1 "ON" 2 "GOING_DOWN" 3 "FAULT";
VAL_ 545 VCFRONT_amplifierLVRequest 0 "OFF" 1 "ON" 2 "GOING_DOWN" 3 "FAULT";
VAL_ 545 VCFRONT_das1HighCurrentLVState 0 "OFF" 1 "ON" 2 "GOING_DOWN" 3 "FAULT";
VAL_ 545 VCFRONT_das2HighCurrentLVState 0 "OFF" 1 "ON" 2 "GOING_DOWN" 3 "FAULT";
VAL_ 545 VCFRONT_diLVRequest 0 "OFF" 1 "ON" 2 "GOING_DOWN" 3 "FAULT";
VAL_ 545 VCFRONT_disLVState 0 "OFF" 1 "ON" 2 "GOING_DOWN" 3 "FAULT";
VAL_ 545 VCFRONT_oilPumpFrontLVState 0 "OFF" 1 "ON" 2 "GOING_DOWN" 3 "FAULT";
VAL_ 545 VCFRONT_oilPumpRearLVRequest 0 "OFF" 1 "ON" 2 "GOING_DOWN" 3 "FAULT";
VAL_ 545 VCFRONT_ocsLVRequest 0 "OFF" 1 "ON" 2 "GOING_DOWN" 3 "FAULT";
VAL_ 545 VCFRONT_vcleftHiCurrentLVState 0 "OFF" 1 "ON" 2 "GOING_DOWN" 3 "FAULT";
VAL_ 545 VCFRONT_vcrightHiCurrentLVState 0 "OFF" 1 "ON" 2 "GOING_DOWN" 3 "FAULT";
VAL_ 545 VCFRONT_uiHiCurrentLVState 0 "OFF" 1 "ON" 2 "GOING_DOWN" 3 "FAULT";
VAL_ 545 VCFRONT_uiAudioLVState 0 "OFF" 1 "ON" 2 "GOING_DOWN" 3 "FAULT";
VAL_ 545 VCFRONT_cpLVRequest 0 "OFF" 1 "ON" 2 "GOING_DOWN" 3 "FAULT";
VAL_ 545 VCFRONT_epasLVState 0 "OFF" 1 "ON" 2 "GOING_DOWN" 3 "FAULT";
VAL_ 545 VCFRONT_hvcLVRequest 0 "OFF" 1 "ON" 2 "GOING_DOWN" 3 "FAULT";
VAL_ 545 VCFRONT_tasLVState 0 "OFF" 1 "ON" 2 "GOING_DOWN" 3 "FAULT";
VAL_ 545 VCFRONT_pcsLVState 0 "OFF" 1 "ON" 2 "GOING_DOWN" 3 "FAULT";

VAL_ 832 VCFRONT_matrixIndex 0 "AlertMatrix0" 1 "AlertMatrix1" 2 "AlertMatrix2" 3 "AlertMatrix3" 4 "AlertMatrix4";

VAL_ 577 VCFRONT_coolantAirPurgeBatState 0 "INACTIVE" 1 "ACTIVE" 2 "COMPLETE" 3 "INTERRUPTED" 4 "PENDING";
VAL_ 577 VCFRONT_coolantFlowBatReason 0 "NONE" 1 "COOLANT_AIR_PURGE" 2 "NO_FLOW_REQ" 3 "OVERRIDE_BATT" 4 "ACTIVE_MANAGER_BATT" 5 "PASSIVE_MANAGER_BATT" 6 "BMS_FLOW_REQ" 7 "DAS_FLOW_REQ" 8 "OVERRIDE_PT" 9 "ACTIVE_MANAGER_PT" 10 "PASSIVE_MANAGER_PT" 11 "PCS_FLOW_REQ" 12 "DI_FLOW_REQ" 13 "DIS_FLOW_REQ";
VAL_ 577 VCFRONT_coolantFlowPTReason 0 "NONE" 1 "COOLANT_AIR_PURGE" 2 "NO_FLOW_REQ" 3 "OVERRIDE_BATT" 4 "ACTIVE_MANAGER_BATT" 5 "PASSIVE_MANAGER_BATT" 6 "BMS_FLOW_REQ" 7 "DAS_FLOW_REQ" 8 "OVERRIDE_PT" 9 "ACTIVE_MANAGER_PT" 10 "PASSIVE_MANAGER_PT" 11 "PCS_FLOW_REQ" 12 "DI_FLOW_REQ" 13 "DIS_FLOW_REQ";
VAL_ 577 VCFRONT_wasteHeatRequestType 0 "NONE" 1 "PARTIAL" 2 "FULL";

VAL_ 753 VCFRONT_eFuseDebugStatusIndex 0 "VCRIGHT" 1 "VCLEFT" 2 "PCS" 3 "IBOOSTER" 4 "EPAS3P" 5 "EPAS3S" 6 "ESP_MOTOR" 7 "ESP_VALVE" 8 "AUTOPILOT_1" 9 "AUTOPILOT_2" 10 "SLEEP_BYPASS" 11 "UI" 12 "HEADLAMPS" 13 "VBAT_FUSED_HIGH_CURRENT" 14 "PUMPS" 15 "RAILS_A_B" 16 "MISC_RAILS" 17 "INVALID";
VAL_ 753 VCFRONT_rightControllerState 0 "OFF" 1 "ON" 2 "LOCKED_OUT";
VAL_ 753 VCFRONT_vcrightSelfTestResult 0 "NOT_RUN" 1 "PASSED" 2 "FAILED_EFUSE_OUTPUT_SHORT" 3 "FAILED_POWER_FET_STUCK_ON" 4 "FAILED_ENABLE_LOW_MALFUNCTION" 5 "FAILED_POWER_FET_CHANNEL_OPEN" 6 "FAILED_ENABLE_HIGH_MALFUNCTION" 7 "FAILED_TURN_OFF_PATH_TOO_SLOW" 8 "FAILED_NOT_LATCHED" 9 "SKIPPED";
VAL_ 753 VCFRONT_leftControllerState 0 "OFF" 1 "ON" 2 "LOCKED_OUT";
VAL_ 753 VCFRONT_vcleftSelfTestResult 0 "NOT_RUN" 1 "PASSED" 2 "FAILED_EFUSE_OUTPUT_SHORT" 3 "FAILED_POWER_FET_STUCK_ON" 4 "FAILED_ENABLE_LOW_MALFUNCTION" 5 "FAILED_POWER_FET_CHANNEL_OPEN" 6 "FAILED_ENABLE_HIGH_MALFUNCTION" 7 "FAILED_TURN_OFF_PATH_TOO_SLOW" 8 "FAILED_NOT_LATCHED" 9 "SKIPPED";
VAL_ 753 VCFRONT_PCSState 0 "OFF" 1 "ON" 2 "LOCKED_OUT";
VAL_ 753 VCFRONT_pcsSelfTestResult 0 "NOT_RUN" 1 "PASSED" 2 "FAILED_EFUSE_OUTPUT_SHORT" 3 "FAILED_POWER_FET_STUCK_ON" 4 "FAILED_ENABLE_LOW_MALFUNCTION" 5 "FAILED_POWER_FET_CHANNEL_OPEN" 6 "FAILED_ENABLE_HIGH_MALFUNCTION" 7 "FAILED_TURN_OFF_PATH_TOO_SLOW" 8 "FAILED_NOT_LATCHED" 9 "SKIPPED";
VAL_ 753 VCFRONT_iBoosterState 0 "OFF" 1 "ON" 2 "LOCKED_OUT";
VAL_ 753 VCFRONT_iBoosterSelfTestResult 0 "NOT_RUN" 1 "PASSED" 2 "FAILED_EFUSE_OUTPUT_SHORT" 3 "FAILED_POWER_FET_STUCK_ON" 4 "FAILED_ENABLE_LOW_MALFUNCTION" 5 "FAILED_POWER_FET_CHANNEL_OPEN" 6 "FAILED_ENABLE_HIGH_MALFUNCTION" 7 "FAILED_TURN_OFF_PATH_TOO_SLOW" 8 "FAILED_NOT_LATCHED" 9 "SKIPPED";
VAL_ 753 VCFRONT_EPAS3PState 0 "OFF" 1 "ON" 2 "LOCKED_OUT";
VAL_ 753 VCFRONT_EPAS3PSelfTestResult 0 "NOT_RUN" 1 "PASSED" 2 "FAILED_EFUSE_OUTPUT_SHORT" 3 "FAILED_POWER_FET_STUCK_ON" 4 "FAILED_ENABLE_LOW_MALFUNCTION" 5 "FAILED_POWER_FET_CHANNEL_OPEN" 6 "FAILED_ENABLE_HIGH_MALFUNCTION" 7 "FAILED_TURN_OFF_PATH_TOO_SLOW" 8 "FAILED_NOT_LATCHED" 9 "SKIPPED";
VAL_ 753 VCFRONT_EPAS3SState 0 "OFF" 1 "ON" 2 "LOCKED_OUT";
VAL_ 753 VCFRONT_EPAS3SSelfTestResult 0 "NOT_RUN" 1 "PASSED" 2 "FAILED_EFUSE_OUTPUT_SHORT" 3 "FAILED_POWER_FET_STUCK_ON" 4 "FAILED_ENABLE_LOW_MALFUNCTION" 5 "FAILED_POWER_FET_CHANNEL_OPEN" 6 "FAILED_ENABLE_HIGH_MALFUNCTION" 7 "FAILED_TURN_OFF_PATH_TOO_SLOW" 8 "FAILED_NOT_LATCHED" 9 "SKIPPED";
VAL_ 753 VCFRONT_ESPMotorState 0 "OFF" 1 "ON" 2 "LOCKED_OUT";
VAL_ 753 VCFRONT_ESPMotorSelfTestResult 0 "NOT_RUN" 1 "PASSED" 2 "FAILED_EFUSE_OUTPUT_SHORT" 3 "FAILED_POWER_FET_STUCK_ON" 4 "FAILED_ENABLE_LOW_MALFUNCTION" 5 "FAILED_POWER_FET_CHANNEL_OPEN" 6 "FAILED_ENABLE_HIGH_MALFUNCTION" 7 "FAILED_TURN_OFF_PATH_TOO_SLOW" 8 "FAILED_NOT_LATCHED" 9 "SKIPPED";
VAL_ 753 VCFRONT_ESPValveState 0 "OFF" 1 "ON" 2 "LOCKED_OUT";
VAL_ 753 VCFRONT_autopilot1State 0 "OFF" 1 "ON" 2 "LOCKED_OUT";
VAL_ 753 VCFRONT_autopilot2State 0 "OFF" 1 "ON" 2 "LOCKED_OUT";
VAL_ 753 VCFRONT_headlampLeftVoltage 255 "SNA";
VAL_ 753 VCFRONT_headlampRightVoltage 255 "SNA";
VAL_ 753 VCFRONT_headlampLeftTemperature -128 "SNA";
VAL_ 753 VCFRONT_headlampRightTemperature -128 "SNA";
VAL_ 753 VCFRONT_vbatFusedSelfTestResult 0 "NOT_RUN" 1 "PASSED" 2 "FAILED_EFUSE_OUTPUT_SHORT" 3 "FAILED_POWER_FET_STUCK_ON" 4 "FAILED_ENABLE_LOW_MALFUNCTION" 5 "FAILED_POWER_FET_CHANNEL_OPEN" 6 "FAILED_ENABLE_HIGH_MALFUNCTION" 7 "FAILED_TURN_OFF_PATH_TOO_SLOW" 8 "FAILED_NOT_LATCHED" 9 "SKIPPED";

VAL_ 769 VCFRONT_infoIndex 0 "DEPRECATED_0" 1 "DEPRECATED_1" 2 "DEPRECATED_2" 3 "DEPRECATED_3" 4 "DEPRECATED_4" 5 "DEPRECATED_5" 6 "DEPRECATED_6" 7 "DEPRECATED_7" 8 "DEPRECATED_8" 9 "DEPRECATED_9" 10 "BUILD_HWID_COMPONENTID" 11 "PCBAID_ASSYID_USAGEID" 13 "APP_CRC" 14 "BOOTLOADER_SVN" 15 "BOOTLOADER_CRC" 16 "SUBCOMPONENT1" 17 "APP_GITHASH" 18 "BOOTLOADER_GITHASH" 19 "VERSION_DEPRECATED" 20 "UDS_PROTOCOL_BOOTCRC" 23 "SUBCOMPONENT2" 24 "SUBCOMPONENT3" 31 "SUBCOMPONENT4" 255 "END";
VAL_ 769 VCFRONT_infoBuildType 0 "UNKNOWN_BUILD" 1 "PLATFORM_BUILD" 2 "LOCAL_BUILD" 3 "TRACEABLE_CI_BUILD" 4 "MFG_BUILD";
VAL_ 769 VCFRONT_infoAssemblyId 1 "ASSEMBLY1" 255 "ASSEMBLY_SNA";

VAL_ 1009 VCFRONT_DRLLeftStatus 0 "OFF" 1 "ON" 2 "FAULT" 3 "SNA";
VAL_ 1009 VCFRONT_DRLRightStatus 0 "OFF" 1 "ON" 2 "FAULT" 3 "SNA";
VAL_ 1009 VCFRONT_ambientLightingBrightnes 255 "SNA";
VAL_ 1009 VCFRONT_fogLeftStatus 0 "OFF" 1 "ON" 2 "FAULT" 3 "SNA";
VAL_ 1009 VCFRONT_fogRightStatus 0 "OFF" 1 "ON" 2 "FAULT" 3 "SNA";
VAL_ 1009 VCFRONT_hazardLightRequest 0 "NONE" 1 "BUTTON" 2 "LOCK" 3 "UNLOCK" 4 "MISLOCK" 5 "CRASH" 6 "CAR_ALARM" 7 "DAS";
VAL_ 1009 VCFRONT_highBeamLeftStatus 0 "OFF" 1 "ON" 2 "FAULT" 3 "SNA";
VAL_ 1009 VCFRONT_highBeamRightStatus 0 "OFF" 1 "ON" 2 "FAULT" 3 "SNA";
VAL_ 1009 VCFRONT_indicatorLeftRequest 0 "OFF" 1 "ACTIVE_LOW" 2 "ACTIVE_HIGH";
VAL_ 1009 VCFRONT_indicatorRightRequest 0 "OFF" 1 "ACTIVE_LOW" 2 "ACTIVE_HIGH";
VAL_ 1009 VCFRONT_lowBeamLeftStatus 0 "OFF" 1 "ON" 2 "FAULT" 3 "SNA";
VAL_ 1009 VCFRONT_lowBeamRightStatus 0 "OFF" 1 "ON" 2 "FAULT" 3 "SNA";
VAL_ 1009 VCFRONT_parkLeftStatus 0 "OFF" 1 "ON" 2 "FAULT" 3 "SNA";
VAL_ 1009 VCFRONT_parkRightStatus 0 "OFF" 1 "ON" 2 "FAULT" 3 "SNA";
VAL_ 1009 VCFRONT_sideMarkersStatus 0 "OFF" 1 "ON" 2 "FAULT" 3 "SNA";
VAL_ 1009 VCFRONT_sideRepeaterLeftStatus 0 "OFF" 1 "ON" 2 "FAULT" 3 "SNA";
VAL_ 1009 VCFRONT_sideRepeaterRightStatus 0 "OFF" 1 "ON" 2 "FAULT" 3 "SNA";
VAL_ 1009 VCFRONT_simLatchingStalk 0 "IDLE" 1 "LEFT" 2 "RIGHT" 3 "SNA";
VAL_ 1009 VCFRONT_switchLightingBrightness 255 "SNA";
VAL_ 1009 VCFRONT_turnSignalLeftStatus 0 "OFF" 1 "ON" 2 "FAULT" 3 "SNA";
VAL_ 1009 VCFRONT_turnSignalRightStatus 0 "OFF" 1 "ON" 2 "FAULT" 3 "SNA";

VAL_ 705 VCFRONT_logging10HzIndex 0 "COOLANT_PUMPS" 1 "THERMAL_FAN" 2 "FIVE_WAY_VALVE" 3 "REFRIGERANT_LV8907" 4 "COMPRESSOR" 5 "EXV_EVAP_SOLENOID_AIRFLOW" 6 "END";
VAL_ 705 VCFRONT_pumpBatteryRPMTarget 1023 "SNA";
VAL_ 705 VCFRONT_pumpPowertrainRPMTarget 1023 "SNA";
VAL_ 705 VCFRONT_radiatorFanRPMTarget 1023 "SNA";
VAL_ 705 VCFRONT_coolantTempBasedMode 0 "SERIES" 1 "PARALLEL";
VAL_ 897 VCFRONT_tempRefrigSuction 255 "SNA";
VAL_ 705 VCFRONT_tempDischargeSimulated 2047 "SNA";
VAL_ 705 VCFRONT_exvMotorState 0 "UNPOWERED" 1 "HARD_RESET_SETUP" 2 "HARD_RESET" 3 "INIT_SPI" 4 "SPI_ERROR" 5 "ENABLE_MOTOR" 6 "READY" 7 "STALL" 8 "FAULT_SHORT_COIL" 9 "FAULT_OPEN_COIL" 10 "DRIVER_FAULT" 11 "SPI_COMMS_DOWN";

VAL_ 897 VCFRONT_logging1HzIndex 0 "COOLANT" 1 "CONDENSER_LOUVER_IC" 2 "ACTIVE_LOUVER_AND_BRUSHLESS_FETS" 3 "FIVE_WAY_VALVE" 4 "END";
VAL_ 897 VCFRONT_modeTransitionID 0 "PARALLEL_F1_noFlowRequest" 1 "SERIES_F2_faultPumps" 2 "SERIES_1_drive_batteryWantsCool" 3 "SERIES_2_drive_batteryNeedsHeat" 4 "SERIES_3_drive_batteryWantsHeat" 5 "PARALLEL_2_drive_batteryWantsHeat" 6 "PARALLEL_3_drive_batteryWantsCool" 7 "PARALLEL_4_drive_batteryNeedsCool" 8 "SERIES_4_charge_batteryNeedsHeat" 9 "SERIES_5_charge_batteryWantsHeat" 10 "PARALLEL_5_charge_batteryWantsHeat" 11 "PARALLEL_6_charge_batteryWantsCool" 12 "SERIES_6_fastCharge_batteryNeedsHeat" 13 "SERIES_7_fastCharge_batteryWantsCool" 14 "PARALLEL_7_fastCharge_batteryWantsCool" 15 "PARALLEL_8_fastCharge_batteryWantsHeat" 16 "SERIES_8_preConditioning_batteryNeedsHeat" 17 "SERIES_9_drive_driveUnitThermalLimiting" 18 "PARALLEL_9_drive_batteryThermalLimiting" 19 "INIT" 20 "OVERRIDE" 21 "UNDEFINED";
VAL_ 897 VCFRONT_modeDesired 0 "SERIES" 1 "PARALLEL";
VAL_ 705 VCFRONT_activeLouverMotorState 0 "UNPOWERED" 1 "INIT_I2C" 2 "INIT_EEPROM" 3 "I2C_ERROR" 4 "READY" 5 "BRAKE" 6 "STALL" 7 "FAULT_MOTOR_DISCONNECTED" 8 "DRIVER_FAULT";
VAL_ 705 VCFRONT_activeLouverState 0 "UNCALIBRATED" 1 "CALIB_CLOSE" 2 "CALIB_OPEN" 3 "READY" 4 "FAULTED";
VAL_ 897 VCFRONT_pumpBatteryFETTemp 255 "SNA";
VAL_ 897 VCFRONT_pumpPowertrainFETTemp 255 "SNA";
VAL_ 897 VCFRONT_radiatorFanFETTemp 255 "SNA";

VAL_ 801 VCFRONT_brakeFluidLevel 0 "SNA" 1 "LOW" 2 "NORMAL";
VAL_ 801 VCFRONT_coolantLevel 0 "NOT_OK" 1 "FILLED";
VAL_ 801 VCFRONT_tempAmbient 0 "SNA";
VAL_ 801 VCFRONT_tempAmbientFiltered 0 "SNA";
VAL_ 801 VCFRONT_tempCoolantBatInlet 1023 "SNA";
VAL_ 801 VCFRONT_tempCoolantPTInlet 2047 "SNA";
VAL_ 801 VCFRONT_washerFluidLevel 0 "SNA" 1 "LOW" 2 "NORMAL";

VAL_ 737 VCFRONT_statusIndex 0 "BODY_CONTROLS" 1 "VEHICLE_AND_RAILS" 2 "HOMELINK" 3 "REFRIGERANT_SYSTEM" 4 "LV_BATTERY_DEBUG" 5 "INVALID";
VAL_ 737 VCFRONT_frunkLatchStatus 0 "SNA" 1 "OPENED" 2 "CLOSED" 3 "CLOSING" 4 "OPENING" 5 "AJAR" 6 "TIMEOUT" 7 "DEFAULT" 8 "FAULT";
VAL_ 737 VCFRONT_wiperSpeed 0 "SNA" 1 "OFF" 2 "1" 3 "2" 4 "3" 5 "4" 6 "5" 7 "LOW" 8 "HIGH";
VAL_ 737 VCFRONT_wiperPosition 0 "SNA" 1 "SERVICE" 2 "DEPRESSED_PARK" 3 "DELAYED_REST" 4 "WIPING";
VAL_ 737 VCFRONT_wiperState 0 "SNA" 1 "SERVICE" 2 "FAULT" 3 "DELAYED_REST" 4 "PARK" 5 "WASH" 6 "MOMENTARY_WIPE" 7 "INTERMITTENT_HIGH" 8 "INTERMITTENT_LOW" 9 "CONT_FAST" 10 "CONT_SLOW" 11 "INT_AUTO_LOW" 12 "INT_AUTO_HIGH";
VAL_ 737 VCFRONT_crashDetectedType 0 "NONE" 1 "MINOR" 2 "SEVERE";
VAL_ 737 VCFRONT_crashState 0 "IDLE" 1 "MINOR" 2 "SEVERE";
VAL_ 737 VCFRONT_airCompressorStatus 0 "OFF" 1 "ON" 2 "TURNING_OFF" 3 "TURNING_ON" 4 "FAULT" 5 "RETRY_AVAILABLE" 7 "SNA";
VAL_ 737 VCFRONT_iBoosterStateDBG 0 "OFF" 1 "ON" 2 "GOING_DOWN" 3 "WRITING_DATA_SHUTDOWN" 4 "FORCE_OFF";
VAL_ 737 VCFRONT_vehicleStatusDBG 0 "INIT" 1 "LOW_POWER_STANDBY" 2 "SILENT_WAKE" 3 "BATTERY_POST_WAKE" 4 "SYSTEM_CHECKS" 5 "SLEEP_SHUTDOWN" 6 "SLEEP_STANDBY" 7 "LV_SHUTDOWN" 8 "LV_AWAKE" 9 "HV_UP_STANDBY" 10 "ACCESSORY" 11 "ACCESSORY_PLUS" 12 "CONDITIONING" 13 "DRIVE" 14 "CRASH" 15 "OTA" 16 "TURN_ON_RAILS" 17 "RESET";
VAL_ 737 VCFRONT_batterySMState 0 "INIT" 1 "CHARGE" 2 "DISCHARGE" 3 "STANDBY" 4 "RESISTANCE_ESTIMATION" 5 "OTA_STANDBY" 6 "DISCONNECTED_BATTERY_TEST" 7 "FAULT";
VAL_ 737 VCFRONT_homelinkCommStatus 0 "SNA" 1 "OFF" 2 "ON" 3 "FAULT";
VAL_ 737 VCFRONT_pressureRefrigSuction 127 "SNA";
VAL_ 737 VCFRONT_pressureRefrigDischarge 255 "SNA";
VAL_ 737 VCFRONT_AS8510Voltage 4095 "SNA";

VAL_ 929 VCFRONT_12vStatusForDrive 0 "NOT_READY_FOR_DRIVE_12V" 1 "READY_FOR_DRIVE_12V" 2 "EXIT_DRIVE_REQUESTED_12V";
VAL_ 929 VCFRONT_2RowCenterUnbuckled 0 "NONE" 1 "OCCUPIED_AND_UNBUCKLED" 2 "SNA";
VAL_ 929 VCFRONT_2RowLeftUnbuckled 0 "NONE" 1 "OCCUPIED_AND_UNBUCKLED" 2 "SNA";
VAL_ 929 VCFRONT_2RowRightUnbuckled 0 "NONE" 1 "OCCUPIED_AND_UNBUCKLED" 2 "SNA";
VAL_ 929 VCFRONT_APGlassHeaterState 0 "SNA" 1 "ON" 2 "OFF" 3 "OFF_UNAVAILABLE" 4 "FAULT";
VAL_ 929 VCFRONT_diPowerOnState 0 "POWERED_OFF" 1 "POWERED_ON_FOR_POST_RUN" 2 "POWERED_ON_FOR_STATIONARY_HEAT" 3 "POWERED_ON_FOR_DRIVE" 4 "POWER_GOING_DOWN";
VAL_ 929 VCFRONT_driverBuckleStatus 0 "UNBUCKLED" 1 "BUCKLED";
VAL_ 929 VCFRONT_driverDoorStatus 0 "OPEN" 1 "CLOSED";
VAL_ 929 VCFRONT_driverUnbuckled 0 "NONE" 1 "OCCUPIED_AND_UNBUCKLED" 2 "SNA";
VAL_ 929 VCFRONT_passengerUnbuckled 0 "NONE" 1 "OCCUPIED_AND_UNBUCKLED" 2 "SNA";
VAL_ 929 VCFRONT_pcsEFuseVoltage 1023 "SNA";

VAL_ 553 SCCM_gearStalkStatus 0 "IDLE" 1 "UP_1" 2 "UP_2" 3 "DOWN_1" 4 "DOWN_2" 5 "SNA";
VAL_ 553 SCCM_parkButtonStatus 0 "NOT_PRESSED" 1 "1ST_DETENT" 2 "2ND_DETENT" 3 "SNA";
